VERSION "created by canmatrix"

NS_ :

BS_:

BU_: TCM iBooster HCU CIM SCM Right_Hand_Control Left_Hand_Control GPS VCM IC_2 XM GMRS Radio_CANtool Diagnostic_Tool_Digital_Wrench Information_System_Controller_1 STEERING_CONTROLLER VEHICLE_SECURITY RADIO_Hub ABS Battery_Management_Cntrl_2 Battery_Management_Cntrl_1 Auxiliary_Power_Unit_2 Auxiliary_Power_Unit_1 Electric_Propulsion_Cntrl_Unit_4 Electric_Propulsion_Cntrl_Unit_3 Electric_Propulsion_Cntrl_Unit_2 Electric_Propulsion_Cntrl_Unit_1 ECM IC

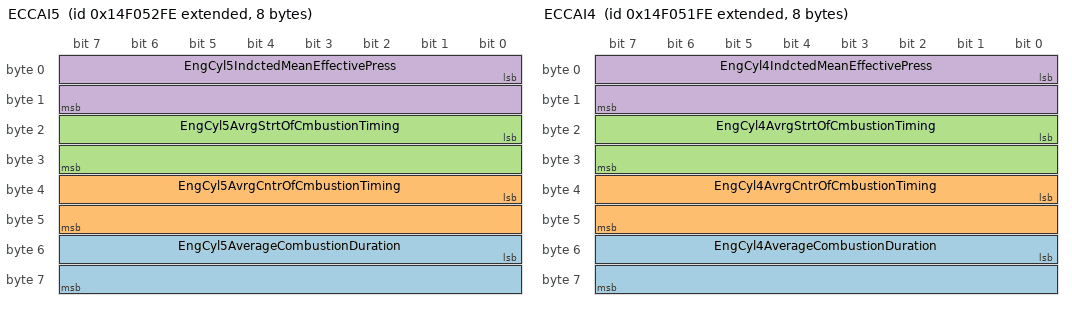
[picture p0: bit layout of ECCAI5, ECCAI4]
BO_ 2498777854 ECCAI5: 8 Vector__XXX
 SG_ EngCyl5AverageCombustionDuration : 48|16@1+ (0.0078125,0) [0.0|501.99] "deg" Vector__XXX
 SG_ EngCyl5AvrgCntrOfCmbustionTiming : 32|16@1+ (0.0078125,-250) [-250.0|250.992] "deg" Vector__XXX
 SG_ EngCyl5AvrgStrtOfCmbustionTiming : 16|16@1+ (0.0078125,-250) [-250.0|250.992] "deg" Vector__XXX
 SG_ EngCyl5IndctedMeanEffectivePress : 0|16@1+ (0.00012207,-1) [-1.0|6.84362793] "MPa" Vector__XXX

BO_ 2498777598 ECCAI4: 8 Vector__XXX
 SG_ EngCyl4AverageCombustionDuration : 48|16@1+ (0.0078125,0) [0.0|501.99] "deg" Vector__XXX
 SG_ EngCyl4AvrgCntrOfCmbustionTiming : 32|16@1+ (0.0078125,-250) [-250.0|250.992] "deg" Vector__XXX
 SG_ EngCyl4AvrgStrtOfCmbustionTiming : 16|16@1+ (0.0078125,-250) [-250.0|250.992] "deg" Vector__XXX
 SG_ EngCyl4IndctedMeanEffectivePress : 0|16@1+ (0.00012207,-1) [-1.0|6.84362793] "MPa" Vector__XXX

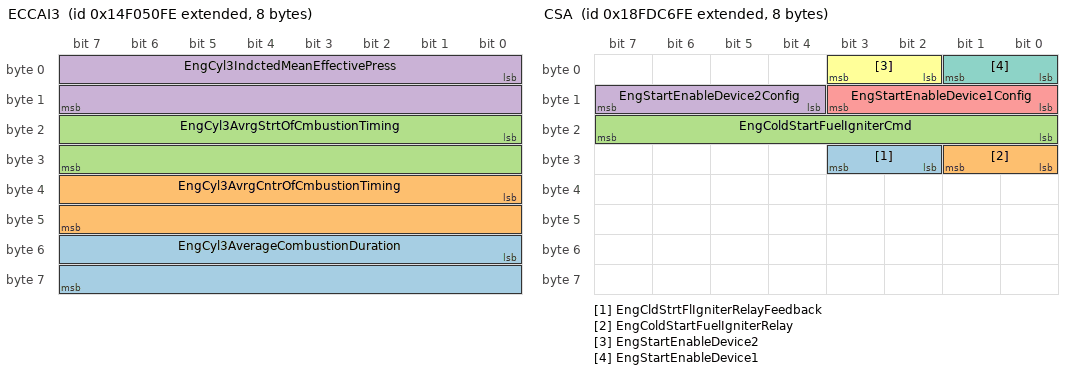
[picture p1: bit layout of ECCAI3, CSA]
BO_ 2498777342 ECCAI3: 8 Vector__XXX
 SG_ EngCyl3AverageCombustionDuration : 48|16@1+ (0.0078125,0) [0.0|501.99] "deg" Vector__XXX
 SG_ EngCyl3AvrgCntrOfCmbustionTiming : 32|16@1+ (0.0078125,-250) [-250.0|250.992] "deg" Vector__XXX
 SG_ EngCyl3AvrgStrtOfCmbustionTiming : 16|16@1+ (0.0078125,-250) [-250.0|250.992] "deg" Vector__XXX
 SG_ EngCyl3IndctedMeanEffectivePress : 0|16@1+ (0.00012207,-1) [-1.0|6.84362793] "MPa" Vector__XXX

BO_ 2566768382 CSA: 8 Vector__XXX
 SG_ EngCldStrtFlIgniterRelayFeedback : 26|2@1+ (1,0) [0.0|3.0] "" Vector__XXX
 SG_ EngColdStartFuelIgniterRelay : 24|2@1+ (1,0) [0.0|3.0] "" Vector__XXX
 SG_ EngColdStartFuelIgniterCmd : 16|8@1+ (0.4,0) [0.0|100.0] "%" Vector__XXX
 SG_ EngStartEnableDevice2Config : 12|4@1+ (1,0) [0.0|15.0] "" Vector__XXX
 SG_ EngStartEnableDevice1Config : 8|4@1+ (1,0) [0.0|15.0] "" Vector__XXX
 SG_ EngStartEnableDevice2 : 2|2@1+ (1,0) [0.0|3.0] "" Vector__XXX
 SG_ EngStartEnableDevice1 : 0|2@1+ (1,0) [0.0|3.0] "" Vector__XXX

BO_ 2566811902 CVW: 8 Vector__XXX
 SG_ PoweredVehicleWeight : 0|16@1+ (10,0) [0.0|642550.0] "kg" Vector__XXX
 SG_ GrossCombinationVehicleWeight : 16|16@1+ (10,0) [0.0|642550.0] "kg" Vector__XXX

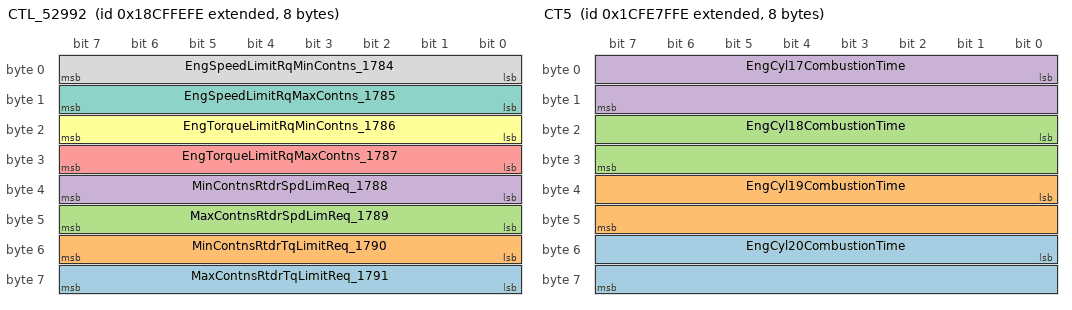
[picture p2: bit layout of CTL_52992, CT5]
BO_ 2563768062 CTL_52992: 8 Vector__XXX
 SG_ MaxContnsRtdrTqLimitReq_1791 : 56|8@1+ (1,-125) [-125.0|0.0] "%" Vector__XXX
 SG_ MinContnsRtdrTqLimitReq_1790 : 48|8@1+ (1,-125) [-125.0|0.0] "%" Vector__XXX
 SG_ MaxContnsRtdrSpdLimReq_1789 : 40|8@1+ (32,0) [0.0|8000.0] "rpm" Vector__XXX
 SG_ MinContnsRtdrSpdLimReq_1788 : 32|8@1+ (32,0) [0.0|8000.0] "rpm" Vector__XXX
 SG_ EngTorqueLimitRqMaxContns_1787 : 24|8@1+ (1,-125) [0.0|125.0] "%" Vector__XXX
 SG_ EngTorqueLimitRqMinContns_1786 : 16|8@1+ (1,-125) [0.0|125.0] "%" Vector__XXX
 SG_ EngSpeedLimitRqMaxContns_1785 : 8|8@1+ (32,0) [0.0|8000.0] "rpm" Vector__XXX
 SG_ EngSpeedLimitRqMinContns_1784 : 0|8@1+ (32,0) [0.0|8000.0] "rpm" Vector__XXX

BO_ 2633924862 CT6: 8 Vector__XXX
 SG_ EngAverageCombustionTime : 16|16@1+ (0.01,0) [0.0|642.55] "ms" Vector__XXX
 SG_ EngDesiredCombustionTime : 0|16@1+ (0.01,0) [0.0|642.55] "ms" Vector__XXX

BO_ 2633924606 CT5: 8 Vector__XXX
 SG_ EngCyl20CombustionTime : 48|16@1+ (0.01,0) [0.0|642.55] "ms" Vector__XXX
 SG_ EngCyl19CombustionTime : 32|16@1+ (0.01,0) [0.0|642.55] "ms" Vector__XXX
 SG_ EngCyl18CombustionTime : 16|16@1+ (0.01,0) [0.0|642.55] "ms" Vector__XXX
 SG_ EngCyl17CombustionTime : 0|16@1+ (0.01,0) [0.0|642.55] "ms" Vector__XXX

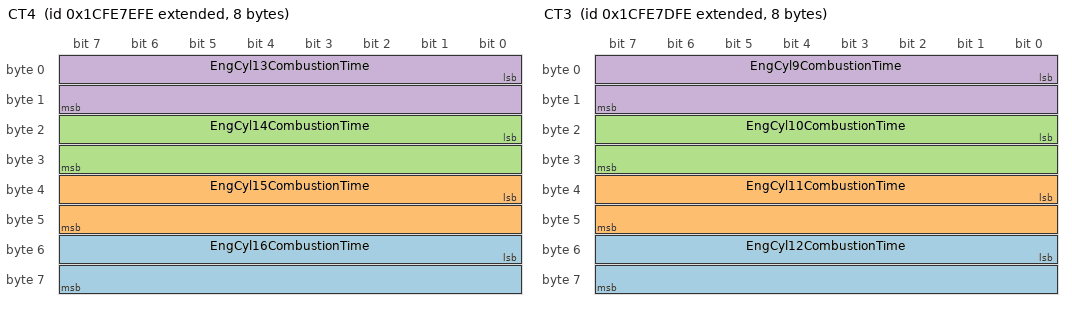
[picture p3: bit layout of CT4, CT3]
BO_ 2633924350 CT4: 8 Vector__XXX
 SG_ EngCyl16CombustionTime : 48|16@1+ (0.01,0) [0.0|642.55] "ms" Vector__XXX
 SG_ EngCyl15CombustionTime : 32|16@1+ (0.01,0) [0.0|642.55] "ms" Vector__XXX
 SG_ EngCyl14CombustionTime : 16|16@1+ (0.01,0) [0.0|642.55] "ms" Vector__XXX
 SG_ EngCyl13CombustionTime : 0|16@1+ (0.01,0) [0.0|642.55] "ms" Vector__XXX

BO_ 2633924094 CT3: 8 Vector__XXX
 SG_ EngCyl12CombustionTime : 48|16@1+ (0.01,0) [0.0|642.55] "ms" Vector__XXX
 SG_ EngCyl11CombustionTime : 32|16@1+ (0.01,0) [0.0|642.55] "ms" Vector__XXX
 SG_ EngCyl10CombustionTime : 16|16@1+ (0.01,0) [0.0|642.55] "ms" Vector__XXX
 SG_ EngCyl9CombustionTime : 0|16@1+ (0.01,0) [0.0|642.55] "ms" Vector__XXX

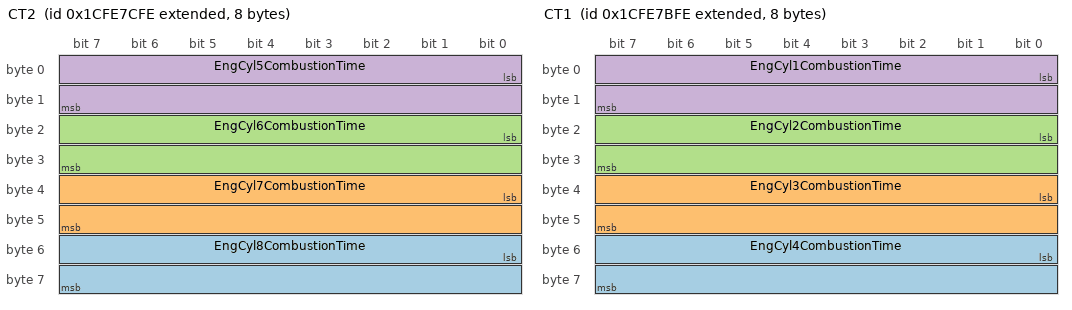
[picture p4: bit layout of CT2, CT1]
BO_ 2633923838 CT2: 8 Vector__XXX
 SG_ EngCyl8CombustionTime : 48|16@1+ (0.01,0) [0.0|642.55] "ms" Vector__XXX
 SG_ EngCyl7CombustionTime : 32|16@1+ (0.01,0) [0.0|642.55] "ms" Vector__XXX
 SG_ EngCyl6CombustionTime : 16|16@1+ (0.01,0) [0.0|642.55] "ms" Vector__XXX
 SG_ EngCyl5CombustionTime : 0|16@1+ (0.01,0) [0.0|642.55] "ms" Vector__XXX

BO_ 2633923582 CT1: 8 Vector__XXX
 SG_ EngCyl4CombustionTime : 48|16@1+ (0.01,0) [0.0|642.55] "ms" Vector__XXX
 SG_ EngCyl3CombustionTime : 32|16@1+ (0.01,0) [0.0|642.55] "ms" Vector__XXX
 SG_ EngCyl2CombustionTime : 16|16@1+ (0.01,0) [0.0|642.55] "ms" Vector__XXX
 SG_ EngCyl1CombustionTime : 0|16@1+ (0.01,0) [0.0|642.55] "ms" Vector__XXX

BO_ 2633878014 CMI: 8 Vector__XXX
 SG_ TotalCountOfConfigChangesMade : 0|16@1+ (1,0) [0.0|64255.0] "" Vector__XXX

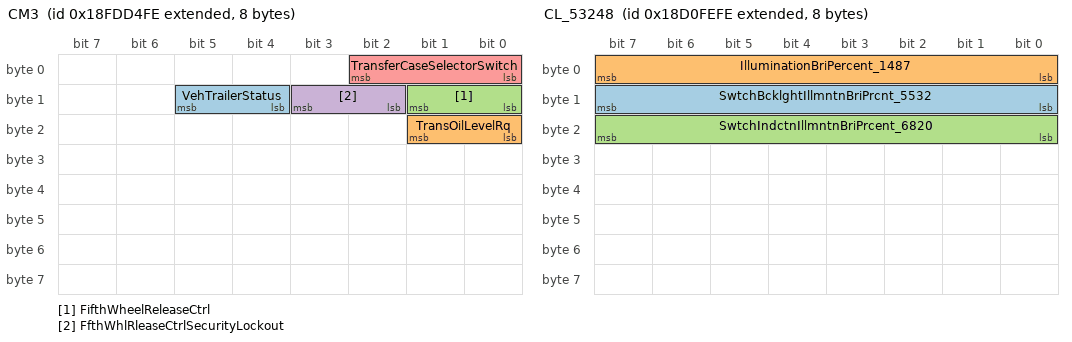
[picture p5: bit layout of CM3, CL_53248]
BO_ 2566771966 CM3: 8 Vector__XXX
 SG_ VehTrailerStatus : 12|2@1+ (1,0) [0.0|3.0] "" Vector__XXX
 SG_ TransOilLevelRq : 16|2@1+ (1,0) [0.0|3.0] "" Vector__XXX
 SG_ FifthWheelReleaseCtrl : 8|2@1+ (1,0) [0.0|3.0] "" Vector__XXX
 SG_ FfthWhlRleaseCtrlSecurityLockout : 10|2@1+ (1,0) [0.0|3.0] "" Vector__XXX
 SG_ TransferCaseSelectorSwitch : 0|3@1+ (1,0) [0.0|7.0] "" Vector__XXX

BO_ 2564882174 CM1_57344: 8 Vector__XXX
 SG_ SeldMaxVehSpdLimit_2596 : 56|8@1+ (1,0) [0.0|250.0] "" Vector__XXX
 SG_ ReqCabZoneHeating_1686 : 54|2@1+ (1,0) [0.0|3.0] "" Vector__XXX
 SG_ ReqEngZoneHeating_1685 : 52|2@1+ (1,0) [0.0|3.0] "" Vector__XXX
 SG_ AuxHeaterModeReq_1683 : 48|4@1+ (1,0) [0.0|15.0] "" Vector__XXX
 SG_ EngAutomaticStartEnableSw_1656 : 46|2@1+ (1,0) [0.0|3.0] "" Vector__XXX
 SG_ AtuomaticGearShiftingEnSw_1666 : 44|2@1+ (1,0) [0.0|3.0] "" Vector__XXX
 SG_ AFTRegenForceSw_3696 : 42|2@1+ (1,0) [0.0|3.0] "" Vector__XXX
 SG_ AFTRegenInhSw_3695 : 40|2@1+ (1,0) [0.0|3.0] "" Vector__XXX
 SG_ VehLmtngSpdGovrEnSw_1653 : 38|2@1+ (1,0) [0.0|3.0] "" Vector__XXX
 SG_ VehLmtngSpdGvrnrIncrementSw_1654 : 36|2@1+ (1,0) [0.0|3.0] "" Vector__XXX
 SG_ VehLmtngSpdGvrnrDecrementSw_1655 : 34|2@1+ (1,0) [0.0|3.0] "" Vector__XXX
 SG_ ParkBrakeCmd_5630 : 32|2@1+ (1,0) [0.0|3.0] "" Vector__XXX
 SG_ SeatBeltSwitch_1856 : 30|2@1+ (1,0) [0.0|3.0] "" Vector__XXX
 SG_ OperatorSeatDirSw_1714 : 28|2@1+ (1,0) [0.0|3.0] "" Vector__XXX
 SG_ BatteryMainSwitchHoldRq_1682 : 26|2@1+ (1,0) [0.0|3.0] "" Vector__XXX
 SG_ AuxHeaterCoolantPumpRq_1684 : 24|2@1+ (1,0) [0.0|3.0] "" Vector__XXX
 SG_ CabInteriorTempCmd_1691 : 8|16@1+ (0.03125,-273) [-273.0|1734.96875] "°C" Vector__XXX
 SG_ RequestedPercentFanSpeed_986 : 0|8@1+ (0.4,0) [0.0|100.0] "%" Vector__XXX

BO_ 2563833598 CL_53248: 8 Vector__XXX
 SG_ SwtchBcklghtIllmntnBriPrcnt_5532 : 8|8@1+ (0.4,0) [0.0|100.0] "%" Vector__XXX
 SG_ IlluminationBriPercent_1487 : 0|8@1+ (0.4,0) [0.0|100.0] "%" Vector__XXX
 SG_ SwtchIndctnIllmntnBriPrcent_6820 : 16|8@1+ (0.4,0) [0.0|100.0] "%" Vector__XXX

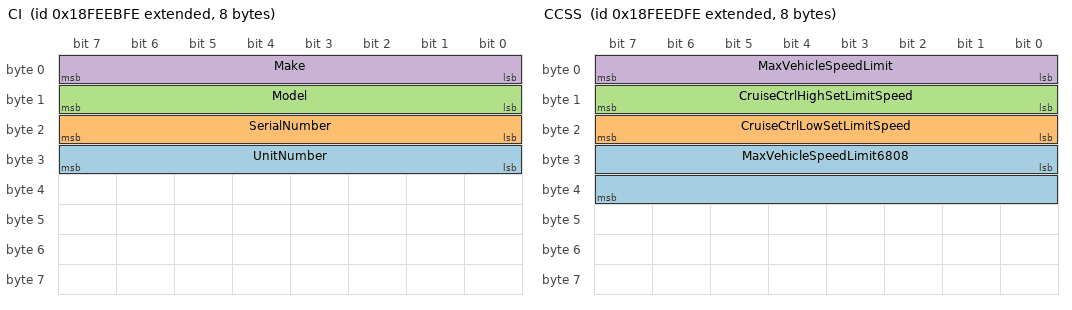
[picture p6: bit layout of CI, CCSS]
BO_ 2566843390 CI: 8 Vector__XXX
 SG_ UnitNumber : 24|8@1+ (1,0) [0.0|255.0] "" Vector__XXX
 SG_ SerialNumber : 16|8@1+ (1,0) [0.0|255.0] "" Vector__XXX
 SG_ Model : 8|8@1+ (1,0) [0.0|255.0] "" Vector__XXX
 SG_ Make : 0|8@1+ (1,0) [0.0|255.0] "" Vector__XXX

BO_ 2566844926 CCVS1: 8 Vector__XXX
 SG_ EngShutdownOverrideSwitch : 62|2@1+ (1,0) [0.0|3.0] "" Vector__XXX
 SG_ EngTestModeSwitch : 60|2@1+ (1,0) [0.0|3.0] "" Vector__XXX
 SG_ EngIdleDecrementSwitch : 58|2@1+ (1,0) [0.0|3.0] "" Vector__XXX
 SG_ EngIdleIncrementSwitch : 56|2@1+ (1,0) [0.0|3.0] "" Vector__XXX
 SG_ CruiseCtrlStates : 53|3@1+ (1,0) [0.0|7.0] "" Vector__XXX
 SG_ PTOGovernorState : 48|5@1+ (1,0) [0.0|31.0] "" Vector__XXX
 SG_ CruiseCtrlSetSpeed : 40|8@1+ (1,0) [0.0|250.0] "km/h" Vector__XXX
 SG_ CruiseCtrlAccelerateSwitch : 38|2@1+ (1,0) [0.0|3.0] "" Vector__XXX
 SG_ CruiseCtrlResumeSwitch : 36|2@1+ (1,0) [0.0|3.0] "" Vector__XXX
 SG_ CruiseCtrlCoastSwitch : 34|2@1+ (1,0) [0.0|3.0] "" Vector__XXX
 SG_ CruiseCtrlSetSwitch : 32|2@1+ (1,0) [0.0|3.0] "" Vector__XXX
 SG_ ClutchSwitch : 30|2@1+ (1,0) [0.0|3.0] "" Vector__XXX
 SG_ BrakeSwitch : 28|2@1+ (1,0) [0.0|3.0] "" Vector__XXX
 SG_ CruiseCtrlEnableSwitch : 26|2@1+ (1,0) [0.0|3.0] "" Vector__XXX
 SG_ CruiseCtrlActive : 24|2@1+ (1,0) [0.0|3.0] "" Vector__XXX
 SG_ WheelBasedVehicleSpeed : 8|16@1+ (0.00390625,0) [0.0|250.996] "km/h" Vector__XXX
 SG_ ParkBrakeReleaseInhibitRq : 6|2@1+ (1,0) [0.0|3.0] "" Vector__XXX
 SG_ CruiseCtrlPauseSwitch : 4|2@1+ (1,0) [0.0|3.0] "" Vector__XXX
 SG_ ParkingBrakeSwitch : 2|2@1+ (1,0) [0.0|3.0] "" Vector__XXX
 SG_ TwoSpeedAxleSwitch : 0|2@1+ (1,0) [0.0|3.0] "" Vector__XXX

BO_ 2566843902 CCSS: 8 Vector__XXX
 SG_ MaxVehicleSpeedLimit6808 : 24|16@1+ (0.00390625,0) [0.0|250.996] "km/h" Vector__XXX
 SG_ CruiseCtrlLowSetLimitSpeed : 16|8@1+ (1,0) [0.0|250.0] "km/h" Vector__XXX
 SG_ CruiseCtrlHighSetLimitSpeed : 8|8@1+ (1,0) [0.0|250.0] "km/h" Vector__XXX
 SG_ MaxVehicleSpeedLimit : 0|8@1+ (1,0) [0.0|250.0] "km/h" Vector__XXX

BO_ 2566809598 CCC: 8 Vector__XXX
 SG_ AuxHeaterMaxOutputPower : 0|16@1+ (2,0) [0.0|128510.0] "W" Vector__XXX

BO_ 2633940222 CBI: 16 Vector__XXX
 SG_ TripServiceBrakeApplications : 96|32@1+ (1,0) [0.0|4211081215.0] "appl" Vector__XXX
 SG_ TripServiceBrakeDistance : 64|32@1+ (0.125,0) [0.0|526385151.875] "km" Vector__XXX
 SG_ TripCompressionBrakeDistance : 32|32@1+ (0.125,0) [0.0|526385151.875] "km" Vector__XXX
 SG_ TotalCompressionBrakeDistance : 0|32@1+ (0.125,0) [0.0|526385151.875] "km" Vector__XXX

BO_ 2566775294 CACI: 8 Vector__XXX
 SG_ CbA_CRfrgrntCmpressorOutletPress : 0|8@1+ (16,0) [0.0|4000.0] "kPa" Vector__XXX

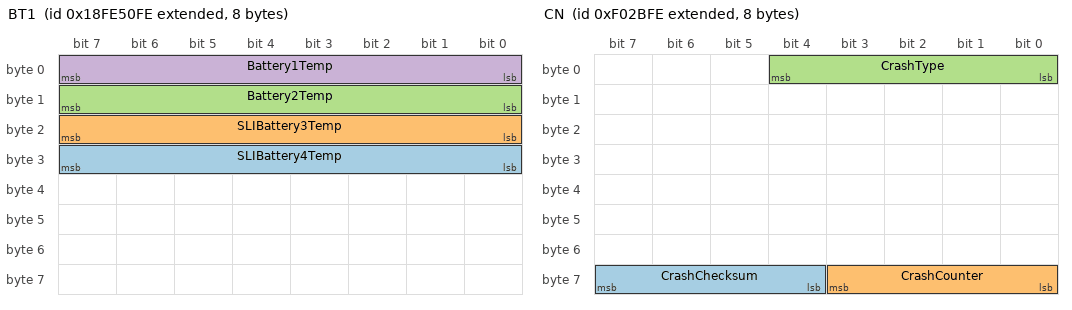
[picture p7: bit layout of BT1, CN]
BO_ 2566803710 BT1: 8 Vector__XXX
 SG_ SLIBattery4Temp : 24|8@1+ (1,-40) [-40.0|210.0] "°C" Vector__XXX
 SG_ SLIBattery3Temp : 16|8@1+ (1,-40) [-40.0|210.0] "°C" Vector__XXX
 SG_ Battery2Temp : 8|8@1+ (1,-40) [-40.0|210.0] "°C" Vector__XXX
 SG_ Battery1Temp : 0|8@1+ (1,-40) [-40.0|210.0] "°C" Vector__XXX

BO_ 2566719486 DLCC1: 8 Vector__XXX
 SG_ VhclAccelerationRateLimitLampCmd : 34|2@1+ (1,0) [0.0|3.0] "" Vector__XXX
 SG_ EngSpeedVeryHighLampCmd : 32|2@1+ (1,0) [0.0|3.0] "" Vector__XXX
 SG_ EngSpeedHighLampCmd : 30|2@1+ (1,0) [0.0|3.0] "" Vector__XXX
 SG_ EngCtrlModule3ReadyForUseLampCmd : 28|2@1+ (1,0) [0.0|3.0] "" Vector__XXX
 SG_ EngCtrlModule2ReadyForUseLampCmd : 26|2@1+ (1,0) [0.0|3.0] "" Vector__XXX
 SG_ EngCtrlModule1ReadyForUseLampCmd : 24|2@1+ (1,0) [0.0|3.0] "" Vector__XXX
 SG_ EngFuelFilterRestrictedLampCmd : 22|2@1+ (1,0) [0.0|3.0] "" Vector__XXX
 SG_ EngAirFilterRestrictionLampCmd : 20|2@1+ (1,0) [0.0|3.0] "" Vector__XXX
 SG_ EngIdleManagementActiveLampCmd : 18|2@1+ (1,0) [0.0|3.0] "" Vector__XXX
 SG_ EngCoolantLevelLowLampCmd : 16|2@1+ (1,0) [0.0|3.0] "" Vector__XXX
 SG_ EngCoolantTempHighLampCmd : 14|2@1+ (1,0) [0.0|3.0] "" Vector__XXX
 SG_ EngOilPressLowLampCmd : 12|2@1+ (1,0) [0.0|3.0] "" Vector__XXX
 SG_ CmprssnBrkEnblSwtchIndctrLampCmd : 10|2@1+ (1,0) [0.0|3.0] "" Vector__XXX
 SG_ EngBrakeActiveLampCmd : 8|2@1+ (1,0) [0.0|3.0] "" Vector__XXX
 SG_ OBDMalfunctionIndicatorLampCmd : 6|2@1+ (1,0) [0.0|3.0] "" Vector__XXX
 SG_ EngRedStopLampCmd : 4|2@1+ (1,0) [0.0|3.0] "" Vector__XXX
 SG_ EngAmberWarningLampCmd : 2|2@1+ (1,0) [0.0|3.0] "" Vector__XXX
 SG_ EngProtectLampCmd : 0|2@1+ (1,0) [0.0|3.0] "" Vector__XXX

BO_ 2633832702 CSI: 8 Vector__XXX
 SG_ RolloverSensorType : 64|4@1+ (1,0) [0.0|15.0] "" Vector__XXX
 SG_ RearCollisionSensor4Type : 60|4@1+ (1,0) [0.0|15.0] "" Vector__XXX
 SG_ RearCollisionSensor3Type : 56|4@1+ (1,0) [0.0|15.0] "" Vector__XXX
 SG_ RearCollisionSensor2Type : 52|4@1+ (1,0) [0.0|15.0] "" Vector__XXX
 SG_ RearCollisionSensor1Type : 48|4@1+ (1,0) [0.0|15.0] "" Vector__XXX
 SG_ SideCollisionSensorRearRightType : 44|4@1+ (1,0) [0.0|15.0] "" Vector__XXX
 SG_ SdCllisionSensorMidRearRightType : 40|4@1+ (1,0) [0.0|15.0] "" Vector__XXX
 SG_ SdCllsionSensorMidFrontRightType : 36|4@1+ (1,0) [0.0|15.0] "" Vector__XXX
 SG_ SdeCollisionSensorFrontRightType : 32|4@1+ (1,0) [0.0|15.0] "" Vector__XXX
 SG_ SideCollisionSensorRearLeftType : 28|4@1+ (1,0) [0.0|15.0] "" Vector__XXX
 SG_ SdCollisionSensorMidRearLeftType : 24|4@1+ (1,0) [0.0|15.0] "" Vector__XXX
 SG_ SdCllisionSensorMidFrontLeftType : 20|4@1+ (1,0) [0.0|15.0] "" Vector__XXX
 SG_ SideCollisionSensorFrontLeftType : 16|4@1+ (1,0) [0.0|15.0] "" Vector__XXX
 SG_ FrontalCollisionSensor4Type : 12|4@1+ (1,0) [0.0|15.0] "" Vector__XXX
 SG_ FrontalCollisionSensor3Type : 8|4@1+ (1,0) [0.0|15.0] "" Vector__XXX
 SG_ FrontalCollisionSensor2Type : 4|4@1+ (1,0) [0.0|15.0] "" Vector__XXX
 SG_ FrontalCollisionSensor1Type : 0|4@1+ (1,0) [0.0|15.0] "" Vector__XXX

BO_ 2163223550 CN: 8 Vector__XXX
 SG_ CrashChecksum : 60|4@1+ (1,0) [0.0|15.0] "" Vector__XXX
 SG_ CrashCounter : 56|4@1+ (1,0) [0.0|15.0] "" Vector__XXX
 SG_ CrashType : 0|5@1+ (1,0) [0.0|0.0] "" Vector__XXX

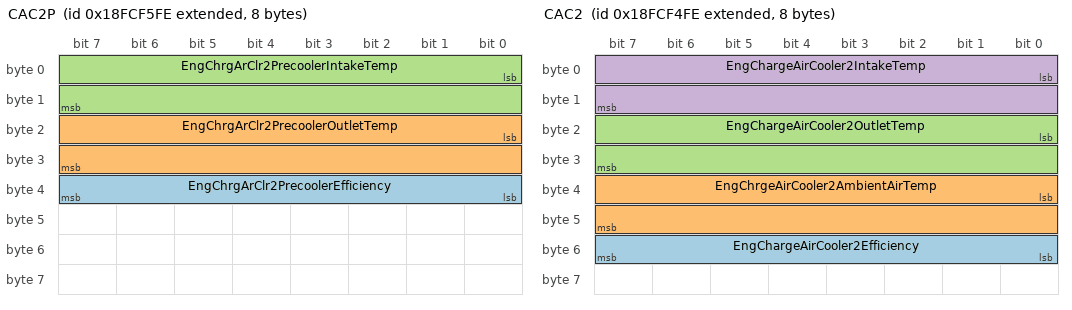
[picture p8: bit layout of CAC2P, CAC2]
BO_ 2566714878 CAC2P: 8 Vector__XXX
 SG_ EngChrgArClr2PrecoolerEfficiency : 32|8@1+ (0.4,0) [0.0|100.0] "%" Vector__XXX
 SG_ EngChrgArClr2PrecoolerOutletTemp : 16|16@1+ (0.03125,-273) [-273.0|1734.96875] "°C" Vector__XXX
 SG_ EngChrgArClr2PrecoolerIntakeTemp : 0|16@1+ (0.03125,-273) [-273.0|1734.96875] "°C" Vector__XXX

BO_ 2566714622 CAC2: 8 Vector__XXX
 SG_ EngChargeAirCooler2Efficiency : 48|8@1+ (0.4,0) [0.0|100.0] "%" Vector__XXX
 SG_ EngChrgeAirCooler2AmbientAirTemp : 32|16@1+ (0.03125,-273) [-273.0|1734.96875] "°C" Vector__XXX
 SG_ EngChargeAirCooler2OutletTemp : 16|16@1+ (0.03125,-273) [-273.0|1734.96875] "°C" Vector__XXX
 SG_ EngChargeAirCooler2IntakeTemp : 0|16@1+ (0.03125,-273) [-273.0|1734.96875] "°C" Vector__XXX

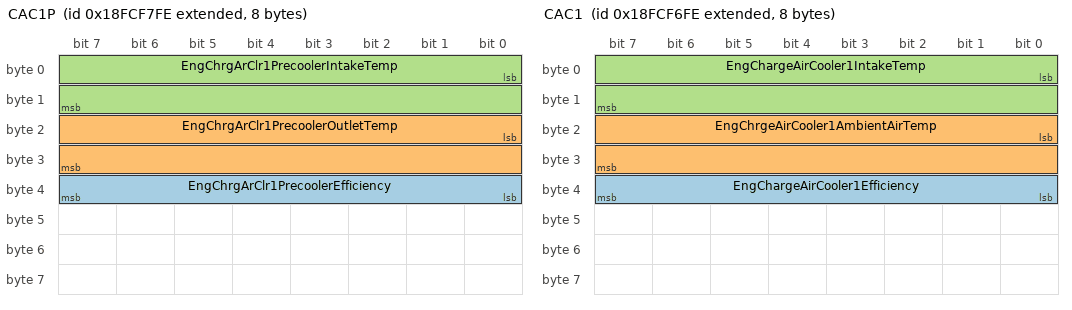
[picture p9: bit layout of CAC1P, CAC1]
BO_ 2566715390 CAC1P: 8 Vector__XXX
 SG_ EngChrgArClr1PrecoolerEfficiency : 32|8@1+ (0.4,0) [0.0|100.0] "%" Vector__XXX
 SG_ EngChrgArClr1PrecoolerOutletTemp : 16|16@1+ (0.03125,-273) [-273.0|1734.96875] "°C" Vector__XXX
 SG_ EngChrgArClr1PrecoolerIntakeTemp : 0|16@1+ (0.03125,-273) [-273.0|1734.96875] "°C" Vector__XXX

BO_ 2566715134 CAC1: 8 Vector__XXX
 SG_ EngChargeAirCooler1Efficiency : 32|8@1+ (0.4,0) [0.0|100.0] "%" Vector__XXX
 SG_ EngChrgeAirCooler1AmbientAirTemp : 16|16@1+ (0.03125,-273) [-273.0|1734.96875] "°C" Vector__XXX
 SG_ EngChargeAirCooler1IntakeTemp : 0|16@1+ (0.03125,-273) [-273.0|1734.96875] "°C" Vector__XXX

BO_ 2365400830 BJM9: 8 Vector__XXX
 SG_ Joystick9Button9PressedStatus : 62|2@1+ (1,0) [0.0|3.0] "" Vector__XXX
 SG_ Joystick9Button10PressedStatus : 60|2@1+ (1,0) [0.0|3.0] "" Vector__XXX
 SG_ Joystick9Button11PressedStatus : 58|2@1+ (1,0) [0.0|3.0] "" Vector__XXX
 SG_ Joystick9Button12PressedStatus : 56|2@1+ (1,0) [0.0|3.0] "" Vector__XXX
 SG_ Joystick9Button5PressedStatus : 54|2@1+ (1,0) [0.0|3.0] "" Vector__XXX
 SG_ Joystick9Button6PressedStatus : 52|2@1+ (1,0) [0.0|3.0] "" Vector__XXX
 SG_ Joystick9Button7PressedStatus : 50|2@1+ (1,0) [0.0|3.0] "" Vector__XXX
 SG_ Joystick9Button8PressedStatus : 48|2@1+ (1,0) [0.0|3.0] "" Vector__XXX
 SG_ Joystick9Button1PressedStatus : 46|2@1+ (1,0) [0.0|3.0] "" Vector__XXX
 SG_ Joystick9Button2PressedStatus : 44|2@1+ (1,0) [0.0|3.0] "" Vector__XXX
 SG_ Joystick9Button3PressedStatus : 42|2@1+ (1,0) [0.0|3.0] "" Vector__XXX
 SG_ Joystick9Button4PressedStatus : 40|2@1+ (1,0) [0.0|3.0] "" Vector__XXX
 SG_ Joystick9XAxisDetentPosStatus : 38|2@1+ (1,0) [0.0|3.0] "" Vector__XXX
 SG_ Joystick9YAxisDetentPosStatus : 36|2@1+ (1,0) [0.0|3.0] "" Vector__XXX
 SG_ Joystick9YAxisPos : 22|10@1+ (0.1,0) [0.0|102.0] "%" Vector__XXX
 SG_ Jystck9YAxsLvrFrwrdPstvPosStatus : 20|2@1+ (1,0) [0.0|3.0] "" Vector__XXX
 SG_ Jystck9YAxsLvrBckNgtivePosStatus : 18|2@1+ (1,0) [0.0|3.0] "" Vector__XXX
 SG_ Joystick9YAxisNeutralPosStatus : 16|2@1+ (1,0) [0.0|3.0] "" Vector__XXX
 SG_ Joystick9XAxisPos : 6|10@1+ (0.1,0) [0.0|102.0] "%" Vector__XXX
 SG_ Jystck9XAxsLvrRghtPstvePosStatus : 4|2@1+ (1,0) [0.0|3.0] "" Vector__XXX
 SG_ Jystck9XAxsLvrLftNgtivePosStatus : 2|2@1+ (1,0) [0.0|3.0] "" Vector__XXX
 SG_ Joystick9XAxisNeutralPosStatus : 0|2@1+ (1,0) [0.0|3.0] "" Vector__XXX

BO_ 2365401342 BJM8: 8 Vector__XXX
 SG_ Joystick8Button9PressedStatus : 62|2@1+ (1,0) [0.0|3.0] "" Vector__XXX
 SG_ Joystick8Button10PressedStatus : 60|2@1+ (1,0) [0.0|3.0] "" Vector__XXX
 SG_ Joystick8Button11PressedStatus : 58|2@1+ (1,0) [0.0|3.0] "" Vector__XXX
 SG_ Joystick8Button12PressedStatus : 56|2@1+ (1,0) [0.0|3.0] "" Vector__XXX
 SG_ Joystick8Button5PressedStatus : 54|2@1+ (1,0) [0.0|3.0] "" Vector__XXX
 SG_ Joystick8Button6PressedStatus : 52|2@1+ (1,0) [0.0|3.0] "" Vector__XXX
 SG_ Joystick8Button7PressedStatus : 50|2@1+ (1,0) [0.0|3.0] "" Vector__XXX
 SG_ Joystick8Button8PressedStatus : 48|2@1+ (1,0) [0.0|3.0] "" Vector__XXX
 SG_ Joystick8Button1PressedStatus : 46|2@1+ (1,0) [0.0|3.0] "" Vector__XXX
 SG_ Joystick8Button2PressedStatus : 44|2@1+ (1,0) [0.0|3.0] "" Vector__XXX
 SG_ Joystick8Button3PressedStatus : 42|2@1+ (1,0) [0.0|3.0] "" Vector__XXX
 SG_ Joystick8Button4PressedStatus : 40|2@1+ (1,0) [0.0|3.0] "" Vector__XXX
 SG_ Joystick8XAxisDetentPosStatus : 38|2@1+ (1,0) [0.0|3.0] "" Vector__XXX
 SG_ Joystick8YAxisDetentPosStatus : 36|2@1+ (1,0) [0.0|3.0] "" Vector__XXX
 SG_ Joystick8YAxisPos : 22|10@1+ (0.1,0) [0.0|102.0] "%" Vector__XXX
 SG_ Jystck8YAxsLvrFrwrdPstvPosStatus : 20|2@1+ (1,0) [0.0|3.0] "" Vector__XXX
 SG_ Jystck8YAxsLvrBckNgtivePosStatus : 18|2@1+ (1,0) [0.0|3.0] "" Vector__XXX
 SG_ Joystick8YAxisNeutralPosStatus : 16|2@1+ (1,0) [0.0|3.0] "" Vector__XXX
 SG_ Joystick8XAxisPos : 6|10@1+ (0.1,0) [0.0|102.0] "%" Vector__XXX
 SG_ Jystck8XAxsLvrRghtPstvePosStatus : 4|2@1+ (1,0) [0.0|3.0] "" Vector__XXX
 SG_ Jystck8XAxsLvrLftNgtivePosStatus : 2|2@1+ (1,0) [0.0|3.0] "" Vector__XXX
 SG_ Joystick8XAxisNeutralPosStatus : 0|2@1+ (1,0) [0.0|3.0] "" Vector__XXX

BO_ 2365401854 BJM7: 8 Vector__XXX
 SG_ Joystick7Button9PressedStatus : 62|2@1+ (1,0) [0.0|3.0] "" Vector__XXX
 SG_ Joystick7Button10PressedStatus : 60|2@1+ (1,0) [0.0|3.0] "" Vector__XXX
 SG_ Joystick7Button11PressedStatus : 58|2@1+ (1,0) [0.0|3.0] "" Vector__XXX
 SG_ Joystick7Button12PressedStatus : 56|2@1+ (1,0) [0.0|3.0] "" Vector__XXX
 SG_ Joystick7Button5PressedStatus : 54|2@1+ (1,0) [0.0|3.0] "" Vector__XXX
 SG_ Joystick7Button6PressedStatus : 52|2@1+ (1,0) [0.0|3.0] "" Vector__XXX
 SG_ Joystick7Button7PressedStatus : 50|2@1+ (1,0) [0.0|3.0] "" Vector__XXX
 SG_ Joystick7Button8PressedStatus : 48|2@1+ (1,0) [0.0|3.0] "" Vector__XXX
 SG_ Joystick7Button1PressedStatus : 46|2@1+ (1,0) [0.0|3.0] "" Vector__XXX
 SG_ Joystick7Button2PressedStatus : 44|2@1+ (1,0) [0.0|3.0] "" Vector__XXX
 SG_ Joystick7Button3PressedStatus : 42|2@1+ (1,0) [0.0|3.0] "" Vector__XXX
 SG_ Joystick7Button4PressedStatus : 40|2@1+ (1,0) [0.0|3.0] "" Vector__XXX
 SG_ Joystick7XAxisDetentPosStatus : 38|2@1+ (1,0) [0.0|3.0] "" Vector__XXX
 SG_ Joystick7YAxisDetentPosStatus : 36|2@1+ (1,0) [0.0|3.0] "" Vector__XXX
 SG_ Joystick7YAxisPos : 22|10@1+ (0.1,0) [0.0|102.0] "%" Vector__XXX
 SG_ Jystck7YAxsLvrFrwrdPstvPosStatus : 20|2@1+ (1,0) [0.0|3.0] "" Vector__XXX
 SG_ Jystck7YAxsLvrBckNgtivePosStatus : 18|2@1+ (1,0) [0.0|3.0] "" Vector__XXX
 SG_ Joystick7YAxisNeutralPosStatus : 16|2@1+ (1,0) [0.0|3.0] "" Vector__XXX
 SG_ Joystick7XAxisPos : 6|10@1+ (0.1,0) [0.0|102.0] "%" Vector__XXX
 SG_ Jystck7XAxsLvrRghtPstvePosStatus : 4|2@1+ (1,0) [0.0|3.0] "" Vector__XXX
 SG_ Jystck7XAxsLvrLftNgtivePosStatus : 2|2@1+ (1,0) [0.0|3.0] "" Vector__XXX
 SG_ Joystick7XAxisNeutralPosStatus : 0|2@1+ (1,0) [0.0|3.0] "" Vector__XXX

BO_ 2365402366 BJM6: 8 Vector__XXX
 SG_ Joystick6Button9PressedStatus : 62|2@1+ (1,0) [0.0|3.0] "" Vector__XXX
 SG_ Joystick6Button10PressedStatus : 60|2@1+ (1,0) [0.0|3.0] "" Vector__XXX
 SG_ Joystick6Button11PressedStatus : 58|2@1+ (1,0) [0.0|3.0] "" Vector__XXX
 SG_ Joystick6Button12PressedStatus : 56|2@1+ (1,0) [0.0|3.0] "" Vector__XXX
 SG_ Joystick6Button5PressedStatus : 54|2@1+ (1,0) [0.0|3.0] "" Vector__XXX
 SG_ Joystick6Button6PressedStatus : 52|2@1+ (1,0) [0.0|3.0] "" Vector__XXX
 SG_ Joystick6Button7PressedStatus : 50|2@1+ (1,0) [0.0|3.0] "" Vector__XXX
 SG_ Joystick6Button8PressedStatus : 48|2@1+ (1,0) [0.0|3.0] "" Vector__XXX
 SG_ Joystick6Button1PressedStatus : 46|2@1+ (1,0) [0.0|3.0] "" Vector__XXX
 SG_ Joystick6Button2PressedStatus : 44|2@1+ (1,0) [0.0|3.0] "" Vector__XXX
 SG_ Joystick6Button3PressedStatus : 42|2@1+ (1,0) [0.0|3.0] "" Vector__XXX
 SG_ Joystick6Button4PressedStatus : 40|2@1+ (1,0) [0.0|3.0] "" Vector__XXX
 SG_ Joystick6XAxisDetentPosStatus : 38|2@1+ (1,0) [0.0|3.0] "" Vector__XXX
 SG_ Joystick6YAxisDetentPosStatus : 36|2@1+ (1,0) [0.0|3.0] "" Vector__XXX
 SG_ Joystick6YAxisPos : 22|10@1+ (0.1,0) [0.0|102.0] "%" Vector__XXX
 SG_ Jystck6YAxsLvrFrwrdPstvPosStatus : 20|2@1+ (1,0) [0.0|3.0] "" Vector__XXX
 SG_ Jystck6YAxsLvrBckNgtivePosStatus : 18|2@1+ (1,0) [0.0|3.0] "" Vector__XXX
 SG_ Joystick6YAxisNeutralPosStatus : 16|2@1+ (1,0) [0.0|3.0] "" Vector__XXX
 SG_ Joystick6XAxisPos : 6|10@1+ (0.1,0) [0.0|102.0] "%" Vector__XXX
 SG_ Jystck6XAxsLvrRghtPstvePosStatus : 4|2@1+ (1,0) [0.0|3.0] "" Vector__XXX
 SG_ Jystck6XAxsLvrLftNgtivePosStatus : 2|2@1+ (1,0) [0.0|3.0] "" Vector__XXX
 SG_ Joystick6XAxisNeutralPosStatus : 0|2@1+ (1,0) [0.0|3.0] "" Vector__XXX

BO_ 2365402878 BJM5: 8 Vector__XXX
 SG_ Joystick5Button9PressedStatus : 62|2@1+ (1,0) [0.0|3.0] "" Vector__XXX
 SG_ Joystick5Button10PressedStatus : 60|2@1+ (1,0) [0.0|3.0] "" Vector__XXX
 SG_ Joystick5Button11PressedStatus : 58|2@1+ (1,0) [0.0|3.0] "" Vector__XXX
 SG_ Joystick5Button12PressedStatus : 56|2@1+ (1,0) [0.0|3.0] "" Vector__XXX
 SG_ Joystick5Button5PressedStatus : 54|2@1+ (1,0) [0.0|3.0] "" Vector__XXX
 SG_ Joystick5Button6PressedStatus : 52|2@1+ (1,0) [0.0|3.0] "" Vector__XXX
 SG_ Joystick5Button7PressedStatus : 50|2@1+ (1,0) [0.0|3.0] "" Vector__XXX
 SG_ Joystick5Button8PressedStatus : 48|2@1+ (1,0) [0.0|3.0] "" Vector__XXX
 SG_ Joystick5Button1PressedStatus : 46|2@1+ (1,0) [0.0|3.0] "" Vector__XXX
 SG_ Joystick5Button2PressedStatus : 44|2@1+ (1,0) [0.0|3.0] "" Vector__XXX
 SG_ Joystick5Button3PressedStatus : 42|2@1+ (1,0) [0.0|3.0] "" Vector__XXX
 SG_ Joystick5Button4PressedStatus : 40|2@1+ (1,0) [0.0|3.0] "" Vector__XXX
 SG_ Joystick5XAxisDetentPosStatus : 38|2@1+ (1,0) [0.0|3.0] "" Vector__XXX
 SG_ Joystick5YAxisDetentPosStatus : 36|2@1+ (1,0) [0.0|3.0] "" Vector__XXX
 SG_ Joystick5YAxisPos : 22|10@1+ (0.1,0) [0.0|102.0] "%" Vector__XXX
 SG_ Jystck5YAxsLvrFrwrdPstvPosStatus : 20|2@1+ (1,0) [0.0|3.0] "" Vector__XXX
 SG_ Jystck5YAxsLvrBckNgtivePosStatus : 18|2@1+ (1,0) [0.0|3.0] "" Vector__XXX
 SG_ Joystick5YAxisNeutralPosStatus : 16|2@1+ (1,0) [0.0|3.0] "" Vector__XXX
 SG_ Joystick5XAxisPos : 6|10@1+ (0.1,0) [0.0|102.0] "%" Vector__XXX
 SG_ Jystck5XAxsLvrRghtPstvePosStatus : 4|2@1+ (1,0) [0.0|3.0] "" Vector__XXX
 SG_ Jystck5XAxsLvrLftNgtivePosStatus : 2|2@1+ (1,0) [0.0|3.0] "" Vector__XXX
 SG_ Joystick5XAxisNeutralPosStatus : 0|2@1+ (1,0) [0.0|3.0] "" Vector__XXX

BO_ 2365403390 BJM4: 8 Vector__XXX
 SG_ Joystick4Button9PressedStatus : 62|2@1+ (1,0) [0.0|3.0] "" Vector__XXX
 SG_ Joystick4Button10PressedStatus : 60|2@1+ (1,0) [0.0|3.0] "" Vector__XXX
 SG_ Joystick4Button11PressedStatus : 58|2@1+ (1,0) [0.0|3.0] "" Vector__XXX
 SG_ Joystick4Button12PressedStatus : 56|2@1+ (1,0) [0.0|3.0] "" Vector__XXX
 SG_ Joystick4Button5PressedStatus : 54|2@1+ (1,0) [0.0|3.0] "" Vector__XXX
 SG_ Joystick4Button6PressedStatus : 52|2@1+ (1,0) [0.0|3.0] "" Vector__XXX
 SG_ Joystick4Button7PressedStatus : 50|2@1+ (1,0) [0.0|3.0] "" Vector__XXX
 SG_ Joystick4Button8PressedStatus : 48|2@1+ (1,0) [0.0|3.0] "" Vector__XXX
 SG_ Joystick4Button1PressedStatus : 46|2@1+ (1,0) [0.0|3.0] "" Vector__XXX
 SG_ Joystick4Button2PressedStatus : 44|2@1+ (1,0) [0.0|3.0] "" Vector__XXX
 SG_ Joystick4Button3PressedStatus : 42|2@1+ (1,0) [0.0|3.0] "" Vector__XXX
 SG_ Joystick4Button4PressedStatus : 40|2@1+ (1,0) [0.0|3.0] "" Vector__XXX
 SG_ Joystick4XAxisDetentPosStatus : 38|2@1+ (1,0) [0.0|3.0] "" Vector__XXX
 SG_ Joystick4YAxisDetentPosStatus : 36|2@1+ (1,0) [0.0|3.0] "" Vector__XXX
 SG_ Joystick4YAxisPos : 22|10@1+ (0.1,0) [0.0|102.0] "%" Vector__XXX
 SG_ Jystck4YAxsLvrFrwrdPstvPosStatus : 20|2@1+ (1,0) [0.0|3.0] "" Vector__XXX
 SG_ Jystck4YAxsLvrBckNgtivePosStatus : 18|2@1+ (1,0) [0.0|3.0] "" Vector__XXX
 SG_ Joystick4YAxisNeutralPosStatus : 16|2@1+ (1,0) [0.0|3.0] "" Vector__XXX
 SG_ Joystick4XAxisPos : 6|10@1+ (0.1,0) [0.0|102.0] "%" Vector__XXX
 SG_ Jystck4XAxsLvrRghtPstvePosStatus : 4|2@1+ (1,0) [0.0|3.0] "" Vector__XXX
 SG_ Jystck4XAxsLvrLftNgtivePosStatus : 2|2@1+ (1,0) [0.0|3.0] "" Vector__XXX
 SG_ Joystick4XAxisNeutralPosStatus : 0|2@1+ (1,0) [0.0|3.0] "" Vector__XXX

BO_ 2365400318 BJM10: 8 Vector__XXX
 SG_ Joystick10Button9PressedStatus : 62|2@1+ (1,0) [0.0|3.0] "" Vector__XXX
 SG_ Joystick10Button10PressedStatus : 60|2@1+ (1,0) [0.0|3.0] "" Vector__XXX
 SG_ Joystick10Button11PressedStatus : 58|2@1+ (1,0) [0.0|3.0] "" Vector__XXX
 SG_ Joystick10Button12PressedStatus : 56|2@1+ (1,0) [0.0|3.0] "" Vector__XXX
 SG_ Joystick10Button5PressedStatus : 54|2@1+ (1,0) [0.0|3.0] "" Vector__XXX
 SG_ Joystick10Button6PressedStatus : 52|2@1+ (1,0) [0.0|3.0] "" Vector__XXX
 SG_ Joystick10Button7PressedStatus : 50|2@1+ (1,0) [0.0|3.0] "" Vector__XXX
 SG_ Joystick10Button8PressedStatus : 48|2@1+ (1,0) [0.0|3.0] "" Vector__XXX
 SG_ Joystick10Button1PressedStatus : 46|2@1+ (1,0) [0.0|3.0] "" Vector__XXX
 SG_ Joystick10Button2PressedStatus : 44|2@1+ (1,0) [0.0|3.0] "" Vector__XXX
 SG_ Joystick10Button3PressedStatus : 42|2@1+ (1,0) [0.0|3.0] "" Vector__XXX
 SG_ Joystick10Button4PressedStatus : 40|2@1+ (1,0) [0.0|3.0] "" Vector__XXX
 SG_ Joystick10XAxisDetentPosStatus : 38|2@1+ (1,0) [0.0|3.0] "" Vector__XXX
 SG_ Joystick10YAxisDetentPosStatus : 36|2@1+ (1,0) [0.0|3.0] "" Vector__XXX
 SG_ Joystick10YAxisPos : 22|10@1+ (0.1,0) [0.0|102.0] "%" Vector__XXX
 SG_ Jystck10YAxsLvrFrwrdPstvPsStatus : 20|2@1+ (1,0) [0.0|3.0] "" Vector__XXX
 SG_ Jystck10YAxsLvrBckNgtvePosStatus : 18|2@1+ (1,0) [0.0|3.0] "" Vector__XXX
 SG_ Joystick10YAxisNeutralPosStatus : 16|2@1+ (1,0) [0.0|3.0] "" Vector__XXX
 SG_ Joystick10XAxisPos : 6|10@1+ (0.1,0) [0.0|102.0] "%" Vector__XXX
 SG_ Jystck10XAxsLvrRghtPstvPosStatus : 4|2@1+ (1,0) [0.0|3.0] "" Vector__XXX
 SG_ Jystck10XAxsLvrLftNgtvePosStatus : 2|2@1+ (1,0) [0.0|3.0] "" Vector__XXX
 SG_ Joystick10XAxisNeutralPosStatus : 0|2@1+ (1,0) [0.0|3.0] "" Vector__XXX

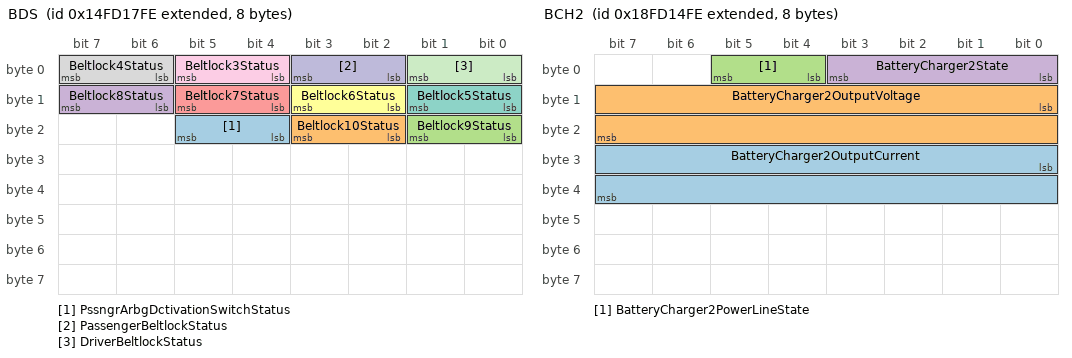
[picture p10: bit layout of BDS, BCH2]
BO_ 2499614718 BDS: 8 Vector__XXX
 SG_ PssngrArbgDctivationSwitchStatus : 20|2@1+ (1,0) [0.0|3.0] "" Vector__XXX
 SG_ Beltlock10Status : 18|2@1+ (1,0) [0.0|3.0] "" Vector__XXX
 SG_ Beltlock9Status : 16|2@1+ (1,0) [0.0|3.0] "" Vector__XXX
 SG_ Beltlock8Status : 14|2@1+ (1,0) [0.0|3.0] "" Vector__XXX
 SG_ Beltlock7Status : 12|2@1+ (1,0) [0.0|3.0] "" Vector__XXX
 SG_ Beltlock6Status : 10|2@1+ (1,0) [0.0|3.0] "" Vector__XXX
 SG_ Beltlock5Status : 8|2@1+ (1,0) [0.0|3.0] "" Vector__XXX
 SG_ Beltlock4Status : 6|2@1+ (1,0) [0.0|3.0] "" Vector__XXX
 SG_ Beltlock3Status : 4|2@1+ (1,0) [0.0|3.0] "" Vector__XXX
 SG_ PassengerBeltlockStatus : 2|2@1+ (1,0) [0.0|3.0] "" Vector__XXX
 SG_ DriverBeltlockStatus : 0|2@1+ (1,0) [0.0|3.0] "" Vector__XXX

BO_ 2566722814 BCH2: 8 Vector__XXX
 SG_ BatteryCharger2OutputCurrent : 24|16@1+ (0.05,-1600) [-1600.0|1612.75] "A" Vector__XXX
 SG_ BatteryCharger2OutputVoltage : 8|16@1+ (0.05,0) [0.0|3212.75] "V" Vector__XXX
 SG_ BatteryCharger2PowerLineState : 4|2@1+ (1,0) [0.0|3.0] "" Vector__XXX
 SG_ BatteryCharger2State : 0|4@1+ (1,0) [0.0|15.0] "" Vector__XXX

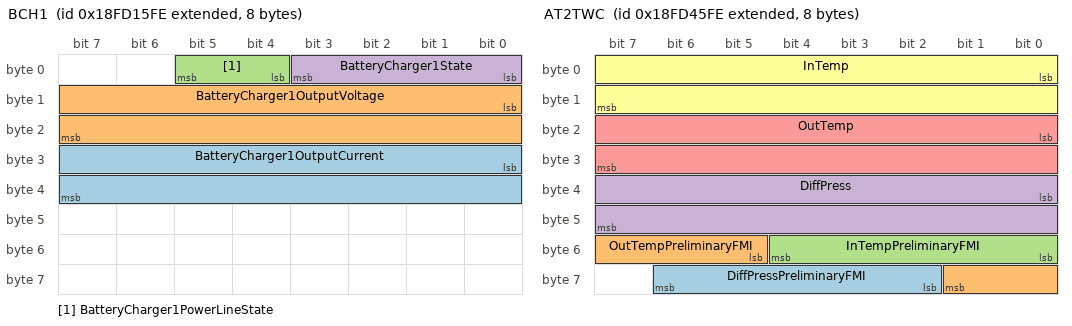
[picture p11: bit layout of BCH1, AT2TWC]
BO_ 2566723070 BCH1: 8 Vector__XXX
 SG_ BatteryCharger1OutputCurrent : 24|16@1+ (0.05,-1600) [-1600.0|1612.75] "A" Vector__XXX
 SG_ BatteryCharger1OutputVoltage : 8|16@1+ (0.05,0) [0.0|3212.75] "V" Vector__XXX
 SG_ BatteryCharger1PowerLineState : 4|2@1+ (1,0) [0.0|3.0] "" Vector__XXX
 SG_ BatteryCharger1State : 0|4@1+ (1,0) [0.0|15.0] "" Vector__XXX

BO_ 2566725118 ATDT2: 8 Vector__XXX
 SG_ TwoTWCDiffTemp : 16|16@1+ (0.03125,-273) [-273.0|1734.96875] "°C" Vector__XXX
 SG_ OneTWCDiffTemp : 0|16@1+ (0.03125,-273) [-273.0|1734.96875] "°C" Vector__XXX

BO_ 2566725374 ATDT1: 8 Vector__XXX
 SG_ TwoGOCDiffTemp : 16|16@1+ (0.03125,-273) [-273.0|1734.96875] "°C" Vector__XXX
 SG_ OneGOCDiffTemp : 0|16@1+ (0.03125,-273) [-273.0|1734.96875] "°C" Vector__XXX

BO_ 2566712830 AT2WUDOC: 8 Vector__XXX
 SG_ OutTemp : 16|16@1+ (0.03125,-273) [-273.0|1734.96875] "°C" Vector__XXX
 SG_ InTemp : 0|16@1+ (0.03125,-273) [-273.0|1734.96875] "°C" Vector__XXX

BO_ 2566735358 AT2TWC: 8 Vector__XXX
 SG_ DiffPressPreliminaryFMI : 58|5@1+ (1,0) [0.0|31.0] "" Vector__XXX
 SG_ OutTempPreliminaryFMI : 53|5@1+ (1,0) [0.0|31.0] "" Vector__XXX
 SG_ InTempPreliminaryFMI : 48|5@1+ (1,0) [0.0|31.0] "" Vector__XXX
 SG_ DiffPress : 32|16@1+ (0.1,0) [0.0|6425.5] "kPa" Vector__XXX
 SG_ OutTemp : 16|16@1+ (0.03125,-273) [-273.0|1734.96875] "°C" Vector__XXX
 SG_ InTemp : 0|16@1+ (0.03125,-273) [-273.0|1734.96875] "°C" Vector__XXX

CM_ BO_ 2498777854  "Engine Cylinder 5 Combustion Average Information
Used to transmit the average of combustion parameters of Engine Cylinder 5.
This PGN is transmitted at a defined ratio of the engine speed. The transmission rate is dependent on
SPN 6394 - Number ...";
CM_ BO_ 2498777598  "Engine Cylinder 4 Combustion Average Information
Used to transmit the average of combustion parameters of Engine Cylinder 4.
This PGN is transmitted at a defined ratio of the engine speed. The transmission rate is dependent on
SPN 6394 - Number ...";
CM_ BO_ 2498777342  "Engine Cylinder 3 Combustion Average Information
Used to transmit the average of combustion parameters of Engine Cylinder 3.
This PGN is transmitted at a defined ratio of the engine speed. The transmission rate is dependent on
SPN 6394 - Number ...";
CM_ BO_ 2566768382  "Cold Start Aids
Cold start aid information and settings.";
CM_ BO_ 2566811902  "Combination Vehicle Weight";
CM_ BO_ 2563768062  "Continuous Torque & Speed Limit Request";
CM_ BO_ 2633924862  "Combustion Time 6";
CM_ BO_ 2633924606  "Combustion Time 5";
CM_ BO_ 2633924350  "Combustion Time 4";
CM_ BO_ 2633924094  "Combustion Time 3";
CM_ BO_ 2633923838  "Combustion Time 2";
CM_ BO_ 2633923582  "Combustion Time 1";
CM_ BO_ 2633878014  "Electronic Control Module Information
Information relating to electronic control modules";
CM_ BO_ 2566771966  "Cab Message 3
Provides information from Cab mounted operator inputs.";
CM_ BO_ 2564882174  "Cab Message 1 - Message containing parameters originating from the vehicle cab.";
CM_ BO_ 2563833598  "Cab Illumination Message - This message contains information that controls illumination devices inside the vehicle's cab.";
CM_ BO_ 2566843390  "Component Identification
NOTE - The make, model, serial number and unit number fields in this message are optional and separated by an ASCII “*”.  It is not necessary to include all fields; however, the delimiter (“*”) is always required.
Field:
...";
CM_ BO_ 2566844926  "Cruise Control/Vehicle Speed 1
Cruise Control/Vehicle Speed 1";
CM_ BO_ 2566843902  "Cruise Control/Vehicle Speed Setup";
CM_ BO_ 2566809598  "Climate Control Configuration";
CM_ BO_ 2633940222  "Compression/Service Brake Information";
CM_ BO_ 2566775294  "Cab A/C Climate System Information
This message contains measurement and condition information from cab air conditioning components.";
CM_ BO_ 2566803710  "Battery Temperature
Contains battery temperature information.";
CM_ BO_ 2566719486  "Direct Lamp Control Command 1
Message that directly controls the driver indicator lamps.  See also PGN 64774 for additional lamps and PGN 64773 for the feedback information about these lamps.
Note: Since this message is direct lamp control, it is ...";
CM_ BO_ 2633832702  "Collision Sensor Information
Message containing type and serial number for every sensor of the restraint-system. The Collision Sensor Type is required for all possible sensors, but only the serial numbers of sensors with a type that is different ...";
CM_ BO_ 2163223550  "Crash Notification
This message is transmitted in case of a crash event.
The message contains information about the Crash Type, a Crash Counter and a Checksum. The function of the Crash Counter is to prevent other ECU's from reacting to a faulty ...";
CM_ BO_ 2566714878  "Charge Air Cooler 2 Precooler
Engine bank 2 CAC precooler parameters";
CM_ BO_ 2566714622  "Charge Air Cooler 2
Engine bank 2 Charge Air Cooler parameters";
CM_ BO_ 2566715390  "Charge Air Cooler 1 Precooler
Engine bank 1 CAC precooler parameters";
CM_ BO_ 2566715134  "Charge Air Cooler 1
Engine bank 1 Charge Air Cooler parameters";
CM_ BO_ 2365400830  "Basic Joystick Message 9
Used to transfer information about the measured status of the 1st 2 axes and up to 12 buttons of a joystick.  Additional handle information is available in the Expanded Joystick Message.
10-bit position parameters are ...";
CM_ BO_ 2365401342  "Basic Joystick Message 8
Used to transfer information about the measured status of the 1st 2 axes and up to 12 buttons of a joystick.  Additional handle information is available in the Expanded Joystick Message.
10-bit position parameters are ...";
CM_ BO_ 2365401854  "Basic Joystick Message 7
Used to transfer information about the measured status of the 1st 2 axes and up to 12 buttons of a joystick.  Additional handle information is available in the Expanded Joystick Message.
10-bit position parameters are ...";
CM_ BO_ 2365402366  "Basic Joystick Message 6
Used to transfer information about the measured status of the 1st 2 axes and up to 12 buttons of a joystick.  Additional handle information is available in the Expanded Joystick Message.
10-bit position parameters are ...";
CM_ BO_ 2365402878  "Basic Joystick Message 5
Used to transfer information about the measured status of the 1st 2 axes and up to 12 buttons of a joystick.  Additional handle information is available in the Expanded Joystick Message.
10-bit position parameters are ...";
CM_ BO_ 2365403390  "Basic Joystick Message 4
Used to transfer information about the measured status of the 1st 2 axes and up to 12 buttons of a joystick.  Additional handle information is available in the Expanded Joystick Message.
10-bit position parameters are ...";
CM_ BO_ 2365400318  "Basic Joystick Message 10
Used to transfer information about the measured status of the 1st 2 axes and up to 12 buttons of a joystick.  Additional handle information is available in the Expanded Joystick Message.
10-bit position parameters are ...";
CM_ BO_ 2499614718  "Beltlock and Airbag Deactivation Switch Information
Message containing Beltlock States and the Passener Airbag Deactivation Switch State.";
CM_ BO_ 2566722814  "Battery Charger 2
Parameters for the battery charger connected to the auxiliary battery.";
CM_ BO_ 2566723070  "Battery Charger 1
Parameters for the battery charger connected to the main battery.";
CM_ BO_ 2566725118  "Aftertreatment Differential Temperature 2
The purpose of this PGN is to group the aftertreatment differential temperature data. These values include the differential temperature measure between the intake and outlet of aftertreatment components.";
CM_ BO_ 2566725374  "Aftertreatment Differential Temperature 1
The purpose of this PGN is to group the aftertreatment differential temperature data. These values include the differential temperature measure between the intake and outlet of aftertreatment components.";
CM_ BO_ 2566712830  "Aftertreatment 2 Warm Up Diesel Oxidation Catalyst Information
This PGN contains information for the warm up oxidation catalytic converter in exhaust bank 2.";
CM_ BO_ 2566735358  "Aftertreatment 2 Three Way Catalyst
The purpose of this PGN is to group the aftertreatment Three Way Catalyst data for bank 2. These values include the intake temperature, outlet temperature and differential pressure as well as the associated ...";
CM_ SG_ 2498777854 EngCyl5AverageCombustionDuration "Average duration of combustion calculated over defined number of combustion cycles for engine cylinder 5 with reference to the crank angle.  Combustion duration is the difference between end of combustion and start of combustion expressed, in this ...";
CM_ SG_ 2498777854 EngCyl5AvrgCntrOfCmbustionTiming "Average timing calculated over defined number of combustion cycles for the center of combustion in engine cylinder 5 with reference to the crank angle.  Center of Combustion is used to indicate the combustion efficiency.  When the combustion happens ...";
CM_ SG_ 2498777854 EngCyl5AvrgStrtOfCmbustionTiming "Average start of combustion timing calculated over defined number of combustion cycles for engine cylinder 5 with reference to the crank angle.  When the combustion happens after the TDC (Top Dead Center) of this cylinder, the timing is referred in ...";
CM_ SG_ 2498777854 EngCyl5IndctedMeanEffectivePress "Average cylinder pressure calculated over defined number of combustion cycles for engine cylinder 5.  Negative range is to cover thermodynamic behavior during misfire.";
CM_ SG_ 2498777598 EngCyl4AverageCombustionDuration "Average duration of combustion calculated over defined number of combustion cycles for engine cylinder 4 with reference to the crank angle.  Combustion duration is the difference between end of combustion and start of combustion expressed, in this ...";
CM_ SG_ 2498777598 EngCyl4AvrgCntrOfCmbustionTiming "Average timing calculated over defined number of combustion cycles for the center of combustion in engine cylinder 4 with reference to the crank angle.  Center of Combustion is used to indicate the combustion efficiency.  When the combustion happens ...";
CM_ SG_ 2498777598 EngCyl4AvrgStrtOfCmbustionTiming "Average start of combustion timing calculated over defined number of combustion cycles for engine cylinder 4 with reference to the crank angle.  When the combustion happens after the TDC (Top Dead Center) of this cylinder, the timing is referred in ...";
CM_ SG_ 2498777598 EngCyl4IndctedMeanEffectivePress "Average cylinder pressure calculated over defined number of combustion cycles for engine cylinder 4.  Negative range is to cover thermodynamic behavior during misfire.";
CM_ SG_ 2498777342 EngCyl3AverageCombustionDuration "Average duration of combustion calculated over defined number of combustion cycles for engine cylinder 3 with reference to the crank angle.  Combustion duration is the difference between end of combustion and start of combustion expressed, in this ...";
CM_ SG_ 2498777342 EngCyl3AvrgCntrOfCmbustionTiming "Average timing calculated over defined number of combustion cycles for the center of combustion in engine cylinder 3 with reference to the crank angle.  Center of Combustion is used to indicate the combustion efficiency.  When the combustion happens ...";
CM_ SG_ 2498777342 EngCyl3AvrgStrtOfCmbustionTiming "Average start of combustion timing calculated over defined number of combustion cycles for engine cylinder 3 with reference to the crank angle.  When the combustion happens after the TDC (Top Dead Center) of this cylinder, the timing is referred in ...";
CM_ SG_ 2498777342 EngCyl3IndctedMeanEffectivePress "Average cylinder pressure calculated over defined number of combustion cycles for engine cylinder 3.  Negative range is to cover thermodynamic behavior during misfire.";
CM_ SG_ 2566768382 EngCldStrtFlIgniterRelayFeedback "Feedback state of the engine cold start fuel igniter relay which indicates the status of the relay output.
00  Off
01  On
10  Error
11  Not available";
CM_ SG_ 2566768382 EngColdStartFuelIgniterRelay "The engine cold start fuel igniter relay control command.  This command controls the relay, not the igniter.
00  Off
01  On
10  Reserved
11  Don't care/take no action";
CM_ SG_ 2566768382 EngColdStartFuelIgniterCmd "The engine cold start fuel igniter control command, normalized to %, where 0% represents fully off and 100% represents fully on.";
CM_ SG_ 2566768382 EngStartEnableDevice2Config "The start enable device installed for start enable device 2.
0000 - no start enable device 2 installed
0001 - glow plugs installed
0010 - fuelled start installed
0011 - ether injection installed
0100 - electric intake air heater installed
0101 ...";
CM_ SG_ 2566768382 EngStartEnableDevice1Config "The start enable device installed for start enable device 1.
0000 - no start enable device 1 installed
0001 - glow plugs installed
0010 - fuelled start installed
0011 - ether injection installed
0100 - electric intake air heater installed
0101 ...";
CM_ SG_ 2566768382 EngStartEnableDevice2 "Devices that assist an engine in starting, e.g. intake heaters, ether, or an alternate/secondary starting aid.  May be of the same type or different than Start Enable Device 1 (SPN 626). Parameter indicating whether the start enable device 2 is ON ...";
CM_ SG_ 2566768382 EngStartEnableDevice1 "Devices that assist an Engine in starting, e.g. intake heaters and ether.  Primary starting aid.
Parameter indicating whether the start enable device 1 is ON or OFF
00 - start enable OFF
01 - start enable ON
10 - reserved
11 - not available";
CM_ SG_ 2566811902 PoweredVehicleWeight "Total mass imposed by the tires of the powered vehicle on the road surface.  Does not include the trailer.";
CM_ SG_ 2566811902 GrossCombinationVehicleWeight "The total weight of the truck and all attached trailers.";
CM_ SG_ 2563768062 MaxContnsRtdrTqLimitReq_1791 "Requested maximum continuous retarder torque (operating range: -125 to 0%)";
CM_ SG_ 2563768062 MinContnsRtdrTqLimitReq_1790 "Requested minimum continuous retarder torque (operating range: -125 to 0%)";
CM_ SG_ 2563768062 MaxContnsRtdrSpdLimReq_1789 "Requested maximum continuous retarder speed";
CM_ SG_ 2563768062 MinContnsRtdrSpdLimReq_1788 "Requested minimum continuous retarder speed";
CM_ SG_ 2563768062 EngTorqueLimitRqMaxContns_1787 "Requested maximum continuous engine torque (operating range: 0 to 125%)";
CM_ SG_ 2563768062 EngTorqueLimitRqMinContns_1786 "Requested minimum continuous engine torque (operating range: 0 to 125%)";
CM_ SG_ 2563768062 EngSpeedLimitRqMaxContns_1785 "Requested maximum continuous engine speed";
CM_ SG_ 2563768062 EngSpeedLimitRqMinContns_1784 "Requested minimum continuous engine speed";
CM_ SG_ 2633924862 EngAverageCombustionTime "The average combustion time of all cylinders of an engine.";
CM_ SG_ 2633924862 EngDesiredCombustionTime "The desired combustion time based upon engine load and speed lookup maps.";
CM_ SG_ 2633924606 EngCyl20CombustionTime "The amount of time from when the ignition of the fuel is initiated to when the fuel is completely ignited (i.e., the flame front has propagated across the cylinder).";
CM_ SG_ 2633924606 EngCyl19CombustionTime "The amount of time from when the ignition of the fuel is initiated to when the fuel is completely ignited (i.e., the flame front has propagated across the cylinder).";
CM_ SG_ 2633924606 EngCyl18CombustionTime "The amount of time from when the ignition of the fuel is initiated to when the fuel is completely ignited (i.e., the flame front has propagated across the cylinder).";
CM_ SG_ 2633924606 EngCyl17CombustionTime "The amount of time from when the ignition of the fuel is initiated to when the fuel is completely ignited (i.e., the flame front has propagated across the cylinder).";
CM_ SG_ 2633924350 EngCyl16CombustionTime "The amount of time from when the ignition of the fuel is initiated to when the fuel is completely ignited (i.e., the flame front has propagated across the cylinder).";
CM_ SG_ 2633924350 EngCyl15CombustionTime "The amount of time from when the ignition of the fuel is initiated to when the fuel is completely ignited (i.e., the flame front has propagated across the cylinder).";
CM_ SG_ 2633924350 EngCyl14CombustionTime "The amount of time from when the ignition of the fuel is initiated to when the fuel is completely ignited (i.e., the flame front has propagated across the cylinder).";
CM_ SG_ 2633924350 EngCyl13CombustionTime "The amount of time from when the ignition of the fuel is initiated to when the fuel is completely ignited (i.e., the flame front has propagated across the cylinder).";
CM_ SG_ 2633924094 EngCyl12CombustionTime "The amount of time from when the ignition of the fuel is initiated to when the fuel is completely ignited (i.e., the flame front has propagated across the cylinder).";
CM_ SG_ 2633924094 EngCyl11CombustionTime "The amount of time from when the ignition of the fuel is initiated to when the fuel is completely ignited (i.e., the flame front has propagated across the cylinder).";
CM_ SG_ 2633924094 EngCyl10CombustionTime "The amount of time from when the ignition of the fuel is initiated to when the fuel is completely ignited (i.e., the flame front has propagated across the cylinder).";
CM_ SG_ 2633924094 EngCyl9CombustionTime "The amount of time from when the ignition of the fuel is initiated to when the fuel is completely ignited (i.e., the flame front has propagated across the cylinder).";
CM_ SG_ 2633923838 EngCyl8CombustionTime "The amount of time from when the ignition of the fuel is initiated to when the fuel is completely ignited (i.e., the flame front has propagated across the cylinder).";
CM_ SG_ 2633923838 EngCyl7CombustionTime "The amount of time from when the ignition of the fuel is initiated to when the fuel is completely ignited (i.e., the flame front has propagated across the cylinder).";
CM_ SG_ 2633923838 EngCyl6CombustionTime "The amount of time from when the ignition of the fuel is initiated to when the fuel is completely ignited (i.e., the flame front has propagated across the cylinder).";
CM_ SG_ 2633923838 EngCyl5CombustionTime "The amount of time from when the ignition of the fuel is initiated to when the fuel is completely ignited (i.e., the flame front has propagated across the cylinder).";
CM_ SG_ 2633923582 EngCyl4CombustionTime "The amount of time from when the ignition of the fuel is initiated to when the fuel is completely ignited (i.e., the flame front has propagated across the cylinder).";
CM_ SG_ 2633923582 EngCyl3CombustionTime "The amount of time from when the ignition of the fuel is initiated to when the fuel is completely ignited (i.e., the flame front has propagated across the cylinder).";
CM_ SG_ 2633923582 EngCyl2CombustionTime "The amount of time from when the ignition of the fuel is initiated to when the fuel is completely ignited (i.e., the flame front has propagated across the cylinder).";
CM_ SG_ 2633923582 EngCyl1CombustionTime "The amount of time from when the ignition of the fuel is initiated to when the fuel is completely ignited (i.e., the flame front has propagated across the cylinder).";
CM_ SG_ 2633878014 TotalCountOfConfigChangesMade "Total number of times changes have been made to any of the configurable parameters.";
CM_ SG_ 2566771966 VehTrailerStatus "Indicates a trailer is connected to the towing mechanism.  This is not intended to indicate that the trailer is latched.
00 - Trailer is not detected
01 - Trailer is detected
10 - Error
11 - Not available";
CM_ SG_ 2566771966 TransOilLevelRq "Conveys operator or vehicle system desire for a transmission oil level reading to be taken.
00 - No transmission oil level reading desired
01 - Transmission oil level reading desired
10 - Reserved
11 - Don't care / take no action";
CM_ SG_ 2566771966 FifthWheelReleaseCtrl "Operator input used to release the fifth wheel. Fifth Wheel Release Control Security Lockout and other conditions must be properly enabled before this will function.
00   Coupler Locked
01   Coupler Unlocked, trailer can be unhitched or hitched
...";
CM_ SG_ 2566771966 FfthWhlRleaseCtrlSecurityLockout "Operator's fifth wheel release control interlock. This operator input must be enabled prior to activating the fifth wheel release control (SPN 3314).
00    Fifth wheel release Disabled
01    Fifth wheel release Enabled
10    Error
11    Not ...";
CM_ SG_ 2566771966 TransferCaseSelectorSwitch "Operator switch to select the condition of the transfer case.  States 000 and 001 should be used if the transfer case only functions to switch between 2-wheel and 4-wheel drive.  If the transfer case includes a High / Low Range function, states 011 ...";
CM_ SG_ 2564882174 SeldMaxVehSpdLimit_2596 "User selected maximum vehicle speed.  If one is selected, then this SPN must equal one of the maximum vehicle speeds #1-#7 from PGN 64997 - Maximum Vehicle Speed Limit Status . If different maximum vehicle speed requests are present from different ...";
CM_ SG_ 2564882174 ReqCabZoneHeating_1686 "Request to activate cab zone heating.
00 Do not heat cab engine zone
01 Heat cab zone
10 Reserved
11 Don't care/take no action";
CM_ SG_ 2564882174 ReqEngZoneHeating_1685 "Request to activate engine zone heating.
00 Do not heat engine zone
01 Heat engine zone
10 Reserved
11 Don't care/take no action";
CM_ SG_ 2564882174 AuxHeaterModeReq_1683 "Request to activate the auxiliary heater.
0000 De-activate auxiliary heater
0001 Off due to ADR per European Regulations for Transport of hazardous materials
0010 Economy mode
0011 Normal mode
0100 Heater pump up-keep
0101-1000 Reserved
...";
CM_ SG_ 2564882174 EngAutomaticStartEnableSw_1656 "Switch signal which enables the idle management system to be enabled. When this system is enabled with the engine in an idle mode and safe operating conditions existing, then the engine may be started or stopped automatically.
00 - Switch in the ...";
CM_ SG_ 2564882174 AtuomaticGearShiftingEnSw_1666 "Indicates that automated gear shifting is enabled via a switch
00 = Automated Gear Shifting is disabled
01 = Automated Gear Shifting is enabled
10 = Error
11 = Not available";
CM_ SG_ 2564882174 AFTRegenForceSw_3696 "Indicates the state of a switch available to the operator that forces aftertreatment regeneration.
00 not active
01 active
10 error
11 not available
This SPN would be “not active” when aftertreatment regeneration is allowed to occur normally ...";
CM_ SG_ 2564882174 AFTRegenInhSw_3695 "Indicates the state of a switch available to the operator that inhibits aftertreatment regeneration.
00 not active
01 active
10 error
11 not available
This SPN would be “not active” when aftertreatment regeneration is allowed to occur normally ...";
CM_ SG_ 2564882174 VehLmtngSpdGovrEnSw_1653 "Switch signal which enables the Vehicle Limiting Speed Governor (VLSG) such that the vehicle speed may be either increased or decreased when the engine is off idle.
00 - Switch disabled
01 - Switched enabled
10 - Error
11 - Not available";
CM_ SG_ 2564882174 VehLmtngSpdGvrnrIncrementSw_1654 "Switch signal which increases the Vehicle Limiting Speed Governor (VLSG).
00 - Switch in the off state
01 - Switch in the on state - increase
10 - Error
11 - Not available";
CM_ SG_ 2564882174 VehLmtngSpdGvrnrDecrementSw_1655 "Switch signal which decreases the Vehicle Limiting Speed Governor (VLSG).
00 - Switch in the off state
01 - Switch in the on state - decrease
10 - Error
11 - Not available";
CM_ SG_ 2564882174 ParkBrakeCmd_5630 "Request by a secondary device to command the Park Brake.  The Park Brake controller should treat this as a request and should apply the Park Brake as determined by the controller.
Feedback of the park brake actuation may utilize SPN 70, SPN 619 or ...";
CM_ SG_ 2564882174 SeatBeltSwitch_1856 "State of switch used to determine if Seat Belt is buckled
00 NOT Buckled
01 OK - Seat Belt is buckled
10 Error - Switch state cannot be determined
11 Not Available";
CM_ SG_ 2564882174 OperatorSeatDirSw_1714 "Senses whether the operator seat is in the forward driving position
00 Operator seat not facing forward
01 Operator seat is facing forward
10 Error
11 Not Available";
CM_ SG_ 2564882174 BatteryMainSwitchHoldRq_1682 "Request to hold the battery main switch.
00 Release Battery Main Switch
01 Hold Battery Main Switch
10 undefined
11 Don't care/take no action";
CM_ SG_ 2564882174 AuxHeaterCoolantPumpRq_1684 "Indicates whether to activate the auxiliary heater coolant water pump.
00 Deactivate water pump
01 Activate water pump
10 Reserved
11 Don't care/take no action";
CM_ SG_ 2564882174 CabInteriorTempCmd_1691 "Parameter used to command a certain cab interior temperature.
Note: See also SPN 170.  SPN 1662 is an additional diagnostic SPN associated with cab temperature.";
CM_ SG_ 2564882174 RequestedPercentFanSpeed_986 "Fan speed of the first or only fan in the system as a ratio of the actual fan drive (current speed) to the fully engaged fan drive (maximum fan speed). A two state fan (off/on) will use 0% and 100% respectively. A three state fan ...";
CM_ SG_ 2563833598 SwtchBcklghtIllmntnBriPrcnt_5532 "Commanded switch backlight brightness level for all operator control switches.  This is separate from the cab display illumination Brightness Percent parameter.
Note:  If a single device is used to control both the backlight brightness level of the ...";
CM_ SG_ 2563833598 IlluminationBriPercent_1487 "Commanded backlight brightness level for all cab displays.
Note:  If a separate device is used to independently control the switch backlight brightness level, see SPN 5532.";
CM_ SG_ 2563833598 SwtchIndctnIllmntnBriPrcent_6820 "Commanded switch indication illumination brightness level for all operator control switches. This is separate from the cab display illumination Brightness Percent parameter.
Note: If a single device is used to control both the indication brightness ...";
CM_ SG_ 2566843390 UnitNumber "Owner assigned unit number for the power unit of the vehicle.
NOTE: The ASCII character \"*\" is reserved as a delimiter.";
CM_ SG_ 2566843390 SerialNumber "Serial number of the component.
NOTE - The ASCII character \"*\" is reserved as a delimiter.";
CM_ SG_ 2566843390 Model "Model of the component.
NOTE - The ASCII character \"*\" is reserved as a delimiter.";
CM_ SG_ 2566843390 Make "Make of the component corresponding to the codes defined in the American Trucking Association Vehicle Maintenance Reporting Standard (ATA/VMRS).
Note:  This parameter is to be transmitted as a 5 character ASCII string;  as a zero length string, if ...";
CM_ SG_ 2566844926 EngShutdownOverrideSwitch "Switch signal which indicates the position of the engine shutdown override switch.  This switch function allows the operator to override an impending engine shutdown.
00 - Off
01 - On
10 - Error
11 - Not available";
CM_ SG_ 2566844926 EngTestModeSwitch "Switch signal which indicates the position of the engine diagnostic test mode switch.
00 - Off
01 - On
10 - Error
11 - Not available";
CM_ SG_ 2566844926 EngIdleDecrementSwitch "Switch signal which indicates the position of the idle decrement switch.
00 - Off
01 - On
10 - Error
11 - Not available";
CM_ SG_ 2566844926 EngIdleIncrementSwitch "Switch signal which indicates the position of the idle increment switch.
00 - Off
01 - On
10 - Error
11 - Not available";
CM_ SG_ 2566844926 CruiseCtrlStates "This parameter is used to indicate the current state, or mode, of operation by the cruise control device.  This is a status parameter.
000 - Off/Disabled
001 - Hold
010 - Accelerate
011 - Decelerate
100 - Resume
101 - Set
110 - Accelerator ...";
CM_ SG_ 2566844926 PTOGovernorState "This parameter is used to indicate the current state or mode of operation by the power takeoff (PTO) governor.  In lieu of support for PTO Drive Engagement parameters, this parameter may represent the status of a PTO drive.  The broadcasting device ...";
CM_ SG_ 2566844926 CruiseCtrlSetSpeed "Value of set (chosen) velocity of velocity control system.  See SPN 6809 for an alternate resolution.
If an algorithm that can modify the cruise control set point exists in the system, such as Predictive Cruise Control or Adaptive Cruise Control, ...";
CM_ SG_ 2566844926 CruiseCtrlAccelerateSwitch "Switch signal of the cruise control activator which indicates that the activator is in the position “accelerate.”
00 - Cruise control activator not in the position “accelerate”
01 - Cruise control activator in position “accelerate”
10 - Error
11 ...";
CM_ SG_ 2566844926 CruiseCtrlResumeSwitch "Switch signal of the cruise control activator which indicates that the activator is in the position “resume.”
00 - Cruise control activator not in the position “resume”
01 - Cruise control activator in position “resume”
10 - Error
11 - Not ...";
CM_ SG_ 2566844926 CruiseCtrlCoastSwitch "Switch signal of the cruise control activator which indicates that the activator is in the position “coast (decelerate).”
00 - Cruise control activator not in the position “coast”
01 - Cruise control activator in position “coast”
10 - Error
11 - ...";
CM_ SG_ 2566844926 CruiseCtrlSetSwitch "Switch signal of the cruise control activator which indicates that the activator is in the position “set.”
00 - Cruise control activator not in the position “set”
01 - Cruise control activator in position “set”
10 - Error
11 - Not available";
CM_ SG_ 2566844926 ClutchSwitch "Switch signal which indicates that the clutch pedal is being pressed. It is necessary for a safe drivetrain behavior that the clutch switch is set before the clutch is opened (cruise control function).
00 - Clutch pedal released
01 - Clutch pedal ...";
CM_ SG_ 2566844926 BrakeSwitch "Switch signal which indicates that the driver operated brake foot pedal is being pressed.  This brake foot pedal is controlling the vehicles’ service brake (total vehicle braking application, not park brakes).  It is necessary for safe drivetrain ...";
CM_ SG_ 2566844926 CruiseCtrlEnableSwitch "Switch signal which indicates that it is possible to manage the cruise control function.
00 - Cruise control disabled
01 - Cruise control enabled
10 - Error
11 - Not available";
CM_ SG_ 2566844926 CruiseCtrlActive "Cruise control is switched on.  It is not ensured that the engine is controlled by cruise control, as in the case of a large driver's demand the engine is controlled by the driver while cruise control is active (maximum selection of cruise control ...";
CM_ SG_ 2566844926 WheelBasedVehicleSpeed "Speed of the vehicle as calculated from wheel or tailshaft speed.";
CM_ SG_ 2566844926 ParkBrakeReleaseInhibitRq "Park Brake Release Inhibit Request signals the desire that an applied park brake remain applied and limit the ability of the vehicle to be moved.
00 - Park Brake Release Inhibit not requested
01 - Park Brake Release Inhibit requested
10 - SAE ...";
CM_ SG_ 2566844926 CruiseCtrlPauseSwitch "Switch signal which indicates the position of the Cruise Control Pause Switch used on Remote Cruise Control applications. The Cruise Control Pause Switch signal temporarily disables the Cruise Control function.
00 - Off
01 - On
10 - Error ...";
CM_ SG_ 2566844926 ParkingBrakeSwitch "Switch signal which indicates when the parking brake is set. In general the switch actuated by the operator's park brake control, whether a pedal, lever or other control mechanism  (see also SPN 619 and 5275).
00 - Parking brake not set
01 - ...";
CM_ SG_ 2566844926 TwoSpeedAxleSwitch "Switch signal which indicates the current axle range.
00 - Low speed range
01 - High speed range
10 - Error
11 - Not available";
CM_ SG_ 2566843902 MaxVehicleSpeedLimit6808 "Maximum vehicle velocity allowed. See SPN 74 for an alternate resolution.";
CM_ SG_ 2566843902 CruiseCtrlLowSetLimitSpeed "Minimum vehicle velocity at which cruise can be set or minimum vehicle velocity for cruise operation before it will exit cruise control operation.";
CM_ SG_ 2566843902 CruiseCtrlHighSetLimitSpeed "Maximum vehicle velocity at which cruise can be set.
If Cruise Control Adjusted Maximum Speed (SPN 7495) is supported, then SPN 7495 has priority over SPN 87. See the definition for SPN 7495 for more details.";
CM_ SG_ 2566843902 MaxVehicleSpeedLimit "Maximum vehicle velocity allowed.   See SPN 6808 for an alternate resolution.";
CM_ SG_ 2566809598 AuxHeaterMaxOutputPower "The maximum output power of the auxiliary heater.";
CM_ SG_ 2633940222 TripServiceBrakeApplications "Total number of times the service brakes have been activated since the last trip reset.  Brake applications of less than 0.5 s are not counted and lengthy brake applications (longer than 0.5 s) are counted as a single event.
NOTE - Definition and ...";
CM_ SG_ 2633940222 TripServiceBrakeDistance "Total distance over which the service brakes have been active since the last trip reset.";
CM_ SG_ 2633940222 TripCompressionBrakeDistance "Total distance over which the compression brakes have been active since the last trip reset.";
CM_ SG_ 2633940222 TotalCompressionBrakeDistance "Total distance over which the compression brakes have been active for the life of the engine.";
CM_ SG_ 2566775294 CbA_CRfrgrntCmpressorOutletPress "This is the gage pressure at the compressor outlet in the cab air conditioning system.";
CM_ SG_ 2566803710 SLIBattery4Temp "Temperature of the battery 4 used for starting the engine, for lighting, and for ignition (SLI).
The relation to physical location is determined by the equipment manufacturer.";
CM_ SG_ 2566803710 SLIBattery3Temp "Temperature of the battery 3 used for starting the engine, for lighting, and for ignition (SLI).
The relation to physical location is determined by the equipment manufacturer.";
CM_ SG_ 2566803710 Battery2Temp "Temperature of the battery 2 used for starting the engine, for lighting, and for ignition (SLI).
The relation to physical location is determined by the equipment manufacturer.";
CM_ SG_ 2566803710 Battery1Temp "Temperature of the battery 1 used for starting the engine, for lighting, and for ignition (SLI).
The relation to physical location is determined by the equipment manufacturer.";
CM_ SG_ 2566719486 VhclAccelerationRateLimitLampCmd "Command signal directly controlling the Vehicle Acceleration Rate Limit Lamp.
00 - Lamp Off
01 - Lamp On
10 - Reserved
11 - Not available
NOTE: SPN 2979 is the original parameter used to provide vehicle acceleration rate limit status.  This ...";
CM_ SG_ 2566719486 EngSpeedVeryHighLampCmd "Command signal directly controlling the Engine Speed Very High Warning lamp.
00 - Lamp Off
01 - Lamp On
10 - Reserved
11 - Not available";
CM_ SG_ 2566719486 EngSpeedHighLampCmd "Command signal directly controlling the Engine Speed High Warning lamp.
00 - Lamp Off
01 - Lamp On
10 - Reserved
11 - Not available";
CM_ SG_ 2566719486 EngCtrlModule3ReadyForUseLampCmd "Command signal directly controlling the Engine Control Module 3 Ready for Use Lamp. This lamp is used to indicate whether ECM 3 can control the operation of the engine. In case of a failure in ECM 3, lamp will be turned OFF.
00 - Lamp Off
01 - ...";
CM_ SG_ 2566719486 EngCtrlModule2ReadyForUseLampCmd "Command signal directly controlling the Engine Control Module 2 Ready for Use Lamp. This lamp is used to indicate whether ECM 2 can control the operation of the engine. In case of a failure in ECM 2, lamp will be turned OFF.
00 - Lamp Off
01 - ...";
CM_ SG_ 2566719486 EngCtrlModule1ReadyForUseLampCmd "Command signal directly controlling the Engine Control Module 1 Ready for use Lamp. This lamp is used to indicate whether ECM 1 can control the operation of the engine. In case of a failure in ECM 1, lamp will be turned OFF.
00 - Lamp Off
01 - ...";
CM_ SG_ 2566719486 EngFuelFilterRestrictedLampCmd "Command signal directly controlling the Engine Fuel Filter Restricted Lamp.
00 - Lamp Off
01 - Lamp On
10 - Reserved
11 - Not available";
CM_ SG_ 2566719486 EngAirFilterRestrictionLampCmd "Command signal directly controlling the Engine Air Filter Restriction Lamp.
00 - Lamp Off
01 - Lamp On
10 - Reserved
11 - Not available";
CM_ SG_ 2566719486 EngIdleManagementActiveLampCmd "Command signal directly controlling the Engine Idle Management Active Lamp
00 - Lamp Off
01 - Lamp On
10 - Reserved
11 - Not available
Note:  SPN 1661 should be used for reporting diagnostics of the Engine Idle Management Active Lamp.";
CM_ SG_ 2566719486 EngCoolantLevelLowLampCmd "Command signal directly controlling the Engine Coolant Level Low Lamp
00 - Lamp Off
01 - Lamp On
10 - Reserved
11 - Not available";
CM_ SG_ 2566719486 EngCoolantTempHighLampCmd "Command signal directly controlling the Engine Coolant Temperature High Lamp
00 - Lamp Off
01 - Lamp On
10 - Reserved
11 - Not available";
CM_ SG_ 2566719486 EngOilPressLowLampCmd "Command signal directly controlling the Engine Oil Pressure Low Lamp
00 - Lamp Off
01 - Lamp On
10 - Reserved
11 - Not available";
CM_ SG_ 2566719486 CmprssnBrkEnblSwtchIndctrLampCmd "Command signal directly controlling Compression Brake Enable Switch Indicator Lamp.  The compression brake switch indicator signals the status of the compression brake enable switch to the operator.
00 - Lamp OFF
01 - Lamp ON
10 - Reserved
11 - ...";
CM_ SG_ 2566719486 EngBrakeActiveLampCmd "Command signal directly controlling the Engine Brake Active Lamp. This is used for engine based retarders.
00 - Lamp Off
01 - Lamp On
10 - Reserved
11 - Not available";
CM_ SG_ 2566719486 OBDMalfunctionIndicatorLampCmd "Command signal directly controlling the OBD Malfunction Indicator Lamp
00 - Lamp Off
01 - Lamp On
10 - Reserved
11 - Not available
Note:  SPN 1213 should be used for reporting diagnostics of the OBD Malfunction Indicator Lamp.";
CM_ SG_ 2566719486 EngRedStopLampCmd "Command signal directly controlling the Engine Red Stop Lamp
00 - Lamp Off
01 - Lamp On
10 - Reserved
11 - Not available
Note:  SPN 623 should be used for reporting diagnostics of the Engine Red Stop Lamp.";
CM_ SG_ 2566719486 EngAmberWarningLampCmd "Command signal directly controlling the Engine Amber Warning Lamp
00 - Lamp Off
01 - Lamp On
10 - Reserved
11 - Not available
Note:  SPN 624 should be used for reporting diagnostics of the Engine Amber Warning Lamp.";
CM_ SG_ 2566719486 EngProtectLampCmd "Command signal directly controlling the Engine Protect Lamp
00 - Lamp Off
01 - Lamp On
10 - Reserved
11 - Not available
Note:  SPN 987 should be used for reporting diagnostics of the Engine Protect Lamp.";
CM_ SG_ 2633832702 RolloverSensorType "Type of Rollover Sensor.
0000 = acceleration sensor
0001 = pressure sensor
0010 = rollrate sensor
0011 = sonic sensor
0100 = fiber-optic sensor
0101 = radar sensor
0110 = lidar sensor
0111 = optical sensor
1000-1101 =  Reserved
1110 = ...";
CM_ SG_ 2633832702 RearCollisionSensor4Type "Type of Rear Collision Sensor 4.
0000 = acceleration sensor
0001 = pressure sensor
0010 = rollrate sensor
0011 = sonic sensor
0100 = fiber-optic sensor
0101 = radar sensor
0110 = lidar sensor
0111 = optical sensor
1000-1101 =  Reserved
...";
CM_ SG_ 2633832702 RearCollisionSensor3Type "Type of Rear Collision Sensor 3.
0000 = acceleration sensor
0001 = pressure sensor
0010 = rollrate sensor
0011 = sonic sensor
0100 = fiber-optic sensor
0101 = radar sensor
0110 = lidar sensor
0111 = optical sensor
1000-1101 =  Reserved
...";
CM_ SG_ 2633832702 RearCollisionSensor2Type "Type of Rear Collision Sensor 2.
0000 = acceleration sensor
0001 = pressure sensor
0010 = rollrate sensor
0011 = sonic sensor
0100 = fiber-optic sensor
0101 = radar sensor
0110 = lidar sensor
0111 = optical sensor
1000-1101 =  Reserved
...";
CM_ SG_ 2633832702 RearCollisionSensor1Type "Type of Rear Collision Sensor 1.
0000 = acceleration sensor
0001 = pressure sensor
0010 = rollrate sensor
0011 = sonic sensor
0100 = fiber-optic sensor
0101 = radar sensor
0110 = lidar sensor
0111 = optical sensor
1000-1101 =  Reserved
...";
CM_ SG_ 2633832702 SideCollisionSensorRearRightType "Type of Side Collision Sensor Rear - Right.
0000 = acceleration sensor
0001 = pressure sensor
0010 = rollrate sensor
0011 = sonic sensor
0100 = fiber-optic sensor
0101 = radar sensor
0110 = lidar sensor
0111 = optical sensor
1000-1101 = ...";
CM_ SG_ 2633832702 SdCllisionSensorMidRearRightType "Type of Side Collision Sensor Mid Rear - Right.
0000 = acceleration sensor
0001 = pressure sensor
0010 = rollrate sensor
0011 = sonic sensor
0100 = fiber-optic sensor
0101 = radar sensor
0110 = lidar sensor
0111 = optical sensor
1000-1101 = ...";
CM_ SG_ 2633832702 SdCllsionSensorMidFrontRightType "Type of Side Collision Sensor Mid Front - Right.
0000 = acceleration sensor
0001 = pressure sensor
0010 = rollrate sensor
0011 = sonic sensor
0100 = fiber-optic sensor
0101 = radar sensor
0110 = lidar sensor
0111 = optical sensor
1000-1101 ...";
CM_ SG_ 2633832702 SdeCollisionSensorFrontRightType "Type of Side Collision Sensor Front - Right.
0000 = acceleration sensor
0001 = pressure sensor
0010 = rollrate sensor
0011 = sonic sensor
0100 = fiber-optic sensor
0101 = radar sensor
0110 = lidar sensor
0111 = optical sensor
1000-1101 = ...";
CM_ SG_ 2633832702 SideCollisionSensorRearLeftType "Type of Side Collision Sensor Rear - Left.
0000 = acceleration sensor
0001 = pressure sensor
0010 = rollrate sensor
0011 = sonic sensor
0100 = fiber-optic sensor
0101 = radar sensor
0110 = lidar sensor
0111 = optical sensor
1000-1101 = ...";
CM_ SG_ 2633832702 SdCollisionSensorMidRearLeftType "Type of Side Collision Sensor Mid Rear - Left.
0000 = acceleration sensor
0001 = pressure sensor
0010 = rollrate sensor
0011 = sonic sensor
0100 = fiber-optic sensor
0101 = radar sensor
0110 = lidar sensor
0111 = optical sensor
1000-1101 = ...";
CM_ SG_ 2633832702 SdCllisionSensorMidFrontLeftType "Type of Side Collision Sensor Mid Front - Left.
0000 = acceleration sensor
0001 = pressure sensor
0010 = rollrate sensor
0011 = sonic sensor
0100 = fiber-optic sensor
0101 = radar sensor
0110 = lidar sensor
0111 = optical sensor
1000-1101 = ...";
CM_ SG_ 2633832702 SideCollisionSensorFrontLeftType "Type of Side Collision Sensor Front - Left.
0000 = acceleration sensor
0001 = pressure sensor
0010 = rollrate sensor
0011 = sonic sensor
0100 = fiber-optic sensor
0101 = radar sensor
0110 = lidar sensor
0111 = optical sensor
1000-1101 = ...";
CM_ SG_ 2633832702 FrontalCollisionSensor4Type "Type of Frontal Collision Sensor 4.
0000 = acceleration sensor
0001 = pressure sensor
0010 = rollrate sensor
0011 = sonic sensor
0100 = fiber-optic sensor
0101 = radar sensor
0110 = lidar sensor
0111 = optical sensor
1000-1101 =  Reserved
...";
CM_ SG_ 2633832702 FrontalCollisionSensor3Type "Type of Frontal Collision Sensor 3.
0000 = acceleration sensor
0001 = pressure sensor
0010 = rollrate sensor
0011 = sonic sensor
0100 = fiber-optic sensor
0101 = radar sensor
0110 = lidar sensor
0111 = optical sensor
1000-1101 =  Reserved
...";
CM_ SG_ 2633832702 FrontalCollisionSensor2Type "Type of Frontal Collision Sensor 2.
0000 = acceleration sensor
0001 = pressure sensor
0010 = rollrate sensor
0011 = sonic sensor
0100 = fiber-optic sensor
0101 = radar sensor
0110 = lidar sensor
0111 = optical sensor
1000-1101 =  Reserved
...";
CM_ SG_ 2633832702 FrontalCollisionSensor1Type "Type of Frontal Collision Sensor 1.
0000 = acceleration sensor
0001 = pressure sensor
0010 = rollrate sensor
0011 = sonic sensor
0100 = fiber-optic sensor
0101 = radar sensor
0110 = lidar sensor
0111 = optical sensor
1000-1101 =  Reserved
...";
CM_ SG_ 2163223550 CrashChecksum "The Crash Checksum is used to verify the signal path from the airbag ECU to other devices in case of a crash.
The 4 bit checksum is the sum of the high nibble and the low nibble of the sum of the identifier, the first 7 data bytes and the 4 bit ...";
CM_ SG_ 2163223550 CrashCounter "The Crash Counter prevents other ECUs from reacting to a faulty transmission of the Crash Notification PGN and serves as a safety mechanism. The Crash Counter becomes incremented by 1 for every sent message, starting with \"0\". (0 follows 15)";
CM_ SG_ 2163223550 CrashType "Type of crash event.
00001 = frontal crash
00010 = rear crash
00100 = side crash (left)
01000 = side crash (right)
10000 = rollover
It is possible to combine different Crash Types. (e.g. frontal and side crash (left) = 00101)";
CM_ SG_ 2566714878 EngChrgArClr2PrecoolerEfficiency "Engine charge air cooler 2 (CAC2) precooler efficiency is an indication of the precooler’s ability to reduce the temperature of the gas that is being routed through the precooler. 0% = no reduction in temperature, 100% = maximum cooling. The CAC2 ...";
CM_ SG_ 2566714878 EngChrgArClr2PrecoolerOutletTemp "Temperature of the combustion air measured at the charge air cooler 2 precooler outlet.";
CM_ SG_ 2566714878 EngChrgArClr2PrecoolerIntakeTemp "Temperature of the combustion air measured at the charge air cooler 2 precooler Intake.";
CM_ SG_ 2566714622 EngChargeAirCooler2Efficiency "Engine charge air cooler 2 (CAC2) is an indication of the CAC’s ability to reduce the temperature of the combustion air that is being routed through the CAC. 0% = no reduction in temperature, 100% = maximum cooling. The CAC2 efficiency is calculated ...";
CM_ SG_ 2566714622 EngChrgeAirCooler2AmbientAirTemp "Temperature of the air surrounding charge air cooler 2.";
CM_ SG_ 2566714622 EngChargeAirCooler2OutletTemp "Temperature of combustion air after it exits from the Charge Air Cooler 2 but before any mixing of recirculated exhaust gas.";
CM_ SG_ 2566714622 EngChargeAirCooler2IntakeTemp "Temperature of the combustion air measured at the charge air cooler 2 Intake.";
CM_ SG_ 2566715390 EngChrgArClr1PrecoolerEfficiency "Engine charge air cooler 1 (CAC1) precooler efficiency is an indication of the precooler’s ability to reduce the temperature of the combustion air that is being routed through the precooler. 0% = no reduction in temperature, 100% = maximum cooling ...";
CM_ SG_ 2566715390 EngChrgArClr1PrecoolerOutletTemp "Temperature of the combustion air measured at the charge air cooler 1 precooler outlet.";
CM_ SG_ 2566715390 EngChrgArClr1PrecoolerIntakeTemp "Temperature of the combustion air measured at the charge air cooler 1 precooler intake.";
CM_ SG_ 2566715134 EngChargeAirCooler1Efficiency "Engine charge air cooler 1(CAC1) efficiency is an indication of the CAC’s ability to reduce the temperature of the combustion air that is being routed through the CAC1. 0% = no reduction in temperature, 100% = maximum cooling. The CAC1 efficiency is ...";
CM_ SG_ 2566715134 EngChrgeAirCooler1AmbientAirTemp "Temperature of the air surrounding charge air cooler 1.";
CM_ SG_ 2566715134 EngChargeAirCooler1IntakeTemp "Temperature of the combustion air measured at the CAC 1 Intake.";
CM_ SG_ 2365400830 Joystick9Button9PressedStatus "Reports when the joystick button has been pressed.
00 Button not pressed
01 Button pressed
10 Error Indicator
11 Not Available";
CM_ SG_ 2365400830 Joystick9Button10PressedStatus "Reports when the joystick button has been pressed.
00 Button not pressed
01 Button pressed
10 Error Indicator
11 Not Available";
CM_ SG_ 2365400830 Joystick9Button11PressedStatus "Reports when the joystick button has been pressed.
00 Button not pressed
01 Button pressed
10 Error Indicator
11 Not Available";
CM_ SG_ 2365400830 Joystick9Button12PressedStatus "Reports when the joystick button has been pressed.
00 Button not pressed
01 Button pressed
10 Error Indicator
11 Not Available";
CM_ SG_ 2365400830 Joystick9Button5PressedStatus "Reports when the joystick button has been pressed.
00 Button not pressed
01 Button pressed
10 Error Indicator
11 Not Available";
CM_ SG_ 2365400830 Joystick9Button6PressedStatus "Reports when the joystick button has been pressed.
00 Button not pressed
01 Button pressed
10 Error Indicator
11 Not Available";
CM_ SG_ 2365400830 Joystick9Button7PressedStatus "Reports when the joystick button has been pressed.
00 Button not pressed
01 Button pressed
10 Error Indicator
11 Not Available";
CM_ SG_ 2365400830 Joystick9Button8PressedStatus "Reports when the joystick button has been pressed.
00 Button not pressed
01 Button pressed
10 Error Indicator
11 Not Available";
CM_ SG_ 2365400830 Joystick9Button1PressedStatus "Reports when the joystick button has been pressed.
00 Button not pressed
01 Button pressed
10 Error Indicator
11 Not Available";
CM_ SG_ 2365400830 Joystick9Button2PressedStatus "Reports when the joystick button has been pressed.
00 Button not pressed
01 Button pressed
10 Error Indicator
11 Not Available";
CM_ SG_ 2365400830 Joystick9Button3PressedStatus "Reports when the joystick button has been pressed.
00 Button not pressed
01 Button pressed
10 Error Indicator
11 Not Available";
CM_ SG_ 2365400830 Joystick9Button4PressedStatus "Reports when the joystick button has been pressed.
00 Button not pressed
01 Button pressed
10 Error Indicator
11 Not Available";
CM_ SG_ 2365400830 Joystick9XAxisDetentPosStatus "Reports when the current joystick position is in the detent position for that axis of travel.
00 Not in the Detent Position
01 In the Detent Position
10 Error Indicator
11 Not Available";
CM_ SG_ 2365400830 Joystick9YAxisDetentPosStatus "Reports when the current joystick position is in the detent position for that axis of travel.
00 Not in the Detent Position
01 In the Detent Position
10 Error Indicator
11 Not Available";
CM_ SG_ 2365400830 Joystick9YAxisPos "The position of the joystick in the relative motion of travel from the neutral position.  Position value of 0 is Neutral and position value 1000 (100%) is the end of linear zone.  Value of 1022 indicates an error has occurred.";
CM_ SG_ 2365400830 Jystck9YAxsLvrFrwrdPstvPosStatus "Reports when the current joystick position is on the positive travel side (forward, right, clockwise, up) relative to the neutral position for that axis of travel.
00 Not on Positive side of Neutral
01 On positive side of Neutral
10 Error ...";
CM_ SG_ 2365400830 Jystck9YAxsLvrBckNgtivePosStatus "Reports when the current joystick position is on the negative travel side (back, left, counterclockwise, down) relative to the neutral position for that axis of travel.
00 Not on negative side of Neutral
01 On negative side of Neutral
10 Error ...";
CM_ SG_ 2365400830 Joystick9YAxisNeutralPosStatus "Reports when the current joystick position is in the neutral position for that axis of travel.  The neutral position measurement must be determined from some mechanism other than the axis position measurement device.
00 Not in Neutral Position
01 ...";
CM_ SG_ 2365400830 Joystick9XAxisPos "The position of the joystick in the relative motion of travel from the neutral position.  Position value of 0 is Neutral and position value 1000 (100%) is the end of linear zone.  Value of 1022 indicates an error has occurred.";
CM_ SG_ 2365400830 Jystck9XAxsLvrRghtPstvePosStatus "Reports when the current joystick position is on the positive travel side (forward, right, clockwise, up) relative to the neutral position for that axis of travel.
00 Not on Positive side of Neutral
01 On positive side of Neutral
10 Error ...";
CM_ SG_ 2365400830 Jystck9XAxsLvrLftNgtivePosStatus "Reports when the current joystick position is on the negative travel side (back, left, counterclockwise, down) relative to the neutral position for that axis of travel.
00 Not on negative side of Neutral
01 On negative side of Neutral
10 Error ...";
CM_ SG_ 2365400830 Joystick9XAxisNeutralPosStatus "Reports when the current joystick position is in the neutral position for that axis of travel.  The neutral position measurement must be determined from some mechanism other than the axis position measurement device.
00 Not in Neutral Position
01 ...";
CM_ SG_ 2365401342 Joystick8Button9PressedStatus "Reports when the joystick button has been pressed.
00 Button not pressed
01 Button pressed
10 Error Indicator
11 Not Available";
CM_ SG_ 2365401342 Joystick8Button10PressedStatus "Reports when the joystick button has been pressed.
00 Button not pressed
01 Button pressed
10 Error Indicator
11 Not Available";
CM_ SG_ 2365401342 Joystick8Button11PressedStatus "Reports when the joystick button has been pressed.
00 Button not pressed
01 Button pressed
10 Error Indicator
11 Not Available";
CM_ SG_ 2365401342 Joystick8Button12PressedStatus "Reports when the joystick button has been pressed.
00 Button not pressed
01 Button pressed
10 Error Indicator
11 Not Available";
CM_ SG_ 2365401342 Joystick8Button5PressedStatus "Reports when the joystick button has been pressed.
00 Button not pressed
01 Button pressed
10 Error Indicator
11 Not Available";
CM_ SG_ 2365401342 Joystick8Button6PressedStatus "Reports when the joystick button has been pressed.
00 Button not pressed
01 Button pressed
10 Error Indicator
11 Not Available";
CM_ SG_ 2365401342 Joystick8Button7PressedStatus "Reports when the joystick button has been pressed.
00 Button not pressed
01 Button pressed
10 Error Indicator
11 Not Available";
CM_ SG_ 2365401342 Joystick8Button8PressedStatus "Reports when the joystick button has been pressed.
00 Button not pressed
01 Button pressed
10 Error Indicator
11 Not Available";
CM_ SG_ 2365401342 Joystick8Button1PressedStatus "Reports when the joystick button has been pressed.
00 Button not pressed
01 Button pressed
10 Error Indicator
11 Not Available";
CM_ SG_ 2365401342 Joystick8Button2PressedStatus "Reports when the joystick button has been pressed.
00 Button not pressed
01 Button pressed
10 Error Indicator
11 Not Available";
CM_ SG_ 2365401342 Joystick8Button3PressedStatus "Reports when the joystick button has been pressed.
00 Button not pressed
01 Button pressed
10 Error Indicator
11 Not Available";
CM_ SG_ 2365401342 Joystick8Button4PressedStatus "Reports when the joystick button has been pressed.
00 Button not pressed
01 Button pressed
10 Error Indicator
11 Not Available";
CM_ SG_ 2365401342 Joystick8XAxisDetentPosStatus "Reports when the current joystick position is in the detent position for that axis of travel.
00 Not in the Detent Position
01 In the Detent Position
10 Error Indicator
11 Not Available";
CM_ SG_ 2365401342 Joystick8YAxisDetentPosStatus "Reports when the current joystick position is in the detent position for that axis of travel.
00 Not in the Detent Position
01 In the Detent Position
10 Error Indicator
11 Not Available";
CM_ SG_ 2365401342 Joystick8YAxisPos "The position of the joystick in the relative motion of travel from the neutral position.  Position value of 0 is Neutral and position value 1000 (100%) is the end of linear zone.  Value of 1022 indicates an error has occurred.";
CM_ SG_ 2365401342 Jystck8YAxsLvrFrwrdPstvPosStatus "Reports when the current joystick position is on the positive travel side (forward, right, clockwise, up) relative to the neutral position for that axis of travel.
00 Not on Positive side of Neutral
01 On positive side of Neutral
10 Error ...";
CM_ SG_ 2365401342 Jystck8YAxsLvrBckNgtivePosStatus "Reports when the current joystick position is on the negative travel side (back, left, counterclockwise, down) relative to the neutral position for that axis of travel.
00 Not on negative side of Neutral
01 On negative side of Neutral
10 Error ...";
CM_ SG_ 2365401342 Joystick8YAxisNeutralPosStatus "Reports when the current joystick position is in the neutral position for that axis of travel.  The neutral position measurement must be determined from some mechanism other than the axis position measurement device.
00 Not in Neutral Position
01 ...";
CM_ SG_ 2365401342 Joystick8XAxisPos "The position of the joystick in the relative motion of travel from the neutral position.  Position value of 0 is Neutral and position value 1000 (100%) is the end of linear zone.  Value of 1022 indicates an error has occurred.";
CM_ SG_ 2365401342 Jystck8XAxsLvrRghtPstvePosStatus "Reports when the current joystick position is on the positive travel side (forward, right, clockwise, up) relative to the neutral position for that axis of travel.
00 Not on Positive side of Neutral
01 On positive side of Neutral
10 Error ...";
CM_ SG_ 2365401342 Jystck8XAxsLvrLftNgtivePosStatus "Reports when the current joystick position is on the negative travel side (back, left, counterclockwise, down) relative to the neutral position for that axis of travel.
00 Not on negative side of Neutral
01 On negative side of Neutral
10 Error ...";
CM_ SG_ 2365401342 Joystick8XAxisNeutralPosStatus "Reports when the current joystick position is in the neutral position for that axis of travel.  The neutral position measurement must be determined from some mechanism other than the axis position measurement device.
00 Not in Neutral Position
01 ...";
CM_ SG_ 2365401854 Joystick7Button9PressedStatus "Reports when the joystick button has been pressed.
00 Button not pressed
01 Button pressed
10 Error Indicator
11 Not Available";
CM_ SG_ 2365401854 Joystick7Button10PressedStatus "Reports when the joystick button has been pressed.
00 Button not pressed
01 Button pressed
10 Error Indicator
11 Not Available";
CM_ SG_ 2365401854 Joystick7Button11PressedStatus "Reports when the joystick button has been pressed.
00 Button not pressed
01 Button pressed
10 Error Indicator
11 Not Available";
CM_ SG_ 2365401854 Joystick7Button12PressedStatus "Reports when the joystick button has been pressed.
00 Button not pressed
01 Button pressed
10 Error Indicator
11 Not Available";
CM_ SG_ 2365401854 Joystick7Button5PressedStatus "Reports when the joystick button has been pressed.
00 Button not pressed
01 Button pressed
10 Error Indicator
11 Not Available";
CM_ SG_ 2365401854 Joystick7Button6PressedStatus "Reports when the joystick button has been pressed.
00 Button not pressed
01 Button pressed
10 Error Indicator
11 Not Available";
CM_ SG_ 2365401854 Joystick7Button7PressedStatus "Reports when the joystick button has been pressed.
00 Button not pressed
01 Button pressed
10 Error Indicator
11 Not Available";
CM_ SG_ 2365401854 Joystick7Button8PressedStatus "Reports when the joystick button has been pressed.
00 Button not pressed
01 Button pressed
10 Error Indicator
11 Not Available";
CM_ SG_ 2365401854 Joystick7Button1PressedStatus "Reports when the joystick button has been pressed.
00 Button not pressed
01 Button pressed
10 Error Indicator
11 Not Available";
CM_ SG_ 2365401854 Joystick7Button2PressedStatus "Reports when the joystick button has been pressed.
00 Button not pressed
01 Button pressed
10 Error Indicator
11 Not Available";
CM_ SG_ 2365401854 Joystick7Button3PressedStatus "Reports when the joystick button has been pressed.
00 Button not pressed
01 Button pressed
10 Error Indicator
11 Not Available";
CM_ SG_ 2365401854 Joystick7Button4PressedStatus "Reports when the joystick button has been pressed.
00 Button not pressed
01 Button pressed
10 Error Indicator
11 Not Available";
CM_ SG_ 2365401854 Joystick7XAxisDetentPosStatus "Reports when the current joystick position is in the detent position for that axis of travel.
00 Not in the Detent Position
01 In the Detent Position
10 Error Indicator
11 Not Available";
CM_ SG_ 2365401854 Joystick7YAxisDetentPosStatus "Reports when the current joystick position is in the detent position for that axis of travel.
00 Not in the Detent Position
01 In the Detent Position
10 Error Indicator
11 Not Available";
CM_ SG_ 2365401854 Joystick7YAxisPos "The position of the joystick in the relative motion of travel from the neutral position.  Position value of 0 is Neutral and position value 1000 (100%) is the end of linear zone.  Value of 1022 indicates an error has occurred.";
CM_ SG_ 2365401854 Jystck7YAxsLvrFrwrdPstvPosStatus "Reports when the current joystick position is on the positive travel side (forward, right, clockwise, up) relative to the neutral position for that axis of travel.
00 Not on Positive side of Neutral
01 On positive side of Neutral
10 Error ...";
CM_ SG_ 2365401854 Jystck7YAxsLvrBckNgtivePosStatus "Reports when the current joystick position is on the negative travel side (back, left, counterclockwise, down) relative to the neutral position for that axis of travel.
00 Not on negative side of Neutral
01 On negative side of Neutral
10 Error ...";
CM_ SG_ 2365401854 Joystick7YAxisNeutralPosStatus "Reports when the current joystick position is in the neutral position for that axis of travel.  The neutral position measurement must be determined from some mechanism other than the axis position measurement device.
00 Not in Neutral Position
01 ...";
CM_ SG_ 2365401854 Joystick7XAxisPos "The position of the joystick in the relative motion of travel from the neutral position.  Position value of 0 is Neutral and position value 1000 (100%) is the end of linear zone.  Value of 1022 indicates an error has occurred.";
CM_ SG_ 2365401854 Jystck7XAxsLvrRghtPstvePosStatus "Reports when the current joystick position is on the positive travel side (forward, right, clockwise, up) relative to the neutral position for that axis of travel.
00 Not on Positive side of Neutral
01 On positive side of Neutral
10 Error ...";
CM_ SG_ 2365401854 Jystck7XAxsLvrLftNgtivePosStatus "Reports when the current joystick position is on the negative travel side (back, left, counterclockwise, down) relative to the neutral position for that axis of travel.
00 Not on negative side of Neutral
01 On negative side of Neutral
10 Error ...";
CM_ SG_ 2365401854 Joystick7XAxisNeutralPosStatus "Reports when the current joystick position is in the neutral position for that axis of travel.  The neutral position measurement must be determined from some mechanism other than the axis position measurement device.
00 Not in Neutral Position
01 ...";
CM_ SG_ 2365402366 Joystick6Button9PressedStatus "Reports when the joystick button has been pressed.
00 Button not pressed
01 Button pressed
10 Error Indicator
11 Not Available";
CM_ SG_ 2365402366 Joystick6Button10PressedStatus "Reports when the joystick button has been pressed.
00 Button not pressed
01 Button pressed
10 Error Indicator
11 Not Available";
CM_ SG_ 2365402366 Joystick6Button11PressedStatus "Reports when the joystick button has been pressed.
00 Button not pressed
01 Button pressed
10 Error Indicator
11 Not Available";
CM_ SG_ 2365402366 Joystick6Button12PressedStatus "Reports when the joystick button has been pressed.
00 Button not pressed
01 Button pressed
10 Error Indicator
11 Not Available";
CM_ SG_ 2365402366 Joystick6Button5PressedStatus "Reports when the joystick button has been pressed.
00 Button not pressed
01 Button pressed
10 Error Indicator
11 Not Available";
CM_ SG_ 2365402366 Joystick6Button6PressedStatus "Reports when the joystick button has been pressed.
00 Button not pressed
01 Button pressed
10 Error Indicator
11 Not Available";
CM_ SG_ 2365402366 Joystick6Button7PressedStatus "Reports when the joystick button has been pressed.
00 Button not pressed
01 Button pressed
10 Error Indicator
11 Not Available";
CM_ SG_ 2365402366 Joystick6Button8PressedStatus "Reports when the joystick button has been pressed.
00 Button not pressed
01 Button pressed
10 Error Indicator
11 Not Available";
CM_ SG_ 2365402366 Joystick6Button1PressedStatus "Reports when the joystick button has been pressed.
00 Button not pressed
01 Button pressed
10 Error Indicator
11 Not Available";
CM_ SG_ 2365402366 Joystick6Button2PressedStatus "Reports when the joystick button has been pressed.
00 Button not pressed
01 Button pressed
10 Error Indicator
11 Not Available";
CM_ SG_ 2365402366 Joystick6Button3PressedStatus "Reports when the joystick button has been pressed.
00 Button not pressed
01 Button pressed
10 Error Indicator
11 Not Available";
CM_ SG_ 2365402366 Joystick6Button4PressedStatus "Reports when the joystick button has been pressed.
00 Button not pressed
01 Button pressed
10 Error Indicator
11 Not Available";
CM_ SG_ 2365402366 Joystick6XAxisDetentPosStatus "Reports when the current joystick position is in the detent position for that axis of travel.
00 Not in the Detent Position
01 In the Detent Position
10 Error Indicator
11 Not Available";
CM_ SG_ 2365402366 Joystick6YAxisDetentPosStatus "Reports when the current joystick position is in the detent position for that axis of travel.
00 Not in the Detent Position
01 In the Detent Position
10 Error Indicator
11 Not Available";
CM_ SG_ 2365402366 Joystick6YAxisPos "The position of the joystick in the relative motion of travel from the neutral position.  Position value of 0 is Neutral and position value 1000 (100%) is the end of linear zone.  Value of 1022 indicates an error has occurred.";
CM_ SG_ 2365402366 Jystck6YAxsLvrFrwrdPstvPosStatus "Reports when the current joystick position is on the positive travel side (forward, right, clockwise, up) relative to the neutral position for that axis of travel.
00 Not on Positive side of Neutral
01 On positive side of Neutral
10 Error ...";
CM_ SG_ 2365402366 Jystck6YAxsLvrBckNgtivePosStatus "Reports when the current joystick position is on the negative travel side (back, left, counterclockwise, down) relative to the neutral position for that axis of travel.
00 Not on negative side of Neutral
01 On negative side of Neutral
10 Error ...";
CM_ SG_ 2365402366 Joystick6YAxisNeutralPosStatus "Reports when the current joystick position is in the neutral position for that axis of travel.  The neutral position measurement must be determined from some mechanism other than the axis position measurement device.
00 Not in Neutral Position
01 ...";
CM_ SG_ 2365402366 Joystick6XAxisPos "The position of the joystick in the relative motion of travel from the neutral position.  Position value of 0 is Neutral and position value 1000 (100%) is the end of linear zone.  Value of 1022 indicates an error has occurred.";
CM_ SG_ 2365402366 Jystck6XAxsLvrRghtPstvePosStatus "Reports when the current joystick position is on the positive travel side (forward, right, clockwise, up) relative to the neutral position for that axis of travel.
00 Not on Positive side of Neutral
01 On positive side of Neutral
10 Error ...";
CM_ SG_ 2365402366 Jystck6XAxsLvrLftNgtivePosStatus "Reports when the current joystick position is on the negative travel side (back, left, counterclockwise, down) relative to the neutral position for that axis of travel.
00 Not on negative side of Neutral
01 On negative side of Neutral
10 Error ...";
CM_ SG_ 2365402366 Joystick6XAxisNeutralPosStatus "Reports when the current joystick position is in the neutral position for that axis of travel.  The neutral position measurement must be determined from some mechanism other than the axis position measurement device.
00 Not in Neutral Position
01 ...";
CM_ SG_ 2365402878 Joystick5Button9PressedStatus "Reports when the joystick button has been pressed.
00 Button not pressed
01 Button pressed
10 Error Indicator
11 Not Available";
CM_ SG_ 2365402878 Joystick5Button10PressedStatus "Reports when the joystick button has been pressed.
00 Button not pressed
01 Button pressed
10 Error Indicator
11 Not Available";
CM_ SG_ 2365402878 Joystick5Button11PressedStatus "Reports when the joystick button has been pressed.
00 Button not pressed
01 Button pressed
10 Error Indicator
11 Not Available";
CM_ SG_ 2365402878 Joystick5Button12PressedStatus "Reports when the joystick button has been pressed.
00 Button not pressed
01 Button pressed
10 Error Indicator
11 Not Available";
CM_ SG_ 2365402878 Joystick5Button5PressedStatus "Reports when the joystick button has been pressed.
00 Button not pressed
01 Button pressed
10 Error Indicator
11 Not Available";
CM_ SG_ 2365402878 Joystick5Button6PressedStatus "Reports when the joystick button has been pressed.
00 Button not pressed
01 Button pressed
10 Error Indicator
11 Not Available";
CM_ SG_ 2365402878 Joystick5Button7PressedStatus "Reports when the joystick button has been pressed.
00 Button not pressed
01 Button pressed
10 Error Indicator
11 Not Available";
CM_ SG_ 2365402878 Joystick5Button8PressedStatus "Reports when the joystick button has been pressed.
00 Button not pressed
01 Button pressed
10 Error Indicator
11 Not Available";
CM_ SG_ 2365402878 Joystick5Button1PressedStatus "Reports when the joystick button has been pressed.
00 Button not pressed
01 Button pressed
10 Error Indicator
11 Not Available";
CM_ SG_ 2365402878 Joystick5Button2PressedStatus "Reports when the joystick button has been pressed.
00 Button not pressed
01 Button pressed
10 Error Indicator
11 Not Available";
CM_ SG_ 2365402878 Joystick5Button3PressedStatus "Reports when the joystick button has been pressed.
00 Button not pressed
01 Button pressed
10 Error Indicator
11 Not Available";
CM_ SG_ 2365402878 Joystick5Button4PressedStatus "Reports when the joystick button has been pressed.
00 Button not pressed
01 Button pressed
10 Error Indicator
11 Not Available";
CM_ SG_ 2365402878 Joystick5XAxisDetentPosStatus "Reports when the current joystick position is in the detent position for that axis of travel.
00 Not in the Detent Position
01 In the Detent Position
10 Error Indicator
11 Not Available";
CM_ SG_ 2365402878 Joystick5YAxisDetentPosStatus "Reports when the current joystick position is in the detent position for that axis of travel.
00 Not in the Detent Position
01 In the Detent Position
10 Error Indicator
11 Not Available";
CM_ SG_ 2365402878 Joystick5YAxisPos "The position of the joystick in the relative motion of travel from the neutral position.  Position value of 0 is Neutral and position value 1000 (100%) is the end of linear zone.  Value of 1022 indicates an error has occurred.";
CM_ SG_ 2365402878 Jystck5YAxsLvrFrwrdPstvPosStatus "Reports when the current joystick position is on the positive travel side (forward, right, clockwise, up) relative to the neutral position for that axis of travel.
00 Not on Positive side of Neutral
01 On positive side of Neutral
10 Error ...";
CM_ SG_ 2365402878 Jystck5YAxsLvrBckNgtivePosStatus "Reports when the current joystick position is on the negative travel side (back, left, counterclockwise, down) relative to the neutral position for that axis of travel.
00 Not on negative side of Neutral
01 On negative side of Neutral
10 Error ...";
CM_ SG_ 2365402878 Joystick5YAxisNeutralPosStatus "Reports when the current joystick position is in the neutral position for that axis of travel.  The neutral position measurement must be determined from some mechanism other than the axis position measurement device.
00 Not in Neutral Position
01 ...";
CM_ SG_ 2365402878 Joystick5XAxisPos "The position of the joystick in the relative motion of travel from the neutral position.  Position value of 0 is Neutral and position value 1000 (100%) is the end of linear zone.  Value of 1022 indicates an error has occurred.";
CM_ SG_ 2365402878 Jystck5XAxsLvrRghtPstvePosStatus "Reports when the current joystick position is on the positive travel side (forward, right, clockwise, up) relative to the neutral position for that axis of travel.
00 Not on Positive side of Neutral
01 On positive side of Neutral
10 Error ...";
CM_ SG_ 2365402878 Jystck5XAxsLvrLftNgtivePosStatus "Reports when the current joystick position is on the negative travel side (back, left, counterclockwise, down) relative to the neutral position for that axis of travel.
00 Not on negative side of Neutral
01 On negative side of Neutral
10 Error ...";
CM_ SG_ 2365402878 Joystick5XAxisNeutralPosStatus "Reports when the current joystick position is in the neutral position for that axis of travel.  The neutral position measurement must be determined from some mechanism other than the axis position measurement device.
00 Not in Neutral Position
01 ...";
CM_ SG_ 2365403390 Joystick4Button9PressedStatus "Reports when the joystick button has been pressed.
00 Button not pressed
01 Button pressed
10 Error Indicator
11 Not Available";
CM_ SG_ 2365403390 Joystick4Button10PressedStatus "Reports when the joystick button has been pressed.
00 Button not pressed
01 Button pressed
10 Error Indicator
11 Not Available";
CM_ SG_ 2365403390 Joystick4Button11PressedStatus "Reports when the joystick button has been pressed.
00 Button not pressed
01 Button pressed
10 Error Indicator
11 Not Available";
CM_ SG_ 2365403390 Joystick4Button12PressedStatus "Reports when the joystick button has been pressed.
00 Button not pressed
01 Button pressed
10 Error Indicator
11 Not Available";
CM_ SG_ 2365403390 Joystick4Button5PressedStatus "Reports when the joystick button has been pressed.
00 Button not pressed
01 Button pressed
10 Error Indicator
11 Not Available";
CM_ SG_ 2365403390 Joystick4Button6PressedStatus "Reports when the joystick button has been pressed.
00 Button not pressed
01 Button pressed
10 Error Indicator
11 Not Available";
CM_ SG_ 2365403390 Joystick4Button7PressedStatus "Reports when the joystick button has been pressed.
00 Button not pressed
01 Button pressed
10 Error Indicator
11 Not Available";
CM_ SG_ 2365403390 Joystick4Button8PressedStatus "Reports when the joystick button has been pressed.
00 Button not pressed
01 Button pressed
10 Error Indicator
11 Not Available";
CM_ SG_ 2365403390 Joystick4Button1PressedStatus "Reports when the joystick button has been pressed.
00 Button not pressed
01 Button pressed
10 Error Indicator
11 Not Available";
CM_ SG_ 2365403390 Joystick4Button2PressedStatus "Reports when the joystick button has been pressed.
00 Button not pressed
01 Button pressed
10 Error Indicator
11 Not Available";
CM_ SG_ 2365403390 Joystick4Button3PressedStatus "Reports when the joystick button has been pressed.
00 Button not pressed
01 Button pressed
10 Error Indicator
11 Not Available";
CM_ SG_ 2365403390 Joystick4Button4PressedStatus "Reports when the joystick button has been pressed.
00 Button not pressed
01 Button pressed
10 Error Indicator
11 Not Available";
CM_ SG_ 2365403390 Joystick4XAxisDetentPosStatus "Reports when the current joystick position is in the detent position for that axis of travel.
00 Not in the Detent Position
01 In the Detent Position
10 Error Indicator
11 Not Available";
CM_ SG_ 2365403390 Joystick4YAxisDetentPosStatus "Reports when the current joystick position is in the detent position for that axis of travel.
00 Not in the Detent Position
01 In the Detent Position
10 Error Indicator
11 Not Available";
CM_ SG_ 2365403390 Joystick4YAxisPos "The position of the joystick in the relative motion of travel from the neutral position.  Position value of 0 is Neutral and position value 1000 (100%) is the end of linear zone.  Value of 1022 indicates an error has occurred.";
CM_ SG_ 2365403390 Jystck4YAxsLvrFrwrdPstvPosStatus "Reports when the current joystick position is on the positive travel side (forward, right, clockwise, up) relative to the neutral position for that axis of travel.
00 Not on Positive side of Neutral
01 On positive side of Neutral
10 Error ...";
CM_ SG_ 2365403390 Jystck4YAxsLvrBckNgtivePosStatus "Reports when the current joystick position is on the negative travel side (back, left, counterclockwise, down) relative to the neutral position for that axis of travel.
00 Not on negative side of Neutral
01 On negative side of Neutral
10 Error ...";
CM_ SG_ 2365403390 Joystick4YAxisNeutralPosStatus "Reports when the current joystick position is in the neutral position for that axis of travel.  The neutral position measurement must be determined from some mechanism other than the axis position measurement device.
00 Not in Neutral Position
01 ...";
CM_ SG_ 2365403390 Joystick4XAxisPos "The position of the joystick in the relative motion of travel from the neutral position.  Position value of 0 is Neutral and position value 1000 (100%) is the end of linear zone.  Value of 1022 indicates an error has occurred.";
CM_ SG_ 2365403390 Jystck4XAxsLvrRghtPstvePosStatus "Reports when the current joystick position is on the positive travel side (forward, right, clockwise, up) relative to the neutral position for that axis of travel.
00 Not on Positive side of Neutral
01 On positive side of Neutral
10 Error ...";
CM_ SG_ 2365403390 Jystck4XAxsLvrLftNgtivePosStatus "Reports when the current joystick position is on the negative travel side (back, left, counterclockwise, down) relative to the neutral position for that axis of travel.
00 Not on negative side of Neutral
01 On negative side of Neutral
10 Error ...";
CM_ SG_ 2365403390 Joystick4XAxisNeutralPosStatus "Reports when the current joystick position is in the neutral position for that axis of travel.  The neutral position measurement must be determined from some mechanism other than the axis position measurement device.
00 Not in Neutral Position
01 ...";
CM_ SG_ 2365400318 Joystick10Button9PressedStatus "Reports when the joystick button has been pressed.
00 Button not pressed
01 Button pressed
10 Error Indicator
11 Not Available";
CM_ SG_ 2365400318 Joystick10Button10PressedStatus "Reports when the joystick button has been pressed.
00 Button not pressed
01 Button pressed
10 Error Indicator
11 Not Available";
CM_ SG_ 2365400318 Joystick10Button11PressedStatus "Reports when the joystick button has been pressed.
00 Button not pressed
01 Button pressed
10 Error Indicator
11 Not Available";
CM_ SG_ 2365400318 Joystick10Button12PressedStatus "Reports when the joystick button has been pressed.
00 Button not pressed
01 Button pressed
10 Error Indicator
11 Not Available";
CM_ SG_ 2365400318 Joystick10Button5PressedStatus "Reports when the joystick button has been pressed.
00 Button not pressed
01 Button pressed
10 Error Indicator
11 Not Available";
CM_ SG_ 2365400318 Joystick10Button6PressedStatus "Reports when the joystick button has been pressed.
00 Button not pressed
01 Button pressed
10 Error Indicator
11 Not Available";
CM_ SG_ 2365400318 Joystick10Button7PressedStatus "Reports when the joystick button has been pressed.
00 Button not pressed
01 Button pressed
10 Error Indicator
11 Not Available";
CM_ SG_ 2365400318 Joystick10Button8PressedStatus "Reports when the joystick button has been pressed.
00 Button not pressed
01 Button pressed
10 Error Indicator
11 Not Available";
CM_ SG_ 2365400318 Joystick10Button1PressedStatus "Reports when the joystick button has been pressed.
00 Button not pressed
01 Button pressed
10 Error Indicator
11 Not Available";
CM_ SG_ 2365400318 Joystick10Button2PressedStatus "Reports when the joystick button has been pressed.
00 Button not pressed
01 Button pressed
10 Error Indicator
11 Not Available";
CM_ SG_ 2365400318 Joystick10Button3PressedStatus "Reports when the joystick button has been pressed.
00 Button not pressed
01 Button pressed
10 Error Indicator
11 Not Available";
CM_ SG_ 2365400318 Joystick10Button4PressedStatus "Reports when the joystick button has been pressed.
00 Button not pressed
01 Button pressed
10 Error Indicator
11 Not Available";
CM_ SG_ 2365400318 Joystick10XAxisDetentPosStatus "Reports when the current joystick position is in the detent position for that axis of travel.
00 Not in the Detent Position
01 In the Detent Position
10 Error Indicator
11 Not Available";
CM_ SG_ 2365400318 Joystick10YAxisDetentPosStatus "Reports when the current joystick position is in the detent position for that axis of travel.
00 Not in the Detent Position
01 In the Detent Position
10 Error Indicator
11 Not Available";
CM_ SG_ 2365400318 Joystick10YAxisPos "The position of the joystick in the relative motion of travel from the neutral position.  Position value of 0 is Neutral and position value 1000 (100%) is the end of linear zone.  Value of 1022 indicates an error has occurred.";
CM_ SG_ 2365400318 Jystck10YAxsLvrFrwrdPstvPsStatus "Reports when the current joystick position is on the positive travel side (forward, right, clockwise, up) relative to the neutral position for that axis of travel.
00 Not on Positive side of Neutral
01 On positive side of Neutral
10 Error ...";
CM_ SG_ 2365400318 Jystck10YAxsLvrBckNgtvePosStatus "Reports when the current joystick position is on the negative travel side (back, left, counterclockwise, down) relative to the neutral position for that axis of travel.
00 Not on negative side of Neutral
01 On negative side of Neutral
10 Error ...";
CM_ SG_ 2365400318 Joystick10YAxisNeutralPosStatus "Reports when the current joystick position is in the neutral position for that axis of travel.  The neutral position measurement must be determined from some mechanism other than the axis position measurement device.
00 Not in Neutral Position
01 ...";
CM_ SG_ 2365400318 Joystick10XAxisPos "The position of the joystick in the relative motion of travel from the neutral position.  Position value of 0 is Neutral and position value 1000 (100%) is the end of linear zone.  Value of 1022 indicates an error has occurred.";
CM_ SG_ 2365400318 Jystck10XAxsLvrRghtPstvPosStatus "Reports when the current joystick position is on the positive travel side (forward, right, clockwise, up) relative to the neutral position for that axis of travel.
00 Not on Positive side of Neutral
01 On positive side of Neutral
10 Error ...";
CM_ SG_ 2365400318 Jystck10XAxsLvrLftNgtvePosStatus "Reports when the current joystick position is on the negative travel side (back, left, counterclockwise, down) relative to the neutral position for that axis of travel.
00 Not on negative side of Neutral
01 On negative side of Neutral
10 Error ...";
CM_ SG_ 2365400318 Joystick10XAxisNeutralPosStatus "Reports when the current joystick position is in the neutral position for that axis of travel.  The neutral position measurement must be determined from some mechanism other than the axis position measurement device.
00 Not in Neutral Position
01 ...";
CM_ SG_ 2499614718 PssngrArbgDctivationSwitchStatus "State of switch used to deactivate Passenger Airbag manually.
00 = passenger airbag activated
01 = passenger airbag deactivated
10 = Error - State of deactivation switch cannot be determined
11 = not available";
CM_ SG_ 2499614718 Beltlock10Status "State of switch used to determine if Beltlock 10 is buckled.
00 = unlocked
01 = locked
10 = Error - Beltlock state cannot be determined
11 = not available";
CM_ SG_ 2499614718 Beltlock9Status "State of switch used to determine if Beltlock 9 is buckled.
00 = unlocked
01 = locked
10 = Error - Beltlock state cannot be determined
11 = not available";
CM_ SG_ 2499614718 Beltlock8Status "State of switch used to determine if Beltlock 8 is buckled.
00 = unlocked
01 = locked
10 = Error - Beltlock state cannot be determined
11 = not available";
CM_ SG_ 2499614718 Beltlock7Status "State of switch used to determine if Beltlock 7 is buckled.
00 = unlocked
01 = locked
10 = Error - Beltlock state cannot be determined
11 = not available";
CM_ SG_ 2499614718 Beltlock6Status "State of switch used to determine if Beltlock 6 is buckled.
00 = unlocked
01 = locked
10 = Error - Beltlock state cannot be determined
11 = not available";
CM_ SG_ 2499614718 Beltlock5Status "State of switch used to determine if Beltlock 5 is buckled.
00 = unlocked
01 = locked
10 = Error - Beltlock state cannot be determined
11 = not available";
CM_ SG_ 2499614718 Beltlock4Status "State of switch used to determine if Beltlock 4 is buckled.
00 = unlocked
01 = locked
10 = Error - Beltlock state cannot be determined
11 = not available";
CM_ SG_ 2499614718 Beltlock3Status "State of switch used to determine if Beltlock 3 is buckled.
00 = unlocked
01 = locked
10 = Error - Beltlock state cannot be determined
11 = not available";
CM_ SG_ 2499614718 PassengerBeltlockStatus "State of switch used to determine if Passenger Beltlock is buckled.
00 = unlocked
01 = locked
10 = Error - Beltlock state cannot be determined
11 = not available";
CM_ SG_ 2499614718 DriverBeltlockStatus "State of switch used to determine if Driver Beltlock is buckled.
00 = unlocked
01 = locked
10 = Error - Beltlock state cannot be determined
11 = not available";
CM_ SG_ 2566722814 BatteryCharger2OutputCurrent "Output current of the battery charger connected to the main battery. If positive, this parameter shows the charging current of the battery charger connected to the main battery.  Otherwise, if the charger hardware permits, this parameter represents ...";
CM_ SG_ 2566722814 BatteryCharger2OutputVoltage "Output voltage measured on the battery terminals of the offline battery charger connected to the auxiliary battery.";
CM_ SG_ 2566722814 BatteryCharger2PowerLineState "A state of the battery charger connection to the power line for the charger connected to the auxiliary battery.
0 - Disconnected. The power line is disconnected from the charger.
1 - Connected. The power line is connected to the charger.
2 - ...";
CM_ SG_ 2566722814 BatteryCharger2State "A state of the offline battery charger connected to the auxiliary battery.
0 - Idling. The power line or the battery is disconnected from the charger.
1 - Charging the battery.
2 - Stand-by or maintaining the battery charge.
3 to 12 - Reserved
...";
CM_ SG_ 2566723070 BatteryCharger1OutputCurrent "Output current of the battery charger connected to the main battery. If positive, this parameter shows the charging current of the battery charger connected to the main battery.  Otherwise, if the charger hardware permits, this parameter represents ...";
CM_ SG_ 2566723070 BatteryCharger1OutputVoltage "Output voltage measured on the battery terminals of the battery charger connected to the main battery.";
CM_ SG_ 2566723070 BatteryCharger1PowerLineState "A state of the battery charger connection to the power line for the charger connected to the main battery.
0 - Disconnected. The power line is disconnected from the charger.
1 - Connected. The power line is connected to the charger.
2 - Error
3 ...";
CM_ SG_ 2566723070 BatteryCharger1State "A state of the battery charger connected to the main battery.
0 - Idling. The power line or the battery is disconnected from the charger.
1 - Charging the battery.
2 - Stand-by or maintaining the battery charge.
3 to 12 - Reserved
13 - Battery ...";
CM_ SG_ 2566725118 TwoTWCDiffTemp "The differential engine combustion byproducts gas temperature measured between the intake and outlet of the three way catalyst for exhaust bank 2.";
CM_ SG_ 2566725118 OneTWCDiffTemp "The differential engine combustion byproducts gas temperature measured between the intake and outlet of the three way catalyst for exhaust bank 1.";
CM_ SG_ 2566725374 TwoGOCDiffTemp "The differential engine combustion byproducts gas temperature measured between the intake and outlet of the gas oxidation catalyst for exhaust bank 2.  This parameter should be used with engine fueled by gaseous fuel like natural gas or propane ...";
CM_ SG_ 2566725374 OneGOCDiffTemp "The differential engine combustion byproducts gas temperature measured between the intake and outlet of the gas oxidation catalyst for exhaust bank 1.  This parameter should be used with engine fueled by gaseous fuel like natural gas or propane ...";
CM_ SG_ 2566712830 OutTemp "Temperature of engine combustion byproducts leaving the warm up Diesel Oxidation Catalyst in exhaust bank 2.  This diesel parameter should be used with engines fueled by diesel fuel (not gaseous fuel like natural gas or propane).  A separate ...";
CM_ SG_ 2566712830 InTemp "Temperature of engine combustion byproducts entering the warm up Diesel Oxidation Catalyst in exhaust bank 2.  This diesel parameter should be used with engines fueled by diesel fuel (not gaseous fuel like natural gas or propane).  A separate ...";
CM_ SG_ 2566735358 DiffPressPreliminaryFMI "Used to identify the applicable J1939-73 FMI detected in the Three Way Catalytic Converter differential pressure sensor by the manufacturer’s sensor control software in exhaust bank 2. When there is no failure FMI 31 is sent. In the case of multiple ...";
CM_ SG_ 2566735358 OutTempPreliminaryFMI "Used to identify the applicable J1939-73 FMI detected in the Three Way Catalyst outlet temperature sensor by the manufacturer’s sensor control software in exhaust bank 2. When there is no failure FMI 31 is sent. In the case of multiple failures the ...";
CM_ SG_ 2566735358 InTempPreliminaryFMI "Used to identify the applicable J1939-73 FMI detected in the Three Way Catalyst intake temperature sensor by the manufacturer’s sensor control software in exhaust bank 2. When there is no failure FMI 31 is sent. In the case of multiple failures the ...";
CM_ SG_ 2566735358 DiffPress "Exhaust differential pressure measured between the intake and exhaust of a Three Way Catalyst in exhaust bank 2.
(For a single exhaust bank system, refer to parameters in PGN 64838.)";
CM_ SG_ 2566735358 OutTemp "Temperature of engine combustion byproducts leaving the Three Way Catalyst in exhaust bank 2.
(For a single exhaust bank system, refer to parameters in PGN 64838.)";
CM_ SG_ 2566735358 InTemp "Temperature of engine combustion byproducts entering the Three Way Catalyst in exhaust bank 2.
(For a single exhaust bank system, refer to parameters in PGN 64838.)";

BA_DEF_ BO_ "GenMsgCycleTime" INT 0 3600000;
BA_DEF_ BO_ "GenMsgCycleTimeFast" INT 0 3600000;
BA_DEF_ BO_ "GenMsgDelayTime" INT 0 1000;
BA_DEF_ BO_ "GenMsgILSupport" ENUM  "No","Yes";
BA_DEF_ BO_ "GenMsgRequestable" INT 0 1;
BA_DEF_ BO_ "GenMsgSendType" ENUM  "cyclic","spontaneous","cyclicIfActive","spontaneousWithDelay","cyclicAndSpontaneous","cyclicAndSpontaneousWithDelay","spontaneousWithRepetition","cyclicIfActiveAndSpontaneousWD";
BA_DEF_ BO_ "GenMsgStartDelayTime" INT 0 100000;
BA_DEF_ BO_ "J1939PGNameSecSrc0Dest3" STRING;
BA_DEF_ BO_ "J1939PGPrio" INT 0 7;
BA_DEF_ BO_ "J1939PGPrioSrc0Dest3" INT 0 7;
BA_DEF_ BO_ "J1939PGRelationDest3Src0" INT 0 254;
BA_DEF_ BO_ "J1939PGRelationSrc0Dest3" INT 0 254;
BA_DEF_ BO_ "J1939PGRepCycleSrc0Dest3" INT -1 65535;
BA_DEF_ BO_ "J1939PGRepTypeSrc0Dest3" INT 0 4;
BA_DEF_ BO_ "J1939PGRepetitionCycle" INT 0 65535;
BA_DEF_ BO_ "J1939PGRepetitionType" ENUM  "always","when active","on request";
BA_DEF_ BO_ "J1939PGtoECUSrc0Dest3" INT 0 254;
BA_DEF_ BO_ "J1939PGtoWSMSrc0Dest3" INT 0 254;
BA_DEF_ BO_ "TpJ1939VarDlc" ENUM  "No","Yes";
BA_DEF_ BO_ "VFrameFormat" ENUM  "StandardCAN","ExtendedCAN","reserved","J1939PG";
BA_DEF_ SG_ "GenSigEVName" STRING;
BA_DEF_ SG_ "GenSigILSupport" ENUM  "No","Yes";
BA_DEF_ SG_ "GenSigSendType" ENUM  "Cyclic","OnWrite","OnWriteWithRepetition","OnChange","OnChangeWithRepetition","IfActive","IfActiveWithRepetition","NoSigSendType";
BA_DEF_ SG_ "GenSigStartValue" INT 0 10000;
BA_DEF_ SG_ "SPN" INT 0 524287;
BA_DEF_ SG_ "SigType" ENUM  "Default","Range","RangeSigned","ASCII","Discrete","Control","ReferencePGN","DTC","StringDelimiter","StringLength","StringLengthControl","MessageCounter","MessageChecksum";
BA_DEF_ SG_ "SystemSignalLongSymbol" STRING;
BA_DEF_DEF_ "GenMsgCycleTime" 0;
BA_DEF_DEF_ "GenMsgCycleTimeFast" 0;
BA_DEF_DEF_ "GenMsgDelayTime" 0;
BA_DEF_DEF_ "GenMsgILSupport" "Yes";
BA_DEF_DEF_ "GenMsgRequestable" 1;
BA_DEF_DEF_ "GenMsgSendType" "noMsgSendType";
BA_DEF_DEF_ "GenMsgStartDelayTime" 0;
BA_DEF_DEF_ "GenSigEVName" "Env@Nodename_@Signame";
BA_DEF_DEF_ "GenSigILSupport" "Yes";
BA_DEF_DEF_ "GenSigSendType" "NoSigSendType";
BA_DEF_DEF_ "GenSigStartValue" 0;
BA_DEF_DEF_ "J1939PGNameSecSrc0Dest3" "(null)";
BA_DEF_DEF_ "J1939PGPrio" 6;
BA_DEF_DEF_ "J1939PGPrioSrc0Dest3" 6;
BA_DEF_DEF_ "J1939PGRelationDest3Src0" 254;
BA_DEF_DEF_ "J1939PGRelationSrc0Dest3" 254;
BA_DEF_DEF_ "J1939PGRepCycleSrc0Dest3" -1;
BA_DEF_DEF_ "J1939PGRepTypeSrc0Dest3" 3;
BA_DEF_DEF_ "J1939PGRepetitionCycle" 100;
BA_DEF_DEF_ "J1939PGRepetitionType" "always";
BA_DEF_DEF_ "J1939PGtoECUSrc0Dest3" -1;
BA_DEF_DEF_ "J1939PGtoWSMSrc0Dest3" -1;
BA_DEF_DEF_ "SPN" 0;
BA_DEF_DEF_ "SigType" "Default";
BA_DEF_DEF_ "SystemSignalLongSymbol" "";
BA_DEF_DEF_ "TpJ1939VarDlc" "No";
BA_DEF_DEF_ "VFrameFormat" "J1939PG";
BA_ "GenMsgCycleTime" BO_ 2563768062 5000;
BA_ "GenMsgSendType" BO_ 2563768062 0;
BA_ "GenMsgCycleTime" BO_ 2566771966 10000;
BA_ "GenMsgDelayTime" BO_ 2566771966 100;
BA_ "GenMsgSendType" BO_ 2566771966 0;
BA_ "GenMsgCycleTime" BO_ 2564882174 1000;
BA_ "GenMsgSendType" BO_ 2564882174 0;
BA_ "GenMsgCycleTime" BO_ 2563833598 5000;
BA_ "GenMsgDelayTime" BO_ 2563833598 100;
BA_ "GenMsgSendType" BO_ 2563833598 0;
BA_ "TpJ1939VarDlc" BO_ 2566843390 1;
BA_ "GenMsgCycleTime" BO_ 2566844926 100;
BA_ "GenMsgSendType" BO_ 2566844926 0;
BA_ "GenMsgCycleTime" BO_ 2566775294 1000;
BA_ "GenMsgSendType" BO_ 2566775294 0;
BA_ "GenMsgCycleTime" BO_ 2566803710 1000;
BA_ "GenMsgSendType" BO_ 2566803710 0;
BA_ "GenMsgCycleTime" BO_ 2566719486 1000;
BA_ "GenMsgDelayTime" BO_ 2566719486 100;
BA_ "GenMsgSendType" BO_ 2566719486 0;
BA_ "GenMsgCycleTime" BO_ 2163223550 20;
BA_ "GenMsgSendType" BO_ 2163223550 0;
BA_ "GenMsgCycleTime" BO_ 2566714878 1000;
BA_ "GenMsgSendType" BO_ 2566714878 0;
BA_ "GenMsgCycleTime" BO_ 2566714622 1000;
BA_ "GenMsgSendType" BO_ 2566714622 0;
BA_ "GenMsgCycleTime" BO_ 2566715390 1000;
BA_ "GenMsgSendType" BO_ 2566715390 0;
BA_ "GenMsgCycleTime" BO_ 2566715134 1000;
BA_ "GenMsgSendType" BO_ 2566715134 0;
BA_ "GenMsgCycleTime" BO_ 2365400830 100;
BA_ "GenMsgDelayTime" BO_ 2365400830 20;
BA_ "GenMsgSendType" BO_ 2365400830 0;
BA_ "GenMsgCycleTime" BO_ 2365401342 100;
BA_ "GenMsgDelayTime" BO_ 2365401342 20;
BA_ "GenMsgSendType" BO_ 2365401342 0;
BA_ "GenMsgCycleTime" BO_ 2365401854 100;
BA_ "GenMsgDelayTime" BO_ 2365401854 20;
BA_ "GenMsgSendType" BO_ 2365401854 0;
BA_ "GenMsgCycleTime" BO_ 2365402366 100;
BA_ "GenMsgDelayTime" BO_ 2365402366 20;
BA_ "GenMsgSendType" BO_ 2365402366 0;
BA_ "GenMsgCycleTime" BO_ 2365402878 100;
BA_ "GenMsgDelayTime" BO_ 2365402878 20;
BA_ "GenMsgSendType" BO_ 2365402878 0;
BA_ "GenMsgCycleTime" BO_ 2365403390 100;
BA_ "GenMsgDelayTime" BO_ 2365403390 20;
BA_ "GenMsgSendType" BO_ 2365403390 0;
BA_ "GenMsgCycleTime" BO_ 2365400318 100;
BA_ "GenMsgDelayTime" BO_ 2365400318 20;
BA_ "GenMsgSendType" BO_ 2365400318 0;
BA_ "GenMsgCycleTime" BO_ 2499614718 250;
BA_ "GenMsgSendType" BO_ 2499614718 0;
BA_ "GenMsgCycleTime" BO_ 2566722814 1000;
BA_ "GenMsgSendType" BO_ 2566722814 0;
BA_ "GenMsgCycleTime" BO_ 2566723070 1000;
BA_ "GenMsgSendType" BO_ 2566723070 0;
BA_ "GenMsgCycleTime" BO_ 2566712830 500;
BA_ "GenMsgSendType" BO_ 2566712830 0;
BA_ "GenMsgCycleTime" BO_ 2566735358 500;
BA_ "GenMsgSendType" BO_ 2566735358 0;
BA_ "SPN" SG_ 2498777854 EngCyl5AverageCombustionDuration 6502;
BA_ "SigType" SG_ 2498777854 EngCyl5AverageCombustionDuration 1;
BA_ "SPN" SG_ 2498777854 EngCyl5AvrgCntrOfCmbustionTiming 6501;
BA_ "SigType" SG_ 2498777854 EngCyl5AvrgCntrOfCmbustionTiming 1;
BA_ "SPN" SG_ 2498777854 EngCyl5AvrgStrtOfCmbustionTiming 6500;
BA_ "SigType" SG_ 2498777854 EngCyl5AvrgStrtOfCmbustionTiming 1;
BA_ "SPN" SG_ 2498777854 EngCyl5IndctedMeanEffectivePress 6499;
BA_ "SigType" SG_ 2498777854 EngCyl5IndctedMeanEffectivePress 1;
BA_ "SPN" SG_ 2498777598 EngCyl4AverageCombustionDuration 6498;
BA_ "SigType" SG_ 2498777598 EngCyl4AverageCombustionDuration 1;
BA_ "SPN" SG_ 2498777598 EngCyl4AvrgCntrOfCmbustionTiming 6497;
BA_ "SigType" SG_ 2498777598 EngCyl4AvrgCntrOfCmbustionTiming 1;
BA_ "SPN" SG_ 2498777598 EngCyl4AvrgStrtOfCmbustionTiming 6496;
BA_ "SigType" SG_ 2498777598 EngCyl4AvrgStrtOfCmbustionTiming 1;
BA_ "SPN" SG_ 2498777598 EngCyl4IndctedMeanEffectivePress 6495;
BA_ "SigType" SG_ 2498777598 EngCyl4IndctedMeanEffectivePress 1;
BA_ "SPN" SG_ 2498777342 EngCyl3AverageCombustionDuration 6494;
BA_ "SigType" SG_ 2498777342 EngCyl3AverageCombustionDuration 1;
BA_ "SPN" SG_ 2498777342 EngCyl3AvrgCntrOfCmbustionTiming 6493;
BA_ "SigType" SG_ 2498777342 EngCyl3AvrgCntrOfCmbustionTiming 1;
BA_ "SPN" SG_ 2498777342 EngCyl3AvrgStrtOfCmbustionTiming 6492;
BA_ "SigType" SG_ 2498777342 EngCyl3AvrgStrtOfCmbustionTiming 1;
BA_ "SPN" SG_ 2498777342 EngCyl3IndctedMeanEffectivePress 6491;
BA_ "SigType" SG_ 2498777342 EngCyl3IndctedMeanEffectivePress 1;
BA_ "SPN" SG_ 2566768382 EngCldStrtFlIgniterRelayFeedback 5550;
BA_ "SigType" SG_ 2566768382 EngCldStrtFlIgniterRelayFeedback 4;
BA_ "SPN" SG_ 2566768382 EngColdStartFuelIgniterRelay 5549;
BA_ "SigType" SG_ 2566768382 EngColdStartFuelIgniterRelay 5;
BA_ "SPN" SG_ 2566768382 EngColdStartFuelIgniterCmd 5548;
BA_ "SigType" SG_ 2566768382 EngColdStartFuelIgniterCmd 1;
BA_ "SPN" SG_ 2566768382 EngStartEnableDevice2Config 2898;
BA_ "SPN" SG_ 2566768382 EngStartEnableDevice1Config 2899;
BA_ "SPN" SG_ 2566768382 EngStartEnableDevice2 1804;
BA_ "SigType" SG_ 2566768382 EngStartEnableDevice2 5;
BA_ "SPN" SG_ 2566768382 EngStartEnableDevice1 626;
BA_ "SigType" SG_ 2566768382 EngStartEnableDevice1 5;
BA_ "SPN" SG_ 2566811902 PoweredVehicleWeight 1585;
BA_ "SigType" SG_ 2566811902 PoweredVehicleWeight 1;
BA_ "SPN" SG_ 2566811902 GrossCombinationVehicleWeight 1760;
BA_ "SigType" SG_ 2566811902 GrossCombinationVehicleWeight 1;
BA_ "SPN" SG_ 2563768062 MaxContnsRtdrTqLimitReq_1791 1791;
BA_ "SigType" SG_ 2563768062 MaxContnsRtdrTqLimitReq_1791 1;
BA_ "SPN" SG_ 2563768062 MinContnsRtdrTqLimitReq_1790 1790;
BA_ "SigType" SG_ 2563768062 MinContnsRtdrTqLimitReq_1790 1;
BA_ "SPN" SG_ 2563768062 MaxContnsRtdrSpdLimReq_1789 1789;
BA_ "SigType" SG_ 2563768062 MaxContnsRtdrSpdLimReq_1789 1;
BA_ "SPN" SG_ 2563768062 MinContnsRtdrSpdLimReq_1788 1788;
BA_ "SigType" SG_ 2563768062 MinContnsRtdrSpdLimReq_1788 1;
BA_ "GenSigStartValue" SG_ 2563768062 EngTorqueLimitRqMaxContns_1787 125;
BA_ "SPN" SG_ 2563768062 EngTorqueLimitRqMaxContns_1787 1787;
BA_ "SigType" SG_ 2563768062 EngTorqueLimitRqMaxContns_1787 1;
BA_ "GenSigStartValue" SG_ 2563768062 EngTorqueLimitRqMinContns_1786 125;
BA_ "SPN" SG_ 2563768062 EngTorqueLimitRqMinContns_1786 1786;
BA_ "SigType" SG_ 2563768062 EngTorqueLimitRqMinContns_1786 1;
BA_ "SPN" SG_ 2563768062 EngSpeedLimitRqMaxContns_1785 1785;
BA_ "SigType" SG_ 2563768062 EngSpeedLimitRqMaxContns_1785 1;
BA_ "SPN" SG_ 2563768062 EngSpeedLimitRqMinContns_1784 1784;
BA_ "SigType" SG_ 2563768062 EngSpeedLimitRqMinContns_1784 1;
BA_ "SPN" SG_ 2633924862 EngAverageCombustionTime 1465;
BA_ "SigType" SG_ 2633924862 EngAverageCombustionTime 1;
BA_ "SPN" SG_ 2633924862 EngDesiredCombustionTime 1464;
BA_ "SigType" SG_ 2633924862 EngDesiredCombustionTime 1;
BA_ "SPN" SG_ 2633924606 EngCyl20CombustionTime 1463;
BA_ "SigType" SG_ 2633924606 EngCyl20CombustionTime 1;
BA_ "SPN" SG_ 2633924606 EngCyl19CombustionTime 1462;
BA_ "SigType" SG_ 2633924606 EngCyl19CombustionTime 1;
BA_ "SPN" SG_ 2633924606 EngCyl18CombustionTime 1461;
BA_ "SigType" SG_ 2633924606 EngCyl18CombustionTime 1;
BA_ "SPN" SG_ 2633924606 EngCyl17CombustionTime 1460;
BA_ "SigType" SG_ 2633924606 EngCyl17CombustionTime 1;
BA_ "SPN" SG_ 2633924350 EngCyl16CombustionTime 1459;
BA_ "SigType" SG_ 2633924350 EngCyl16CombustionTime 1;
BA_ "SPN" SG_ 2633924350 EngCyl15CombustionTime 1458;
BA_ "SigType" SG_ 2633924350 EngCyl15CombustionTime 1;
BA_ "SPN" SG_ 2633924350 EngCyl14CombustionTime 1457;
BA_ "SigType" SG_ 2633924350 EngCyl14CombustionTime 1;
BA_ "SPN" SG_ 2633924350 EngCyl13CombustionTime 1456;
BA_ "SigType" SG_ 2633924350 EngCyl13CombustionTime 1;
BA_ "SPN" SG_ 2633924094 EngCyl12CombustionTime 1455;
BA_ "SigType" SG_ 2633924094 EngCyl12CombustionTime 1;
BA_ "SPN" SG_ 2633924094 EngCyl11CombustionTime 1454;
BA_ "SigType" SG_ 2633924094 EngCyl11CombustionTime 1;
BA_ "SPN" SG_ 2633924094 EngCyl10CombustionTime 1453;
BA_ "SigType" SG_ 2633924094 EngCyl10CombustionTime 1;
BA_ "SPN" SG_ 2633924094 EngCyl9CombustionTime 1452;
BA_ "SigType" SG_ 2633924094 EngCyl9CombustionTime 1;
BA_ "SPN" SG_ 2633923838 EngCyl8CombustionTime 1451;
BA_ "SigType" SG_ 2633923838 EngCyl8CombustionTime 1;
BA_ "SPN" SG_ 2633923838 EngCyl7CombustionTime 1450;
BA_ "SigType" SG_ 2633923838 EngCyl7CombustionTime 1;
BA_ "SPN" SG_ 2633923838 EngCyl6CombustionTime 1449;
BA_ "SigType" SG_ 2633923838 EngCyl6CombustionTime 1;
BA_ "SPN" SG_ 2633923838 EngCyl5CombustionTime 1448;
BA_ "SigType" SG_ 2633923838 EngCyl5CombustionTime 1;
BA_ "SPN" SG_ 2633923582 EngCyl4CombustionTime 1447;
BA_ "SigType" SG_ 2633923582 EngCyl4CombustionTime 1;
BA_ "SPN" SG_ 2633923582 EngCyl3CombustionTime 1446;
BA_ "SigType" SG_ 2633923582 EngCyl3CombustionTime 1;
BA_ "SPN" SG_ 2633923582 EngCyl2CombustionTime 1445;
BA_ "SigType" SG_ 2633923582 EngCyl2CombustionTime 1;
BA_ "SPN" SG_ 2633923582 EngCyl1CombustionTime 1444;
BA_ "SigType" SG_ 2633923582 EngCyl1CombustionTime 1;
BA_ "SPN" SG_ 2633878014 TotalCountOfConfigChangesMade 2887;
BA_ "SigType" SG_ 2633878014 TotalCountOfConfigChangesMade 1;
BA_ "SPN" SG_ 2566771966 VehTrailerStatus 7711;
BA_ "SigType" SG_ 2566771966 VehTrailerStatus 4;
BA_ "SPN" SG_ 2566771966 TransOilLevelRq 3809;
BA_ "SigType" SG_ 2566771966 TransOilLevelRq 5;
BA_ "SPN" SG_ 2566771966 FifthWheelReleaseCtrl 3314;
BA_ "SigType" SG_ 2566771966 FifthWheelReleaseCtrl 4;
BA_ "SPN" SG_ 2566771966 FfthWhlRleaseCtrlSecurityLockout 3315;
BA_ "SigType" SG_ 2566771966 FfthWhlRleaseCtrlSecurityLockout 4;
BA_ "SPN" SG_ 2566771966 TransferCaseSelectorSwitch 2796;
BA_ "SPN" SG_ 2564882174 SeldMaxVehSpdLimit_2596 2596;
BA_ "SigType" SG_ 2564882174 SeldMaxVehSpdLimit_2596 1;
BA_ "SPN" SG_ 2564882174 ReqCabZoneHeating_1686 1686;
BA_ "SigType" SG_ 2564882174 ReqCabZoneHeating_1686 5;
BA_ "SPN" SG_ 2564882174 ReqEngZoneHeating_1685 1685;
BA_ "SigType" SG_ 2564882174 ReqEngZoneHeating_1685 5;
BA_ "SPN" SG_ 2564882174 AuxHeaterModeReq_1683 1683;
BA_ "SPN" SG_ 2564882174 EngAutomaticStartEnableSw_1656 1656;
BA_ "SigType" SG_ 2564882174 EngAutomaticStartEnableSw_1656 4;
BA_ "SPN" SG_ 2564882174 AtuomaticGearShiftingEnSw_1666 1666;
BA_ "SigType" SG_ 2564882174 AtuomaticGearShiftingEnSw_1666 4;
BA_ "SPN" SG_ 2564882174 AFTRegenForceSw_3696 3696;
BA_ "SigType" SG_ 2564882174 AFTRegenForceSw_3696 4;
BA_ "SPN" SG_ 2564882174 AFTRegenInhSw_3695 3695;
BA_ "SigType" SG_ 2564882174 AFTRegenInhSw_3695 4;
BA_ "SPN" SG_ 2564882174 VehLmtngSpdGovrEnSw_1653 1653;
BA_ "SigType" SG_ 2564882174 VehLmtngSpdGovrEnSw_1653 4;
BA_ "SPN" SG_ 2564882174 VehLmtngSpdGvrnrIncrementSw_1654 1654;
BA_ "SigType" SG_ 2564882174 VehLmtngSpdGvrnrIncrementSw_1654 4;
BA_ "SPN" SG_ 2564882174 VehLmtngSpdGvrnrDecrementSw_1655 1655;
BA_ "SigType" SG_ 2564882174 VehLmtngSpdGvrnrDecrementSw_1655 4;
BA_ "SPN" SG_ 2564882174 ParkBrakeCmd_5630 5630;
BA_ "SigType" SG_ 2564882174 ParkBrakeCmd_5630 5;
BA_ "SPN" SG_ 2564882174 SeatBeltSwitch_1856 1856;
BA_ "SigType" SG_ 2564882174 SeatBeltSwitch_1856 4;
BA_ "SPN" SG_ 2564882174 OperatorSeatDirSw_1714 1714;
BA_ "SigType" SG_ 2564882174 OperatorSeatDirSw_1714 4;
BA_ "SPN" SG_ 2564882174 BatteryMainSwitchHoldRq_1682 1682;
BA_ "SigType" SG_ 2564882174 BatteryMainSwitchHoldRq_1682 5;
BA_ "SPN" SG_ 2564882174 AuxHeaterCoolantPumpRq_1684 1684;
BA_ "SigType" SG_ 2564882174 AuxHeaterCoolantPumpRq_1684 5;
BA_ "SPN" SG_ 2564882174 CabInteriorTempCmd_1691 1691;
BA_ "SigType" SG_ 2564882174 CabInteriorTempCmd_1691 1;
BA_ "SPN" SG_ 2564882174 RequestedPercentFanSpeed_986 986;
BA_ "SigType" SG_ 2564882174 RequestedPercentFanSpeed_986 1;
BA_ "SPN" SG_ 2563833598 SwtchBcklghtIllmntnBriPrcnt_5532 5532;
BA_ "SigType" SG_ 2563833598 SwtchBcklghtIllmntnBriPrcnt_5532 1;
BA_ "SPN" SG_ 2563833598 IlluminationBriPercent_1487 1487;
BA_ "SigType" SG_ 2563833598 IlluminationBriPercent_1487 1;
BA_ "SPN" SG_ 2563833598 SwtchIndctnIllmntnBriPrcent_6820 6820;
BA_ "SigType" SG_ 2563833598 SwtchIndctnIllmntnBriPrcent_6820 1;
BA_ "SPN" SG_ 2566843390 UnitNumber 233;
BA_ "SigType" SG_ 2566843390 UnitNumber 8;
BA_ "SPN" SG_ 2566843390 SerialNumber 588;
BA_ "SigType" SG_ 2566843390 SerialNumber 8;
BA_ "SPN" SG_ 2566843390 Model 587;
BA_ "SigType" SG_ 2566843390 Model 8;
BA_ "SPN" SG_ 2566843390 Make 586;
BA_ "SigType" SG_ 2566843390 Make 8;
BA_ "SPN" SG_ 2566844926 EngShutdownOverrideSwitch 1237;
BA_ "SigType" SG_ 2566844926 EngShutdownOverrideSwitch 4;
BA_ "SPN" SG_ 2566844926 EngTestModeSwitch 966;
BA_ "SigType" SG_ 2566844926 EngTestModeSwitch 4;
BA_ "SPN" SG_ 2566844926 EngIdleDecrementSwitch 967;
BA_ "SigType" SG_ 2566844926 EngIdleDecrementSwitch 4;
BA_ "SPN" SG_ 2566844926 EngIdleIncrementSwitch 968;
BA_ "SigType" SG_ 2566844926 EngIdleIncrementSwitch 4;
BA_ "SPN" SG_ 2566844926 CruiseCtrlStates 527;
BA_ "SPN" SG_ 2566844926 PTOGovernorState 976;
BA_ "SPN" SG_ 2566844926 CruiseCtrlSetSpeed 86;
BA_ "SigType" SG_ 2566844926 CruiseCtrlSetSpeed 1;
BA_ "SPN" SG_ 2566844926 CruiseCtrlAccelerateSwitch 602;
BA_ "SigType" SG_ 2566844926 CruiseCtrlAccelerateSwitch 4;
BA_ "SPN" SG_ 2566844926 CruiseCtrlResumeSwitch 601;
BA_ "SigType" SG_ 2566844926 CruiseCtrlResumeSwitch 4;
BA_ "SPN" SG_ 2566844926 CruiseCtrlCoastSwitch 600;
BA_ "SigType" SG_ 2566844926 CruiseCtrlCoastSwitch 4;
BA_ "SPN" SG_ 2566844926 CruiseCtrlSetSwitch 599;
BA_ "SigType" SG_ 2566844926 CruiseCtrlSetSwitch 4;
BA_ "SPN" SG_ 2566844926 ClutchSwitch 598;
BA_ "SigType" SG_ 2566844926 ClutchSwitch 4;
BA_ "SPN" SG_ 2566844926 BrakeSwitch 597;
BA_ "SigType" SG_ 2566844926 BrakeSwitch 4;
BA_ "SPN" SG_ 2566844926 CruiseCtrlEnableSwitch 596;
BA_ "SigType" SG_ 2566844926 CruiseCtrlEnableSwitch 4;
BA_ "SPN" SG_ 2566844926 CruiseCtrlActive 595;
BA_ "SigType" SG_ 2566844926 CruiseCtrlActive 4;
BA_ "SPN" SG_ 2566844926 WheelBasedVehicleSpeed 84;
BA_ "SigType" SG_ 2566844926 WheelBasedVehicleSpeed 1;
BA_ "SPN" SG_ 2566844926 ParkBrakeReleaseInhibitRq 3807;
BA_ "SigType" SG_ 2566844926 ParkBrakeReleaseInhibitRq 5;
BA_ "SPN" SG_ 2566844926 CruiseCtrlPauseSwitch 1633;
BA_ "SigType" SG_ 2566844926 CruiseCtrlPauseSwitch 4;
BA_ "SPN" SG_ 2566844926 ParkingBrakeSwitch 70;
BA_ "SigType" SG_ 2566844926 ParkingBrakeSwitch 4;
BA_ "SPN" SG_ 2566844926 TwoSpeedAxleSwitch 69;
BA_ "SigType" SG_ 2566844926 TwoSpeedAxleSwitch 4;
BA_ "SPN" SG_ 2566843902 MaxVehicleSpeedLimit6808 6808;
BA_ "SigType" SG_ 2566843902 MaxVehicleSpeedLimit6808 1;
BA_ "SPN" SG_ 2566843902 CruiseCtrlLowSetLimitSpeed 88;
BA_ "SigType" SG_ 2566843902 CruiseCtrlLowSetLimitSpeed 1;
BA_ "SPN" SG_ 2566843902 CruiseCtrlHighSetLimitSpeed 87;
BA_ "SigType" SG_ 2566843902 CruiseCtrlHighSetLimitSpeed 1;
BA_ "SPN" SG_ 2566843902 MaxVehicleSpeedLimit 74;
BA_ "SigType" SG_ 2566843902 MaxVehicleSpeedLimit 1;
BA_ "SPN" SG_ 2566809598 AuxHeaterMaxOutputPower 1690;
BA_ "SigType" SG_ 2566809598 AuxHeaterMaxOutputPower 1;
BA_ "SPN" SG_ 2633940222 TripServiceBrakeApplications 993;
BA_ "SigType" SG_ 2633940222 TripServiceBrakeApplications 1;
BA_ "SPN" SG_ 2633940222 TripServiceBrakeDistance 992;
BA_ "SigType" SG_ 2633940222 TripServiceBrakeDistance 1;
BA_ "SPN" SG_ 2633940222 TripCompressionBrakeDistance 991;
BA_ "SigType" SG_ 2633940222 TripCompressionBrakeDistance 1;
BA_ "SPN" SG_ 2633940222 TotalCompressionBrakeDistance 990;
BA_ "SigType" SG_ 2633940222 TotalCompressionBrakeDistance 1;
BA_ "SPN" SG_ 2566775294 CbA_CRfrgrntCmpressorOutletPress 2609;
BA_ "SigType" SG_ 2566775294 CbA_CRfrgrntCmpressorOutletPress 1;
BA_ "SPN" SG_ 2566803710 SLIBattery4Temp 2780;
BA_ "SigType" SG_ 2566803710 SLIBattery4Temp 1;
BA_ "SPN" SG_ 2566803710 SLIBattery3Temp 2779;
BA_ "SigType" SG_ 2566803710 SLIBattery3Temp 1;
BA_ "SPN" SG_ 2566803710 Battery2Temp 1801;
BA_ "SigType" SG_ 2566803710 Battery2Temp 1;
BA_ "SPN" SG_ 2566803710 Battery1Temp 1800;
BA_ "SigType" SG_ 2566803710 Battery1Temp 1;
BA_ "SPN" SG_ 2566719486 VhclAccelerationRateLimitLampCmd 6899;
BA_ "SigType" SG_ 2566719486 VhclAccelerationRateLimitLampCmd 5;
BA_ "SPN" SG_ 2566719486 EngSpeedVeryHighLampCmd 6710;
BA_ "SigType" SG_ 2566719486 EngSpeedVeryHighLampCmd 5;
BA_ "SPN" SG_ 2566719486 EngSpeedHighLampCmd 6709;
BA_ "SigType" SG_ 2566719486 EngSpeedHighLampCmd 5;
BA_ "SPN" SG_ 2566719486 EngCtrlModule3ReadyForUseLampCmd 6207;
BA_ "SigType" SG_ 2566719486 EngCtrlModule3ReadyForUseLampCmd 5;
BA_ "SPN" SG_ 2566719486 EngCtrlModule2ReadyForUseLampCmd 6206;
BA_ "SigType" SG_ 2566719486 EngCtrlModule2ReadyForUseLampCmd 5;
BA_ "SPN" SG_ 2566719486 EngCtrlModule1ReadyForUseLampCmd 6205;
BA_ "SigType" SG_ 2566719486 EngCtrlModule1ReadyForUseLampCmd 5;
BA_ "SPN" SG_ 2566719486 EngFuelFilterRestrictedLampCmd 5469;
BA_ "SigType" SG_ 2566719486 EngFuelFilterRestrictedLampCmd 5;
BA_ "SPN" SG_ 2566719486 EngAirFilterRestrictionLampCmd 5086;
BA_ "SigType" SG_ 2566719486 EngAirFilterRestrictionLampCmd 5;
BA_ "SPN" SG_ 2566719486 EngIdleManagementActiveLampCmd 5085;
BA_ "SigType" SG_ 2566719486 EngIdleManagementActiveLampCmd 5;
BA_ "SPN" SG_ 2566719486 EngCoolantLevelLowLampCmd 5084;
BA_ "SigType" SG_ 2566719486 EngCoolantLevelLowLampCmd 5;
BA_ "SPN" SG_ 2566719486 EngCoolantTempHighLampCmd 5083;
BA_ "SigType" SG_ 2566719486 EngCoolantTempHighLampCmd 5;
BA_ "SPN" SG_ 2566719486 EngOilPressLowLampCmd 5082;
BA_ "SigType" SG_ 2566719486 EngOilPressLowLampCmd 5;
BA_ "SPN" SG_ 2566719486 CmprssnBrkEnblSwtchIndctrLampCmd 3987;
BA_ "SigType" SG_ 2566719486 CmprssnBrkEnblSwtchIndctrLampCmd 5;
BA_ "SPN" SG_ 2566719486 EngBrakeActiveLampCmd 5081;
BA_ "SigType" SG_ 2566719486 EngBrakeActiveLampCmd 5;
BA_ "SPN" SG_ 2566719486 OBDMalfunctionIndicatorLampCmd 5080;
BA_ "SigType" SG_ 2566719486 OBDMalfunctionIndicatorLampCmd 5;
BA_ "SPN" SG_ 2566719486 EngRedStopLampCmd 5079;
BA_ "SigType" SG_ 2566719486 EngRedStopLampCmd 5;
BA_ "SPN" SG_ 2566719486 EngAmberWarningLampCmd 5078;
BA_ "SigType" SG_ 2566719486 EngAmberWarningLampCmd 5;
BA_ "SPN" SG_ 2566719486 EngProtectLampCmd 5077;
BA_ "SigType" SG_ 2566719486 EngProtectLampCmd 5;
BA_ "SPN" SG_ 2633832702 RolloverSensorType 4934;
BA_ "SPN" SG_ 2633832702 RearCollisionSensor4Type 4933;
BA_ "SPN" SG_ 2633832702 RearCollisionSensor3Type 4932;
BA_ "SPN" SG_ 2633832702 RearCollisionSensor2Type 4931;
BA_ "SPN" SG_ 2633832702 RearCollisionSensor1Type 4930;
BA_ "SPN" SG_ 2633832702 SideCollisionSensorRearRightType 4929;
BA_ "SPN" SG_ 2633832702 SdCllisionSensorMidRearRightType 4928;
BA_ "SPN" SG_ 2633832702 SdCllsionSensorMidFrontRightType 4927;
BA_ "SPN" SG_ 2633832702 SdeCollisionSensorFrontRightType 4926;
BA_ "SPN" SG_ 2633832702 SideCollisionSensorRearLeftType 4925;
BA_ "SPN" SG_ 2633832702 SdCollisionSensorMidRearLeftType 4924;
BA_ "SPN" SG_ 2633832702 SdCllisionSensorMidFrontLeftType 4923;
BA_ "SPN" SG_ 2633832702 SideCollisionSensorFrontLeftType 4922;
BA_ "SPN" SG_ 2633832702 FrontalCollisionSensor4Type 4921;
BA_ "SPN" SG_ 2633832702 FrontalCollisionSensor3Type 4920;
BA_ "SPN" SG_ 2633832702 FrontalCollisionSensor2Type 4919;
BA_ "SPN" SG_ 2633832702 FrontalCollisionSensor1Type 4918;
BA_ "SPN" SG_ 2163223550 CrashChecksum 4975;
BA_ "SigType" SG_ 2163223550 CrashChecksum 12;
BA_ "SPN" SG_ 2163223550 CrashCounter 4974;
BA_ "SigType" SG_ 2163223550 CrashCounter 11;
BA_ "SPN" SG_ 2163223550 CrashType 4973;
BA_ "SPN" SG_ 2566714878 EngChrgArClr2PrecoolerEfficiency 5288;
BA_ "SigType" SG_ 2566714878 EngChrgArClr2PrecoolerEfficiency 1;
BA_ "SPN" SG_ 2566714878 EngChrgArClr2PrecoolerOutletTemp 5287;
BA_ "SigType" SG_ 2566714878 EngChrgArClr2PrecoolerOutletTemp 1;
BA_ "SPN" SG_ 2566714878 EngChrgArClr2PrecoolerIntakeTemp 5286;
BA_ "SigType" SG_ 2566714878 EngChrgArClr2PrecoolerIntakeTemp 1;
BA_ "SPN" SG_ 2566714622 EngChargeAirCooler2Efficiency 5292;
BA_ "SigType" SG_ 2566714622 EngChargeAirCooler2Efficiency 1;
BA_ "SPN" SG_ 2566714622 EngChrgeAirCooler2AmbientAirTemp 5291;
BA_ "SigType" SG_ 2566714622 EngChrgeAirCooler2AmbientAirTemp 1;
BA_ "SPN" SG_ 2566714622 EngChargeAirCooler2OutletTemp 5290;
BA_ "SigType" SG_ 2566714622 EngChargeAirCooler2OutletTemp 1;
BA_ "SPN" SG_ 2566714622 EngChargeAirCooler2IntakeTemp 5289;
BA_ "SigType" SG_ 2566714622 EngChargeAirCooler2IntakeTemp 1;
BA_ "SPN" SG_ 2566715390 EngChrgArClr1PrecoolerEfficiency 5282;
BA_ "SigType" SG_ 2566715390 EngChrgArClr1PrecoolerEfficiency 1;
BA_ "SPN" SG_ 2566715390 EngChrgArClr1PrecoolerOutletTemp 5281;
BA_ "SigType" SG_ 2566715390 EngChrgArClr1PrecoolerOutletTemp 1;
BA_ "SPN" SG_ 2566715390 EngChrgArClr1PrecoolerIntakeTemp 5280;
BA_ "SigType" SG_ 2566715390 EngChrgArClr1PrecoolerIntakeTemp 1;
BA_ "SPN" SG_ 2566715134 EngChargeAirCooler1Efficiency 5285;
BA_ "SigType" SG_ 2566715134 EngChargeAirCooler1Efficiency 1;
BA_ "SPN" SG_ 2566715134 EngChrgeAirCooler1AmbientAirTemp 5284;
BA_ "SigType" SG_ 2566715134 EngChrgeAirCooler1AmbientAirTemp 1;
BA_ "SPN" SG_ 2566715134 EngChargeAirCooler1IntakeTemp 5283;
BA_ "SigType" SG_ 2566715134 EngChargeAirCooler1IntakeTemp 1;
BA_ "SPN" SG_ 2365400830 Joystick9Button9PressedStatus 4697;
BA_ "SigType" SG_ 2365400830 Joystick9Button9PressedStatus 4;
BA_ "SPN" SG_ 2365400830 Joystick9Button10PressedStatus 4696;
BA_ "SigType" SG_ 2365400830 Joystick9Button10PressedStatus 4;
BA_ "SPN" SG_ 2365400830 Joystick9Button11PressedStatus 4695;
BA_ "SigType" SG_ 2365400830 Joystick9Button11PressedStatus 4;
BA_ "SPN" SG_ 2365400830 Joystick9Button12PressedStatus 4694;
BA_ "SigType" SG_ 2365400830 Joystick9Button12PressedStatus 4;
BA_ "SPN" SG_ 2365400830 Joystick9Button5PressedStatus 4693;
BA_ "SigType" SG_ 2365400830 Joystick9Button5PressedStatus 4;
BA_ "SPN" SG_ 2365400830 Joystick9Button6PressedStatus 4692;
BA_ "SigType" SG_ 2365400830 Joystick9Button6PressedStatus 4;
BA_ "SPN" SG_ 2365400830 Joystick9Button7PressedStatus 4691;
BA_ "SigType" SG_ 2365400830 Joystick9Button7PressedStatus 4;
BA_ "SPN" SG_ 2365400830 Joystick9Button8PressedStatus 4690;
BA_ "SigType" SG_ 2365400830 Joystick9Button8PressedStatus 4;
BA_ "SPN" SG_ 2365400830 Joystick9Button1PressedStatus 4689;
BA_ "SigType" SG_ 2365400830 Joystick9Button1PressedStatus 4;
BA_ "SPN" SG_ 2365400830 Joystick9Button2PressedStatus 4688;
BA_ "SigType" SG_ 2365400830 Joystick9Button2PressedStatus 4;
BA_ "SPN" SG_ 2365400830 Joystick9Button3PressedStatus 4687;
BA_ "SigType" SG_ 2365400830 Joystick9Button3PressedStatus 4;
BA_ "SPN" SG_ 2365400830 Joystick9Button4PressedStatus 4686;
BA_ "SigType" SG_ 2365400830 Joystick9Button4PressedStatus 4;
BA_ "SPN" SG_ 2365400830 Joystick9XAxisDetentPosStatus 4685;
BA_ "SigType" SG_ 2365400830 Joystick9XAxisDetentPosStatus 4;
BA_ "SPN" SG_ 2365400830 Joystick9YAxisDetentPosStatus 4684;
BA_ "SigType" SG_ 2365400830 Joystick9YAxisDetentPosStatus 4;
BA_ "SPN" SG_ 2365400830 Joystick9YAxisPos 4683;
BA_ "SPN" SG_ 2365400830 Jystck9YAxsLvrFrwrdPstvPosStatus 4682;
BA_ "SigType" SG_ 2365400830 Jystck9YAxsLvrFrwrdPstvPosStatus 4;
BA_ "SPN" SG_ 2365400830 Jystck9YAxsLvrBckNgtivePosStatus 4681;
BA_ "SigType" SG_ 2365400830 Jystck9YAxsLvrBckNgtivePosStatus 4;
BA_ "SPN" SG_ 2365400830 Joystick9YAxisNeutralPosStatus 4680;
BA_ "SigType" SG_ 2365400830 Joystick9YAxisNeutralPosStatus 4;
BA_ "SPN" SG_ 2365400830 Joystick9XAxisPos 4679;
BA_ "SPN" SG_ 2365400830 Jystck9XAxsLvrRghtPstvePosStatus 4678;
BA_ "SigType" SG_ 2365400830 Jystck9XAxsLvrRghtPstvePosStatus 4;
BA_ "SPN" SG_ 2365400830 Jystck9XAxsLvrLftNgtivePosStatus 4677;
BA_ "SigType" SG_ 2365400830 Jystck9XAxsLvrLftNgtivePosStatus 4;
BA_ "SPN" SG_ 2365400830 Joystick9XAxisNeutralPosStatus 4676;
BA_ "SigType" SG_ 2365400830 Joystick9XAxisNeutralPosStatus 4;
BA_ "SPN" SG_ 2365401342 Joystick8Button9PressedStatus 4660;
BA_ "SigType" SG_ 2365401342 Joystick8Button9PressedStatus 4;
BA_ "SPN" SG_ 2365401342 Joystick8Button10PressedStatus 4659;
BA_ "SigType" SG_ 2365401342 Joystick8Button10PressedStatus 4;
BA_ "SPN" SG_ 2365401342 Joystick8Button11PressedStatus 4658;
BA_ "SigType" SG_ 2365401342 Joystick8Button11PressedStatus 4;
BA_ "SPN" SG_ 2365401342 Joystick8Button12PressedStatus 4657;
BA_ "SigType" SG_ 2365401342 Joystick8Button12PressedStatus 4;
BA_ "SPN" SG_ 2365401342 Joystick8Button5PressedStatus 4656;
BA_ "SigType" SG_ 2365401342 Joystick8Button5PressedStatus 4;
BA_ "SPN" SG_ 2365401342 Joystick8Button6PressedStatus 4655;
BA_ "SigType" SG_ 2365401342 Joystick8Button6PressedStatus 4;
BA_ "SPN" SG_ 2365401342 Joystick8Button7PressedStatus 4654;
BA_ "SigType" SG_ 2365401342 Joystick8Button7PressedStatus 4;
BA_ "SPN" SG_ 2365401342 Joystick8Button8PressedStatus 4653;
BA_ "SigType" SG_ 2365401342 Joystick8Button8PressedStatus 4;
BA_ "SPN" SG_ 2365401342 Joystick8Button1PressedStatus 4652;
BA_ "SigType" SG_ 2365401342 Joystick8Button1PressedStatus 4;
BA_ "SPN" SG_ 2365401342 Joystick8Button2PressedStatus 4651;
BA_ "SigType" SG_ 2365401342 Joystick8Button2PressedStatus 4;
BA_ "SPN" SG_ 2365401342 Joystick8Button3PressedStatus 4650;
BA_ "SigType" SG_ 2365401342 Joystick8Button3PressedStatus 4;
BA_ "SPN" SG_ 2365401342 Joystick8Button4PressedStatus 4649;
BA_ "SigType" SG_ 2365401342 Joystick8Button4PressedStatus 4;
BA_ "SPN" SG_ 2365401342 Joystick8XAxisDetentPosStatus 4648;
BA_ "SigType" SG_ 2365401342 Joystick8XAxisDetentPosStatus 4;
BA_ "SPN" SG_ 2365401342 Joystick8YAxisDetentPosStatus 4647;
BA_ "SigType" SG_ 2365401342 Joystick8YAxisDetentPosStatus 4;
BA_ "SPN" SG_ 2365401342 Joystick8YAxisPos 4646;
BA_ "SPN" SG_ 2365401342 Jystck8YAxsLvrFrwrdPstvPosStatus 4645;
BA_ "SigType" SG_ 2365401342 Jystck8YAxsLvrFrwrdPstvPosStatus 4;
BA_ "SPN" SG_ 2365401342 Jystck8YAxsLvrBckNgtivePosStatus 4644;
BA_ "SigType" SG_ 2365401342 Jystck8YAxsLvrBckNgtivePosStatus 4;
BA_ "SPN" SG_ 2365401342 Joystick8YAxisNeutralPosStatus 4643;
BA_ "SigType" SG_ 2365401342 Joystick8YAxisNeutralPosStatus 4;
BA_ "SPN" SG_ 2365401342 Joystick8XAxisPos 4642;
BA_ "SPN" SG_ 2365401342 Jystck8XAxsLvrRghtPstvePosStatus 4641;
BA_ "SigType" SG_ 2365401342 Jystck8XAxsLvrRghtPstvePosStatus 4;
BA_ "SPN" SG_ 2365401342 Jystck8XAxsLvrLftNgtivePosStatus 4640;
BA_ "SigType" SG_ 2365401342 Jystck8XAxsLvrLftNgtivePosStatus 4;
BA_ "SPN" SG_ 2365401342 Joystick8XAxisNeutralPosStatus 4639;
BA_ "SigType" SG_ 2365401342 Joystick8XAxisNeutralPosStatus 4;
BA_ "SPN" SG_ 2365401854 Joystick7Button9PressedStatus 4623;
BA_ "SigType" SG_ 2365401854 Joystick7Button9PressedStatus 4;
BA_ "SPN" SG_ 2365401854 Joystick7Button10PressedStatus 4622;
BA_ "SigType" SG_ 2365401854 Joystick7Button10PressedStatus 4;
BA_ "SPN" SG_ 2365401854 Joystick7Button11PressedStatus 4621;
BA_ "SigType" SG_ 2365401854 Joystick7Button11PressedStatus 4;
BA_ "SPN" SG_ 2365401854 Joystick7Button12PressedStatus 4620;
BA_ "SigType" SG_ 2365401854 Joystick7Button12PressedStatus 4;
BA_ "SPN" SG_ 2365401854 Joystick7Button5PressedStatus 4619;
BA_ "SigType" SG_ 2365401854 Joystick7Button5PressedStatus 4;
BA_ "SPN" SG_ 2365401854 Joystick7Button6PressedStatus 4618;
BA_ "SigType" SG_ 2365401854 Joystick7Button6PressedStatus 4;
BA_ "SPN" SG_ 2365401854 Joystick7Button7PressedStatus 4617;
BA_ "SigType" SG_ 2365401854 Joystick7Button7PressedStatus 4;
BA_ "SPN" SG_ 2365401854 Joystick7Button8PressedStatus 4616;
BA_ "SigType" SG_ 2365401854 Joystick7Button8PressedStatus 4;
BA_ "SPN" SG_ 2365401854 Joystick7Button1PressedStatus 4615;
BA_ "SigType" SG_ 2365401854 Joystick7Button1PressedStatus 4;
BA_ "SPN" SG_ 2365401854 Joystick7Button2PressedStatus 4614;
BA_ "SigType" SG_ 2365401854 Joystick7Button2PressedStatus 4;
BA_ "SPN" SG_ 2365401854 Joystick7Button3PressedStatus 4613;
BA_ "SigType" SG_ 2365401854 Joystick7Button3PressedStatus 4;
BA_ "SPN" SG_ 2365401854 Joystick7Button4PressedStatus 4612;
BA_ "SigType" SG_ 2365401854 Joystick7Button4PressedStatus 4;
BA_ "SPN" SG_ 2365401854 Joystick7XAxisDetentPosStatus 4611;
BA_ "SigType" SG_ 2365401854 Joystick7XAxisDetentPosStatus 4;
BA_ "SPN" SG_ 2365401854 Joystick7YAxisDetentPosStatus 4610;
BA_ "SigType" SG_ 2365401854 Joystick7YAxisDetentPosStatus 4;
BA_ "SPN" SG_ 2365401854 Joystick7YAxisPos 4609;
BA_ "SPN" SG_ 2365401854 Jystck7YAxsLvrFrwrdPstvPosStatus 4608;
BA_ "SigType" SG_ 2365401854 Jystck7YAxsLvrFrwrdPstvPosStatus 4;
BA_ "SPN" SG_ 2365401854 Jystck7YAxsLvrBckNgtivePosStatus 4607;
BA_ "SigType" SG_ 2365401854 Jystck7YAxsLvrBckNgtivePosStatus 4;
BA_ "SPN" SG_ 2365401854 Joystick7YAxisNeutralPosStatus 4606;
BA_ "SigType" SG_ 2365401854 Joystick7YAxisNeutralPosStatus 4;
BA_ "SPN" SG_ 2365401854 Joystick7XAxisPos 4605;
BA_ "SPN" SG_ 2365401854 Jystck7XAxsLvrRghtPstvePosStatus 4604;
BA_ "SigType" SG_ 2365401854 Jystck7XAxsLvrRghtPstvePosStatus 4;
BA_ "SPN" SG_ 2365401854 Jystck7XAxsLvrLftNgtivePosStatus 4603;
BA_ "SigType" SG_ 2365401854 Jystck7XAxsLvrLftNgtivePosStatus 4;
BA_ "SPN" SG_ 2365401854 Joystick7XAxisNeutralPosStatus 4602;
BA_ "SigType" SG_ 2365401854 Joystick7XAxisNeutralPosStatus 4;
BA_ "SPN" SG_ 2365402366 Joystick6Button9PressedStatus 4586;
BA_ "SigType" SG_ 2365402366 Joystick6Button9PressedStatus 4;
BA_ "SPN" SG_ 2365402366 Joystick6Button10PressedStatus 4585;
BA_ "SigType" SG_ 2365402366 Joystick6Button10PressedStatus 4;
BA_ "SPN" SG_ 2365402366 Joystick6Button11PressedStatus 4584;
BA_ "SigType" SG_ 2365402366 Joystick6Button11PressedStatus 4;
BA_ "SPN" SG_ 2365402366 Joystick6Button12PressedStatus 4583;
BA_ "SigType" SG_ 2365402366 Joystick6Button12PressedStatus 4;
BA_ "SPN" SG_ 2365402366 Joystick6Button5PressedStatus 4582;
BA_ "SigType" SG_ 2365402366 Joystick6Button5PressedStatus 4;
BA_ "SPN" SG_ 2365402366 Joystick6Button6PressedStatus 4581;
BA_ "SigType" SG_ 2365402366 Joystick6Button6PressedStatus 4;
BA_ "SPN" SG_ 2365402366 Joystick6Button7PressedStatus 4580;
BA_ "SigType" SG_ 2365402366 Joystick6Button7PressedStatus 4;
BA_ "SPN" SG_ 2365402366 Joystick6Button8PressedStatus 4579;
BA_ "SigType" SG_ 2365402366 Joystick6Button8PressedStatus 4;
BA_ "SPN" SG_ 2365402366 Joystick6Button1PressedStatus 4578;
BA_ "SigType" SG_ 2365402366 Joystick6Button1PressedStatus 4;
BA_ "SPN" SG_ 2365402366 Joystick6Button2PressedStatus 4577;
BA_ "SigType" SG_ 2365402366 Joystick6Button2PressedStatus 4;
BA_ "SPN" SG_ 2365402366 Joystick6Button3PressedStatus 4576;
BA_ "SigType" SG_ 2365402366 Joystick6Button3PressedStatus 4;
BA_ "SPN" SG_ 2365402366 Joystick6Button4PressedStatus 4575;
BA_ "SigType" SG_ 2365402366 Joystick6Button4PressedStatus 4;
BA_ "SPN" SG_ 2365402366 Joystick6XAxisDetentPosStatus 4574;
BA_ "SigType" SG_ 2365402366 Joystick6XAxisDetentPosStatus 4;
BA_ "SPN" SG_ 2365402366 Joystick6YAxisDetentPosStatus 4573;
BA_ "SigType" SG_ 2365402366 Joystick6YAxisDetentPosStatus 4;
BA_ "SPN" SG_ 2365402366 Joystick6YAxisPos 4572;
BA_ "SPN" SG_ 2365402366 Jystck6YAxsLvrFrwrdPstvPosStatus 4571;
BA_ "SigType" SG_ 2365402366 Jystck6YAxsLvrFrwrdPstvPosStatus 4;
BA_ "SPN" SG_ 2365402366 Jystck6YAxsLvrBckNgtivePosStatus 4570;
BA_ "SigType" SG_ 2365402366 Jystck6YAxsLvrBckNgtivePosStatus 4;
BA_ "SPN" SG_ 2365402366 Joystick6YAxisNeutralPosStatus 4569;
BA_ "SigType" SG_ 2365402366 Joystick6YAxisNeutralPosStatus 4;
BA_ "SPN" SG_ 2365402366 Joystick6XAxisPos 4568;
BA_ "SPN" SG_ 2365402366 Jystck6XAxsLvrRghtPstvePosStatus 4567;
BA_ "SigType" SG_ 2365402366 Jystck6XAxsLvrRghtPstvePosStatus 4;
BA_ "SPN" SG_ 2365402366 Jystck6XAxsLvrLftNgtivePosStatus 4566;
BA_ "SigType" SG_ 2365402366 Jystck6XAxsLvrLftNgtivePosStatus 4;
BA_ "SPN" SG_ 2365402366 Joystick6XAxisNeutralPosStatus 4565;
BA_ "SigType" SG_ 2365402366 Joystick6XAxisNeutralPosStatus 4;
BA_ "SPN" SG_ 2365402878 Joystick5Button9PressedStatus 4549;
BA_ "SigType" SG_ 2365402878 Joystick5Button9PressedStatus 4;
BA_ "SPN" SG_ 2365402878 Joystick5Button10PressedStatus 4548;
BA_ "SigType" SG_ 2365402878 Joystick5Button10PressedStatus 4;
BA_ "SPN" SG_ 2365402878 Joystick5Button11PressedStatus 4547;
BA_ "SigType" SG_ 2365402878 Joystick5Button11PressedStatus 4;
BA_ "SPN" SG_ 2365402878 Joystick5Button12PressedStatus 4546;
BA_ "SigType" SG_ 2365402878 Joystick5Button12PressedStatus 4;
BA_ "SPN" SG_ 2365402878 Joystick5Button5PressedStatus 4545;
BA_ "SigType" SG_ 2365402878 Joystick5Button5PressedStatus 4;
BA_ "SPN" SG_ 2365402878 Joystick5Button6PressedStatus 4544;
BA_ "SigType" SG_ 2365402878 Joystick5Button6PressedStatus 4;
BA_ "SPN" SG_ 2365402878 Joystick5Button7PressedStatus 4543;
BA_ "SigType" SG_ 2365402878 Joystick5Button7PressedStatus 4;
BA_ "SPN" SG_ 2365402878 Joystick5Button8PressedStatus 4542;
BA_ "SigType" SG_ 2365402878 Joystick5Button8PressedStatus 4;
BA_ "SPN" SG_ 2365402878 Joystick5Button1PressedStatus 4541;
BA_ "SigType" SG_ 2365402878 Joystick5Button1PressedStatus 4;
BA_ "SPN" SG_ 2365402878 Joystick5Button2PressedStatus 4540;
BA_ "SigType" SG_ 2365402878 Joystick5Button2PressedStatus 4;
BA_ "SPN" SG_ 2365402878 Joystick5Button3PressedStatus 4539;
BA_ "SigType" SG_ 2365402878 Joystick5Button3PressedStatus 4;
BA_ "SPN" SG_ 2365402878 Joystick5Button4PressedStatus 4538;
BA_ "SigType" SG_ 2365402878 Joystick5Button4PressedStatus 4;
BA_ "SPN" SG_ 2365402878 Joystick5XAxisDetentPosStatus 4537;
BA_ "SigType" SG_ 2365402878 Joystick5XAxisDetentPosStatus 4;
BA_ "SPN" SG_ 2365402878 Joystick5YAxisDetentPosStatus 4536;
BA_ "SigType" SG_ 2365402878 Joystick5YAxisDetentPosStatus 4;
BA_ "SPN" SG_ 2365402878 Joystick5YAxisPos 4535;
BA_ "SPN" SG_ 2365402878 Jystck5YAxsLvrFrwrdPstvPosStatus 4534;
BA_ "SigType" SG_ 2365402878 Jystck5YAxsLvrFrwrdPstvPosStatus 4;
BA_ "SPN" SG_ 2365402878 Jystck5YAxsLvrBckNgtivePosStatus 4533;
BA_ "SigType" SG_ 2365402878 Jystck5YAxsLvrBckNgtivePosStatus 4;
BA_ "SPN" SG_ 2365402878 Joystick5YAxisNeutralPosStatus 4532;
BA_ "SigType" SG_ 2365402878 Joystick5YAxisNeutralPosStatus 4;
BA_ "SPN" SG_ 2365402878 Joystick5XAxisPos 4531;
BA_ "SPN" SG_ 2365402878 Jystck5XAxsLvrRghtPstvePosStatus 4530;
BA_ "SigType" SG_ 2365402878 Jystck5XAxsLvrRghtPstvePosStatus 4;
BA_ "SPN" SG_ 2365402878 Jystck5XAxsLvrLftNgtivePosStatus 4529;
BA_ "SigType" SG_ 2365402878 Jystck5XAxsLvrLftNgtivePosStatus 4;
BA_ "SPN" SG_ 2365402878 Joystick5XAxisNeutralPosStatus 4528;
BA_ "SigType" SG_ 2365402878 Joystick5XAxisNeutralPosStatus 4;
BA_ "SPN" SG_ 2365403390 Joystick4Button9PressedStatus 4512;
BA_ "SigType" SG_ 2365403390 Joystick4Button9PressedStatus 4;
BA_ "SPN" SG_ 2365403390 Joystick4Button10PressedStatus 4511;
BA_ "SigType" SG_ 2365403390 Joystick4Button10PressedStatus 4;
BA_ "SPN" SG_ 2365403390 Joystick4Button11PressedStatus 4510;
BA_ "SigType" SG_ 2365403390 Joystick4Button11PressedStatus 4;
BA_ "SPN" SG_ 2365403390 Joystick4Button12PressedStatus 4509;
BA_ "SigType" SG_ 2365403390 Joystick4Button12PressedStatus 4;
BA_ "SPN" SG_ 2365403390 Joystick4Button5PressedStatus 4508;
BA_ "SigType" SG_ 2365403390 Joystick4Button5PressedStatus 4;
BA_ "SPN" SG_ 2365403390 Joystick4Button6PressedStatus 4507;
BA_ "SigType" SG_ 2365403390 Joystick4Button6PressedStatus 4;
BA_ "SPN" SG_ 2365403390 Joystick4Button7PressedStatus 4506;
BA_ "SigType" SG_ 2365403390 Joystick4Button7PressedStatus 4;
BA_ "SPN" SG_ 2365403390 Joystick4Button8PressedStatus 4505;
BA_ "SigType" SG_ 2365403390 Joystick4Button8PressedStatus 4;
BA_ "SPN" SG_ 2365403390 Joystick4Button1PressedStatus 4504;
BA_ "SigType" SG_ 2365403390 Joystick4Button1PressedStatus 4;
BA_ "SPN" SG_ 2365403390 Joystick4Button2PressedStatus 4503;
BA_ "SigType" SG_ 2365403390 Joystick4Button2PressedStatus 4;
BA_ "SPN" SG_ 2365403390 Joystick4Button3PressedStatus 4502;
BA_ "SigType" SG_ 2365403390 Joystick4Button3PressedStatus 4;
BA_ "SPN" SG_ 2365403390 Joystick4Button4PressedStatus 4501;
BA_ "SigType" SG_ 2365403390 Joystick4Button4PressedStatus 4;
BA_ "SPN" SG_ 2365403390 Joystick4XAxisDetentPosStatus 4500;
BA_ "SigType" SG_ 2365403390 Joystick4XAxisDetentPosStatus 4;
BA_ "SPN" SG_ 2365403390 Joystick4YAxisDetentPosStatus 4499;
BA_ "SigType" SG_ 2365403390 Joystick4YAxisDetentPosStatus 4;
BA_ "SPN" SG_ 2365403390 Joystick4YAxisPos 4498;
BA_ "SPN" SG_ 2365403390 Jystck4YAxsLvrFrwrdPstvPosStatus 4497;
BA_ "SigType" SG_ 2365403390 Jystck4YAxsLvrFrwrdPstvPosStatus 4;
BA_ "SPN" SG_ 2365403390 Jystck4YAxsLvrBckNgtivePosStatus 4496;
BA_ "SigType" SG_ 2365403390 Jystck4YAxsLvrBckNgtivePosStatus 4;
BA_ "SPN" SG_ 2365403390 Joystick4YAxisNeutralPosStatus 4495;
BA_ "SigType" SG_ 2365403390 Joystick4YAxisNeutralPosStatus 4;
BA_ "SPN" SG_ 2365403390 Joystick4XAxisPos 4494;
BA_ "SPN" SG_ 2365403390 Jystck4XAxsLvrRghtPstvePosStatus 4493;
BA_ "SigType" SG_ 2365403390 Jystck4XAxsLvrRghtPstvePosStatus 4;
BA_ "SPN" SG_ 2365403390 Jystck4XAxsLvrLftNgtivePosStatus 4492;
BA_ "SigType" SG_ 2365403390 Jystck4XAxsLvrLftNgtivePosStatus 4;
BA_ "SPN" SG_ 2365403390 Joystick4XAxisNeutralPosStatus 4491;
BA_ "SigType" SG_ 2365403390 Joystick4XAxisNeutralPosStatus 4;
BA_ "SPN" SG_ 2365400318 Joystick10Button9PressedStatus 4734;
BA_ "SigType" SG_ 2365400318 Joystick10Button9PressedStatus 4;
BA_ "SPN" SG_ 2365400318 Joystick10Button10PressedStatus 4733;
BA_ "SigType" SG_ 2365400318 Joystick10Button10PressedStatus 4;
BA_ "SPN" SG_ 2365400318 Joystick10Button11PressedStatus 4732;
BA_ "SigType" SG_ 2365400318 Joystick10Button11PressedStatus 4;
BA_ "SPN" SG_ 2365400318 Joystick10Button12PressedStatus 4731;
BA_ "SigType" SG_ 2365400318 Joystick10Button12PressedStatus 4;
BA_ "SPN" SG_ 2365400318 Joystick10Button5PressedStatus 4730;
BA_ "SigType" SG_ 2365400318 Joystick10Button5PressedStatus 4;
BA_ "SPN" SG_ 2365400318 Joystick10Button6PressedStatus 4729;
BA_ "SigType" SG_ 2365400318 Joystick10Button6PressedStatus 4;
BA_ "SPN" SG_ 2365400318 Joystick10Button7PressedStatus 4728;
BA_ "SigType" SG_ 2365400318 Joystick10Button7PressedStatus 4;
BA_ "SPN" SG_ 2365400318 Joystick10Button8PressedStatus 4727;
BA_ "SigType" SG_ 2365400318 Joystick10Button8PressedStatus 4;
BA_ "SPN" SG_ 2365400318 Joystick10Button1PressedStatus 4726;
BA_ "SigType" SG_ 2365400318 Joystick10Button1PressedStatus 4;
BA_ "SPN" SG_ 2365400318 Joystick10Button2PressedStatus 4725;
BA_ "SigType" SG_ 2365400318 Joystick10Button2PressedStatus 4;
BA_ "SPN" SG_ 2365400318 Joystick10Button3PressedStatus 4724;
BA_ "SigType" SG_ 2365400318 Joystick10Button3PressedStatus 4;
BA_ "SPN" SG_ 2365400318 Joystick10Button4PressedStatus 4723;
BA_ "SigType" SG_ 2365400318 Joystick10Button4PressedStatus 4;
BA_ "SPN" SG_ 2365400318 Joystick10XAxisDetentPosStatus 4722;
BA_ "SigType" SG_ 2365400318 Joystick10XAxisDetentPosStatus 4;
BA_ "SPN" SG_ 2365400318 Joystick10YAxisDetentPosStatus 4721;
BA_ "SigType" SG_ 2365400318 Joystick10YAxisDetentPosStatus 4;
BA_ "SPN" SG_ 2365400318 Joystick10YAxisPos 4720;
BA_ "SPN" SG_ 2365400318 Jystck10YAxsLvrFrwrdPstvPsStatus 4719;
BA_ "SigType" SG_ 2365400318 Jystck10YAxsLvrFrwrdPstvPsStatus 4;
BA_ "SPN" SG_ 2365400318 Jystck10YAxsLvrBckNgtvePosStatus 4718;
BA_ "SigType" SG_ 2365400318 Jystck10YAxsLvrBckNgtvePosStatus 4;
BA_ "SPN" SG_ 2365400318 Joystick10YAxisNeutralPosStatus 4717;
BA_ "SigType" SG_ 2365400318 Joystick10YAxisNeutralPosStatus 4;
BA_ "SPN" SG_ 2365400318 Joystick10XAxisPos 4716;
BA_ "SPN" SG_ 2365400318 Jystck10XAxsLvrRghtPstvPosStatus 4715;
BA_ "SigType" SG_ 2365400318 Jystck10XAxsLvrRghtPstvPosStatus 4;
BA_ "SPN" SG_ 2365400318 Jystck10XAxsLvrLftNgtvePosStatus 4714;
BA_ "SigType" SG_ 2365400318 Jystck10XAxsLvrLftNgtvePosStatus 4;
BA_ "SPN" SG_ 2365400318 Joystick10XAxisNeutralPosStatus 4713;
BA_ "SigType" SG_ 2365400318 Joystick10XAxisNeutralPosStatus 4;
BA_ "SPN" SG_ 2499614718 PssngrArbgDctivationSwitchStatus 4962;
BA_ "SigType" SG_ 2499614718 PssngrArbgDctivationSwitchStatus 5;
BA_ "SPN" SG_ 2499614718 Beltlock10Status 4961;
BA_ "SigType" SG_ 2499614718 Beltlock10Status 5;
BA_ "SPN" SG_ 2499614718 Beltlock9Status 4960;
BA_ "SigType" SG_ 2499614718 Beltlock9Status 5;
BA_ "SPN" SG_ 2499614718 Beltlock8Status 4959;
BA_ "SigType" SG_ 2499614718 Beltlock8Status 5;
BA_ "SPN" SG_ 2499614718 Beltlock7Status 4958;
BA_ "SigType" SG_ 2499614718 Beltlock7Status 5;
BA_ "SPN" SG_ 2499614718 Beltlock6Status 4957;
BA_ "SigType" SG_ 2499614718 Beltlock6Status 5;
BA_ "SPN" SG_ 2499614718 Beltlock5Status 4956;
BA_ "SigType" SG_ 2499614718 Beltlock5Status 5;
BA_ "SPN" SG_ 2499614718 Beltlock4Status 4955;
BA_ "SigType" SG_ 2499614718 Beltlock4Status 5;
BA_ "SPN" SG_ 2499614718 Beltlock3Status 4954;
BA_ "SigType" SG_ 2499614718 Beltlock3Status 5;
BA_ "SPN" SG_ 2499614718 PassengerBeltlockStatus 4953;
BA_ "SigType" SG_ 2499614718 PassengerBeltlockStatus 5;
BA_ "SPN" SG_ 2499614718 DriverBeltlockStatus 4952;
BA_ "SigType" SG_ 2499614718 DriverBeltlockStatus 5;
BA_ "SPN" SG_ 2566722814 BatteryCharger2OutputCurrent 4997;
BA_ "SigType" SG_ 2566722814 BatteryCharger2OutputCurrent 1;
BA_ "SPN" SG_ 2566722814 BatteryCharger2OutputVoltage 4996;
BA_ "SigType" SG_ 2566722814 BatteryCharger2OutputVoltage 1;
BA_ "SPN" SG_ 2566722814 BatteryCharger2PowerLineState 4995;
BA_ "SigType" SG_ 2566722814 BatteryCharger2PowerLineState 4;
BA_ "SPN" SG_ 2566722814 BatteryCharger2State 4994;
BA_ "SPN" SG_ 2566723070 BatteryCharger1OutputCurrent 4993;
BA_ "SigType" SG_ 2566723070 BatteryCharger1OutputCurrent 1;
BA_ "SPN" SG_ 2566723070 BatteryCharger1OutputVoltage 4992;
BA_ "SigType" SG_ 2566723070 BatteryCharger1OutputVoltage 1;
BA_ "SPN" SG_ 2566723070 BatteryCharger1PowerLineState 4991;
BA_ "SigType" SG_ 2566723070 BatteryCharger1PowerLineState 4;
BA_ "SPN" SG_ 2566723070 BatteryCharger1State 4990;
BA_ "SPN" SG_ 2566725118 TwoTWCDiffTemp 4780;
BA_ "SigType" SG_ 2566725118 TwoTWCDiffTemp 1;
BA_ "SPN" SG_ 2566725118 OneTWCDiffTemp 4779;
BA_ "SigType" SG_ 2566725118 OneTWCDiffTemp 1;
BA_ "SPN" SG_ 2566725374 TwoGOCDiffTemp 4778;
BA_ "SigType" SG_ 2566725374 TwoGOCDiffTemp 1;
BA_ "SPN" SG_ 2566725374 OneGOCDiffTemp 4777;
BA_ "SigType" SG_ 2566725374 OneGOCDiffTemp 1;
BA_ "SPN" SG_ 2566712830 OutTemp 5316;
BA_ "SigType" SG_ 2566712830 OutTemp 1;
BA_ "SPN" SG_ 2566712830 InTemp 5315;
BA_ "SigType" SG_ 2566712830 InTemp 1;
BA_ "SPN" SG_ 2566735358 DiffPressPreliminaryFMI 4300;
BA_ "SPN" SG_ 2566735358 OutTempPreliminaryFMI 4299;
BA_ "SPN" SG_ 2566735358 InTempPreliminaryFMI 4298;
BA_ "SPN" SG_ 2566735358 DiffPress 4297;
BA_ "SigType" SG_ 2566735358 DiffPress 1;
BA_ "SPN" SG_ 2566735358 OutTemp 4296;
BA_ "SigType" SG_ 2566735358 OutTemp 1;
BA_ "SPN" SG_ 2566735358 InTemp 4295;
BA_ "SigType" SG_ 2566735358 InTemp 1;
VAL_ 2566768382 EngCldStrtFlIgniterRelayFeedback 0 "Off" 1 "On" 2 "Error" 3 "Not available";
VAL_ 2566768382 EngColdStartFuelIgniterRelay 0 "Off" 1 "On" 2 "Reserved" 3 "Don't care/take no action";
VAL_ 2566768382 EngStartEnableDevice2Config 0 "no start enable device 2 installed" 1 "glow plugs installed" 2 "fuelled start installed" 3 "ether injection installed" 4 "electric intake air heater installed" 15 "not available";
VAL_ 2566768382 EngStartEnableDevice1Config 0 "no start enable device 1 installed" 1 "glow plugs installed" 2 "fuelled start installed" 3 "ether injection installed" 4 "electric intake air heater installed" 15 "not available";
VAL_ 2566768382 EngStartEnableDevice2 0 "start enable OFF" 1 "start enable ON" 2 "reserved" 3 "not available";
VAL_ 2566768382 EngStartEnableDevice1 0 "start enable OFF" 1 "start enable ON" 2 "reserved" 3 "not available";
VAL_ 2566771966 VehTrailerStatus 0 "Trailer is not detected" 1 "Trailer is detected" 2 "Error" 3 "Not available";
VAL_ 2566771966 TransOilLevelRq 0 "No transmission oil level reading desired" 1 "Transmission oil level reading desired" 2 "Reserved" 3 "Don't care / take no action";
VAL_ 2566771966 FifthWheelReleaseCtrl 0 "Coupler Locked" 1 "Coupler Unlocked" 2 "Error" 3 "Not Available";
VAL_ 2566771966 FfthWhlRleaseCtrlSecurityLockout 0 "Fifth wheel release Disabled" 1 "Fifth wheel release Enabled" 2 "Error   " 3 "Not Available";
VAL_ 2566771966 TransferCaseSelectorSwitch 0 "2 wheel high Normal or On Highway Range" 1 "4 wheel high Normal or On Highway Range" 2 "Neutral" 3 "2 wheel low or Off Highway Range" 4 "4 wheel low or Off Highway Range" 5 "Reserved for SAE assignment" 6 "Error indicator" 7 "Not available";
VAL_ 2564882174 ReqCabZoneHeating_1686 0 "Do not heat cab engine zone" 1 "Heat cab zone" 2 "Reserved" 3 "Don't care/take no action";
VAL_ 2564882174 ReqEngZoneHeating_1685 0 "Do not heat engine zone" 1 "Heat engine zone" 2 "Reserved" 3 "Don't care/take no action";
VAL_ 2564882174 AuxHeaterModeReq_1683 0 "De-activate auxiliary heater" 1 "Off due to ADR per European Regulations for Transport of hazardous materials" 2 "Economy mode" 3 "Normal mode" 4 "Heater pump up-keep" 14 "Reserved" 15 "Don't care/take no action";
VAL_ 2564882174 EngAutomaticStartEnableSw_1656 0 "Switch in the off state" 1 "Switch in the on state" 2 "Error" 3 "Not available";
VAL_ 2564882174 AtuomaticGearShiftingEnSw_1666 0 "Automated Gear Shifting is disabled" 1 "Automated Gear Shifting is enabled" 2 "Error" 3 "Not available";
VAL_ 2564882174 AFTRegenForceSw_3696 0 "not active " 1 "active " 2 "error " 3 "not available ";
VAL_ 2564882174 AFTRegenInhSw_3695 0 "not active " 1 "active " 2 "error " 3 "not available ";
VAL_ 2564882174 VehLmtngSpdGovrEnSw_1653 0 "Switch disabled" 1 "Switched enabled" 2 "Error" 3 "Not available";
VAL_ 2564882174 VehLmtngSpdGvrnrIncrementSw_1654 0 "Switch in the off state" 1 "Switch in the on state" 2 "Error" 3 "Not available";
VAL_ 2564882174 VehLmtngSpdGvrnrDecrementSw_1655 0 "Switch in the off state" 1 "Switch in the on state" 2 "Error" 3 "Not available";
VAL_ 2564882174 ParkBrakeCmd_5630 0 "Park Brake apply not requested" 1 "Park Brake apply requested" 2 "SAE Reserved  " 3 "Don't care/Take no action";
VAL_ 2564882174 SeatBeltSwitch_1856 0 "NOT Buckled" 1 "OK" 2 "Error" 3 "Not Available";
VAL_ 2564882174 OperatorSeatDirSw_1714 0 "Operator seat not facing forward" 1 "Operator seat is facing forward" 2 "Error" 3 "Not Available";
VAL_ 2564882174 BatteryMainSwitchHoldRq_1682 0 "Release Battery Main Switch" 1 "Hold Battery Main Switch" 2 "undefined" 3 "Don't care/take no action";
VAL_ 2564882174 AuxHeaterCoolantPumpRq_1684 0 "Deactivate water pump" 1 "Activate water pump" 2 "Reserved" 3 "Don't care/take no action";
VAL_ 2566844926 EngShutdownOverrideSwitch 0 "Off" 1 "On" 2 "Error" 3 "Not available";
VAL_ 2566844926 EngTestModeSwitch 0 "Off" 1 "On" 2 "Error" 3 "Not available";
VAL_ 2566844926 EngIdleDecrementSwitch 0 "Off" 1 "On" 2 "Error" 3 "Not available";
VAL_ 2566844926 EngIdleIncrementSwitch 0 "Off" 1 "On" 2 "Error" 3 "Not available";
VAL_ 2566844926 CruiseCtrlStates 0 "Off/Disabled" 1 "Hold" 2 "Accelerate" 3 "Decelerate" 4 "Resume" 5 "Set" 6 "Accelerator Override" 7 "Not available";
VAL_ 2566844926 PTOGovernorState 0 "Off/Disabled" 1 "Hold" 2 "Remote Hold" 3 "Standby" 4 "Remote Standby" 5 "Set" 6 "Decelerate/Coast" 7 "Resume" 8 "Accelerate" 9 "Accelerator Override" 10 "Preprogrammed set speed 1" 11 "Preprogrammed set speed 2" 12 "Preprogrammed set speed 3" 13 "Preprogrammed set speed 4" 14 "Preprogrammed set speed 5" 15 "Preprogrammed set speed 6" 16 "Preprogrammed set speed 7" 17 "Preprogrammed set speed 8" 18 "PTO set speed memory 1" 19 "PTO set speed memory 2" 31 "Not available";
VAL_ 2566844926 CruiseCtrlAccelerateSwitch 0 "Cruise control activator not in the position “accelerate”" 1 "Cruise control activator in position “accelerate”" 2 "Error" 3 "Not available";
VAL_ 2566844926 CruiseCtrlResumeSwitch 0 "Cruise control activator not in the position “resume”" 1 "Cruise control activator in position “resume”" 2 "Error" 3 "Not available";
VAL_ 2566844926 CruiseCtrlCoastSwitch 0 "Cruise control activator not in the position “coast”" 1 "Cruise control activator in position “coast”" 2 "Error" 3 "Not available";
VAL_ 2566844926 CruiseCtrlSetSwitch 0 "Cruise control activator not in the position “set”" 1 "Cruise control activator in position “set”" 2 "Error" 3 "Not available";
VAL_ 2566844926 ClutchSwitch 0 "Clutch pedal released" 1 "Clutch pedal depressed" 2 "Error" 3 "Not available";
VAL_ 2566844926 BrakeSwitch 0 "Brake pedal released" 1 "Brake pedal depressed" 2 "Error" 3 "Not Available";
VAL_ 2566844926 CruiseCtrlEnableSwitch 0 "Cruise control disabled" 1 "Cruise control enabled" 2 "Error" 3 "Not available";
VAL_ 2566844926 CruiseCtrlActive 0 "Cruise control switched off" 1 "Cruise control switched on" 2 "Error" 3 "Not available";
VAL_ 2566844926 ParkBrakeReleaseInhibitRq 0 "Park Brake Release Inhibit not requested" 1 "Park Brake Release Inhibit requested" 2 "SAE reserved" 3 "Unavailable";
VAL_ 2566844926 CruiseCtrlPauseSwitch 0 "- Off" 1 "- On" 2 "- Error Indicator" 3 "-Take No Action";
VAL_ 2566844926 ParkingBrakeSwitch 0 "Parking brake not set" 1 "Parking brake set" 2 "Error" 3 "Not available";
VAL_ 2566844926 TwoSpeedAxleSwitch 0 "Low speed range" 1 "High speed range" 2 "Error" 3 "Not available";
VAL_ 2566719486 VhclAccelerationRateLimitLampCmd 0 "Lamp Off" 1 "Lamp On" 2 "Reserved" 3 "Not available";
VAL_ 2566719486 EngSpeedVeryHighLampCmd 0 "Lamp Off" 1 "Lamp On" 2 "Reserved" 3 "Not available";
VAL_ 2566719486 EngSpeedHighLampCmd 0 "Lamp Off" 1 "Lamp On" 2 "Reserved" 3 "Not available";
VAL_ 2566719486 EngCtrlModule3ReadyForUseLampCmd 0 "Lamp Off" 1 "Lamp On" 2 "Reserved" 3 "Not available";
VAL_ 2566719486 EngCtrlModule2ReadyForUseLampCmd 0 "Lamp Off" 1 "Lamp On" 2 "Reserved" 3 "Not available";
VAL_ 2566719486 EngCtrlModule1ReadyForUseLampCmd 0 "Lamp Off" 1 "Lamp On" 2 "Reserved" 3 "Not available";
VAL_ 2566719486 EngFuelFilterRestrictedLampCmd 0 "Lamp Off" 1 "Lamp On" 2 "Reserved" 3 "Not available";
VAL_ 2566719486 EngAirFilterRestrictionLampCmd 0 "Lamp Off" 1 "Lamp On" 2 "Reserved" 3 "Not available";
VAL_ 2566719486 EngIdleManagementActiveLampCmd 0 "Lamp Off" 1 "Lamp On" 2 "Reserved" 3 "Not available";
VAL_ 2566719486 EngCoolantLevelLowLampCmd 0 "Lamp Off" 1 "Lamp On" 2 "Reserved" 3 "Not available";
VAL_ 2566719486 EngCoolantTempHighLampCmd 0 "Lamp Off" 1 "Lamp On" 2 "Reserved" 3 "Not available";
VAL_ 2566719486 EngOilPressLowLampCmd 0 "Lamp Off" 1 "Lamp On" 2 "Reserved" 3 "Not available";
VAL_ 2566719486 CmprssnBrkEnblSwtchIndctrLampCmd 0 "Lamp OFF" 1 "Lamp ON" 2 "Reserved" 3 "Not available";
VAL_ 2566719486 EngBrakeActiveLampCmd 0 "Lamp Off" 1 "Lamp On" 2 "Reserved" 3 "Not available";
VAL_ 2566719486 OBDMalfunctionIndicatorLampCmd 0 "Lamp Off" 1 "Lamp On" 2 "Reserved" 3 "Not available";
VAL_ 2566719486 EngRedStopLampCmd 0 "Lamp Off" 1 "Lamp On" 2 "Reserved" 3 "Not available";
VAL_ 2566719486 EngAmberWarningLampCmd 0 "Lamp Off" 1 "Lamp On" 2 "Reserved" 3 "Not available";
VAL_ 2566719486 EngProtectLampCmd 0 "Lamp Off" 1 "Lamp On" 2 "Reserved" 3 "Not available";
VAL_ 2633832702 RolloverSensorType 0 "acceleration sensor" 1 "pressure sensor" 2 "rollrate sensor" 3 "sonic sensor" 4 "fiber-optic sensor" 5 "radar sensor" 6 "lidar sensor" 7 "optical sensor" 14 "Error" 15 "not available";
VAL_ 2633832702 RearCollisionSensor4Type 0 "acceleration sensor" 1 "pressure sensor" 2 "rollrate sensor" 3 "sonic sensor" 4 "fiber-optic sensor" 5 "radar sensor" 6 "lidar sensor" 7 "optical sensor" 14 "Error" 15 "not available";
VAL_ 2633832702 RearCollisionSensor3Type 0 "acceleration sensor" 1 "pressure sensor" 2 "rollrate sensor" 3 "sonic sensor" 4 "fiber-optic sensor" 5 "radar sensor" 6 "lidar sensor" 7 "optical sensor" 14 "Error" 15 "not available";
VAL_ 2633832702 RearCollisionSensor2Type 0 "acceleration sensor" 1 "pressure sensor" 2 "rollrate sensor" 3 "sonic sensor" 4 "fiber-optic sensor" 5 "radar sensor" 6 "lidar sensor" 7 "optical sensor" 14 "Error" 15 "not available";
VAL_ 2633832702 RearCollisionSensor1Type 0 "acceleration sensor" 1 "pressure sensor" 2 "rollrate sensor" 3 "sonic sensor" 4 "fiber-optic sensor" 5 "radar sensor" 6 "lidar sensor" 7 "optical sensor" 14 "Error" 15 "not available";
VAL_ 2633832702 SideCollisionSensorRearRightType 0 "acceleration sensor" 1 "pressure sensor" 2 "rollrate sensor" 3 "sonic sensor" 4 "fiber-optic sensor" 5 "radar sensor" 6 "lidar sensor" 7 "optical sensor" 14 "Error" 15 "not available";
VAL_ 2633832702 SdCllisionSensorMidRearRightType 0 "acceleration sensor" 1 "pressure sensor" 2 "rollrate sensor" 3 "sonic sensor" 4 "fiber-optic sensor" 5 "radar sensor" 6 "lidar sensor" 7 "optical sensor" 14 "Error" 15 "not available";
VAL_ 2633832702 SdCllsionSensorMidFrontRightType 0 "acceleration sensor" 1 "pressure sensor" 2 "rollrate sensor" 3 "sonic sensor" 4 "fiber-optic sensor" 5 "radar sensor" 6 "lidar sensor" 7 "optical sensor" 14 "Error" 15 "not available";
VAL_ 2633832702 SdeCollisionSensorFrontRightType 0 "acceleration sensor" 1 "pressure sensor" 2 "rollrate sensor" 3 "sonic sensor" 4 "fiber-optic sensor" 5 "radar sensor" 6 "lidar sensor" 7 "optical sensor" 14 "Error" 15 "not available";
VAL_ 2633832702 SideCollisionSensorRearLeftType 0 "acceleration sensor" 1 "pressure sensor" 2 "rollrate sensor" 3 "sonic sensor" 4 "fiber-optic sensor" 5 "radar sensor" 6 "lidar sensor" 7 "optical sensor" 14 "Error" 15 "not available";
VAL_ 2633832702 SdCollisionSensorMidRearLeftType 0 "acceleration sensor" 1 "pressure sensor" 2 "rollrate sensor" 3 "sonic sensor" 4 "fiber-optic sensor" 5 "radar sensor" 6 "lidar sensor" 7 "optical sensor" 14 "Error" 15 "not available";
VAL_ 2633832702 SdCllisionSensorMidFrontLeftType 0 "acceleration sensor" 1 "pressure sensor" 2 "rollrate sensor" 3 "sonic sensor" 4 "fiber-optic sensor" 5 "radar sensor" 6 "lidar sensor" 7 "optical sensor" 14 "Error" 15 "not available";
VAL_ 2633832702 SideCollisionSensorFrontLeftType 0 "acceleration sensor" 1 "pressure sensor" 2 "rollrate sensor" 3 "sonic sensor" 4 "fiber-optic sensor" 5 "radar sensor" 6 "lidar sensor" 7 "optical sensor" 14 "Error" 15 "not available";
VAL_ 2633832702 FrontalCollisionSensor4Type 0 "acceleration sensor" 1 "pressure sensor" 2 "rollrate sensor" 3 "sonic sensor" 4 "fiber-optic sensor" 5 "radar sensor" 6 "lidar sensor" 7 "optical sensor" 14 "Error" 15 "not available";
VAL_ 2633832702 FrontalCollisionSensor3Type 0 "acceleration sensor" 1 "pressure sensor" 2 "rollrate sensor" 3 "sonic sensor" 4 "fiber-optic sensor" 5 "radar sensor" 6 "lidar sensor" 7 "optical sensor" 14 "Error" 15 "not available";
VAL_ 2633832702 FrontalCollisionSensor2Type 0 "acceleration sensor" 1 "pressure sensor" 2 "rollrate sensor" 3 "sonic sensor" 4 "fiber-optic sensor" 5 "radar sensor" 6 "lidar sensor" 7 "optical sensor" 14 "Error" 15 "not available";
VAL_ 2633832702 FrontalCollisionSensor1Type 0 "acceleration sensor" 1 "pressure sensor" 2 "rollrate sensor" 3 "sonic sensor" 4 "fiber-optic sensor" 5 "radar sensor" 6 "lidar sensor" 7 "optical sensor" 14 "Error" 15 "not available";
VAL_ 2163223550 CrashType 1 "frontal crash" 2 "rear crash" 4 "side crash, left)" 8 "side crash, right)" 16 "rollover";
VAL_ 2365400830 Joystick9Button9PressedStatus 0 "Button not pressed" 1 "Button pressed" 2 "Error Indicator" 3 "Not Available";
VAL_ 2365400830 Joystick9Button10PressedStatus 0 "Button not pressed" 1 "Button pressed" 2 "Error Indicator" 3 "Not Available";
VAL_ 2365400830 Joystick9Button11PressedStatus 0 "Button not pressed" 1 "Button pressed" 2 "Error Indicator" 3 "Not Available";
VAL_ 2365400830 Joystick9Button12PressedStatus 0 "Button not pressed" 1 "Button pressed" 2 "Error Indicator" 3 "Not Available";
VAL_ 2365400830 Joystick9Button5PressedStatus 0 "Button not pressed" 1 "Button pressed" 2 "Error Indicator" 3 "Not Available";
VAL_ 2365400830 Joystick9Button6PressedStatus 0 "Button not pressed" 1 "Button pressed" 2 "Error Indicator" 3 "Not Available";
VAL_ 2365400830 Joystick9Button7PressedStatus 0 "Button not pressed" 1 "Button pressed" 2 "Error Indicator" 3 "Not Available";
VAL_ 2365400830 Joystick9Button8PressedStatus 0 "Button not pressed" 1 "Button pressed" 2 "Error Indicator" 3 "Not Available";
VAL_ 2365400830 Joystick9Button1PressedStatus 0 "Button not pressed" 1 "Button pressed" 2 "Error Indicator" 3 "Not Available";
VAL_ 2365400830 Joystick9Button2PressedStatus 0 "Button not pressed" 1 "Button pressed" 2 "Error Indicator" 3 "Not Available";
VAL_ 2365400830 Joystick9Button3PressedStatus 0 "Button not pressed" 1 "Button pressed" 2 "Error Indicator" 3 "Not Available";
VAL_ 2365400830 Joystick9Button4PressedStatus 0 "Button not pressed" 1 "Button pressed" 2 "Error Indicator" 3 "Not Available";
VAL_ 2365400830 Joystick9XAxisDetentPosStatus 0 "Not in the Detent Position" 1 "In the Detent Position" 2 "Error Indicator" 3 "Not Available";
VAL_ 2365400830 Joystick9YAxisDetentPosStatus 0 "Not in the Detent Position" 1 "In the Detent Position" 2 "Error Indicator" 3 "Not Available";
VAL_ 2365400830 Jystck9YAxsLvrFrwrdPstvPosStatus 0 "Not on Positive side of Neutral" 1 "On positive side of Neutral" 2 "Error Indicator" 3 "Not Available";
VAL_ 2365400830 Jystck9YAxsLvrBckNgtivePosStatus 0 "Not on negative side of Neutral" 1 "On negative side of Neutral" 2 "Error Indicator" 3 "Not Available";
VAL_ 2365400830 Joystick9YAxisNeutralPosStatus 0 "Not in Neutral Position" 1 "In Neutral Position" 2 "Error Indicator" 3 "Not Available";
VAL_ 2365400830 Jystck9XAxsLvrRghtPstvePosStatus 0 "Not on Positive side of Neutral" 1 "On positive side of Neutral" 2 "Error Indicator" 3 "Not Available";
VAL_ 2365400830 Jystck9XAxsLvrLftNgtivePosStatus 0 "Not on negative side of Neutral" 1 "On negative side of Neutral" 2 "Error Indicator" 3 "Not Available";
VAL_ 2365400830 Joystick9XAxisNeutralPosStatus 0 "Not in Neutral Position" 1 "In Neutral Position" 2 "Error Indicator" 3 "Not Available";
VAL_ 2365401342 Joystick8Button9PressedStatus 0 "Button not pressed" 1 "Button pressed" 2 "Error Indicator" 3 "Not Available";
VAL_ 2365401342 Joystick8Button10PressedStatus 0 "Button not pressed" 1 "Button pressed" 2 "Error Indicator" 3 "Not Available";
VAL_ 2365401342 Joystick8Button11PressedStatus 0 "Button not pressed" 1 "Button pressed" 2 "Error Indicator" 3 "Not Available";
VAL_ 2365401342 Joystick8Button12PressedStatus 0 "Button not pressed" 1 "Button pressed" 2 "Error Indicator" 3 "Not Available";
VAL_ 2365401342 Joystick8Button5PressedStatus 0 "Button not pressed" 1 "Button pressed" 2 "Error Indicator" 3 "Not Available";
VAL_ 2365401342 Joystick8Button6PressedStatus 0 "Button not pressed" 1 "Button pressed" 2 "Error Indicator" 3 "Not Available";
VAL_ 2365401342 Joystick8Button7PressedStatus 0 "Button not pressed" 1 "Button pressed" 2 "Error Indicator" 3 "Not Available";
VAL_ 2365401342 Joystick8Button8PressedStatus 0 "Button not pressed" 1 "Button pressed" 2 "Error Indicator" 3 "Not Available";
VAL_ 2365401342 Joystick8Button1PressedStatus 0 "Button not pressed" 1 "Button pressed" 2 "Error Indicator" 3 "Not Available";
VAL_ 2365401342 Joystick8Button2PressedStatus 0 "Button not pressed" 1 "Button pressed" 2 "Error Indicator" 3 "Not Available";
VAL_ 2365401342 Joystick8Button3PressedStatus 0 "Button not pressed" 1 "Button pressed" 2 "Error Indicator" 3 "Not Available";
VAL_ 2365401342 Joystick8Button4PressedStatus 0 "Button not pressed" 1 "Button pressed" 2 "Error Indicator" 3 "Not Available";
VAL_ 2365401342 Joystick8XAxisDetentPosStatus 0 "Not in the Detent Position" 1 "In the Detent Position" 2 "Error Indicator" 3 "Not Available";
VAL_ 2365401342 Joystick8YAxisDetentPosStatus 0 "Not in the Detent Position" 1 "In the Detent Position" 2 "Error Indicator" 3 "Not Available";
VAL_ 2365401342 Jystck8YAxsLvrFrwrdPstvPosStatus 0 "Not on Positive side of Neutral" 1 "On positive side of Neutral" 2 "Error Indicator" 3 "Not Available";
VAL_ 2365401342 Jystck8YAxsLvrBckNgtivePosStatus 0 "Not on negative side of Neutral" 1 "On negative side of Neutral" 2 "Error Indicator" 3 "Not Available";
VAL_ 2365401342 Joystick8YAxisNeutralPosStatus 0 "Not in Neutral Position" 1 "In Neutral Position" 2 "Error Indicator" 3 "Not Available";
VAL_ 2365401342 Jystck8XAxsLvrRghtPstvePosStatus 0 "Not on Positive side of Neutral" 1 "On positive side of Neutral" 2 "Error Indicator" 3 "Not Available";
VAL_ 2365401342 Jystck8XAxsLvrLftNgtivePosStatus 0 "Not on negative side of Neutral" 1 "On negative side of Neutral" 2 "Error Indicator" 3 "Not Available";
VAL_ 2365401342 Joystick8XAxisNeutralPosStatus 0 "Not in Neutral Position" 1 "In Neutral Position" 2 "Error Indicator" 3 "Not Available";
VAL_ 2365401854 Joystick7Button9PressedStatus 0 "Button not pressed" 1 "Button pressed" 2 "Error Indicator" 3 "Not Available";
VAL_ 2365401854 Joystick7Button10PressedStatus 0 "Button not pressed" 1 "Button pressed" 2 "Error Indicator" 3 "Not Available";
VAL_ 2365401854 Joystick7Button11PressedStatus 0 "Button not pressed" 1 "Button pressed" 2 "Error Indicator" 3 "Not Available";
VAL_ 2365401854 Joystick7Button12PressedStatus 0 "Button not pressed" 1 "Button pressed" 2 "Error Indicator" 3 "Not Available";
VAL_ 2365401854 Joystick7Button5PressedStatus 0 "Button not pressed" 1 "Button pressed" 2 "Error Indicator" 3 "Not Available";
VAL_ 2365401854 Joystick7Button6PressedStatus 0 "Button not pressed" 1 "Button pressed" 2 "Error Indicator" 3 "Not Available";
VAL_ 2365401854 Joystick7Button7PressedStatus 0 "Button not pressed" 1 "Button pressed" 2 "Error Indicator" 3 "Not Available";
VAL_ 2365401854 Joystick7Button8PressedStatus 0 "Button not pressed" 1 "Button pressed" 2 "Error Indicator" 3 "Not Available";
VAL_ 2365401854 Joystick7Button1PressedStatus 0 "Button not pressed" 1 "Button pressed" 2 "Error Indicator" 3 "Not Available";
VAL_ 2365401854 Joystick7Button2PressedStatus 0 "Button not pressed" 1 "Button pressed" 2 "Error Indicator" 3 "Not Available";
VAL_ 2365401854 Joystick7Button3PressedStatus 0 "Button not pressed" 1 "Button pressed" 2 "Error Indicator" 3 "Not Available";
VAL_ 2365401854 Joystick7Button4PressedStatus 0 "Button not pressed" 1 "Button pressed" 2 "Error Indicator" 3 "Not Available";
VAL_ 2365401854 Joystick7XAxisDetentPosStatus 0 "Not in the Detent Position" 1 "In the Detent Position" 2 "Error Indicator" 3 "Not Available";
VAL_ 2365401854 Joystick7YAxisDetentPosStatus 0 "Not in the Detent Position" 1 "In the Detent Position" 2 "Error Indicator" 3 "Not Available";
VAL_ 2365401854 Jystck7YAxsLvrFrwrdPstvPosStatus 0 "Not on Positive side of Neutral" 1 "On positive side of Neutral" 2 "Error Indicator" 3 "Not Available";
VAL_ 2365401854 Jystck7YAxsLvrBckNgtivePosStatus 0 "Not on negative side of Neutral" 1 "On negative side of Neutral" 2 "Error Indicator" 3 "Not Available";
VAL_ 2365401854 Joystick7YAxisNeutralPosStatus 0 "Not in Neutral Position" 1 "In Neutral Position" 2 "Error Indicator" 3 "Not Available";
VAL_ 2365401854 Jystck7XAxsLvrRghtPstvePosStatus 0 "Not on Positive side of Neutral" 1 "On positive side of Neutral" 2 "Error Indicator" 3 "Not Available";
VAL_ 2365401854 Jystck7XAxsLvrLftNgtivePosStatus 0 "Not on negative side of Neutral" 1 "On negative side of Neutral" 2 "Error Indicator" 3 "Not Available";
VAL_ 2365401854 Joystick7XAxisNeutralPosStatus 0 "Not in Neutral Position" 1 "In Neutral Position" 2 "Error Indicator" 3 "Not Available";
VAL_ 2365402366 Joystick6Button9PressedStatus 0 "Button not pressed" 1 "Button pressed" 2 "Error Indicator" 3 "Not Available";
VAL_ 2365402366 Joystick6Button10PressedStatus 0 "Button not pressed" 1 "Button pressed" 2 "Error Indicator" 3 "Not Available";
VAL_ 2365402366 Joystick6Button11PressedStatus 0 "Button not pressed" 1 "Button pressed" 2 "Error Indicator" 3 "Not Available";
VAL_ 2365402366 Joystick6Button12PressedStatus 0 "Button not pressed" 1 "Button pressed" 2 "Error Indicator" 3 "Not Available";
VAL_ 2365402366 Joystick6Button5PressedStatus 0 "Button not pressed" 1 "Button pressed" 2 "Error Indicator" 3 "Not Available";
VAL_ 2365402366 Joystick6Button6PressedStatus 0 "Button not pressed" 1 "Button pressed" 2 "Error Indicator" 3 "Not Available";
VAL_ 2365402366 Joystick6Button7PressedStatus 0 "Button not pressed" 1 "Button pressed" 2 "Error Indicator" 3 "Not Available";
VAL_ 2365402366 Joystick6Button8PressedStatus 0 "Button not pressed" 1 "Button pressed" 2 "Error Indicator" 3 "Not Available";
VAL_ 2365402366 Joystick6Button1PressedStatus 0 "Button not pressed" 1 "Button pressed" 2 "Error Indicator" 3 "Not Available";
VAL_ 2365402366 Joystick6Button2PressedStatus 0 "Button not pressed" 1 "Button pressed" 2 "Error Indicator" 3 "Not Available";
VAL_ 2365402366 Joystick6Button3PressedStatus 0 "Button not pressed" 1 "Button pressed" 2 "Error Indicator" 3 "Not Available";
VAL_ 2365402366 Joystick6Button4PressedStatus 0 "Button not pressed" 1 "Button pressed" 2 "Error Indicator" 3 "Not Available";
VAL_ 2365402366 Joystick6XAxisDetentPosStatus 0 "Not in the Detent Position" 1 "In the Detent Position" 2 "Error Indicator" 3 "Not Available";
VAL_ 2365402366 Joystick6YAxisDetentPosStatus 0 "Not in the Detent Position" 1 "In the Detent Position" 2 "Error Indicator" 3 "Not Available";
VAL_ 2365402366 Jystck6YAxsLvrFrwrdPstvPosStatus 0 "Not on Positive side of Neutral" 1 "On positive side of Neutral" 2 "Error Indicator" 3 "Not Available";
VAL_ 2365402366 Jystck6YAxsLvrBckNgtivePosStatus 0 "Not on negative side of Neutral" 1 "On negative side of Neutral" 2 "Error Indicator" 3 "Not Available";
VAL_ 2365402366 Joystick6YAxisNeutralPosStatus 0 "Not in Neutral Position" 1 "In Neutral Position" 2 "Error Indicator" 3 "Not Available";
VAL_ 2365402366 Jystck6XAxsLvrRghtPstvePosStatus 0 "Not on Positive side of Neutral" 1 "On positive side of Neutral" 2 "Error Indicator" 3 "Not Available";
VAL_ 2365402366 Jystck6XAxsLvrLftNgtivePosStatus 0 "Not on negative side of Neutral" 1 "On negative side of Neutral" 2 "Error Indicator" 3 "Not Available";
VAL_ 2365402366 Joystick6XAxisNeutralPosStatus 0 "Not in Neutral Position" 1 "In Neutral Position" 2 "Error Indicator" 3 "Not Available";
VAL_ 2365402878 Joystick5Button9PressedStatus 0 "Button not pressed" 1 "Button pressed" 2 "Error Indicator" 3 "Not Available";
VAL_ 2365402878 Joystick5Button10PressedStatus 0 "Button not pressed" 1 "Button pressed" 2 "Error Indicator" 3 "Not Available";
VAL_ 2365402878 Joystick5Button11PressedStatus 0 "Button not pressed" 1 "Button pressed" 2 "Error Indicator" 3 "Not Available";
VAL_ 2365402878 Joystick5Button12PressedStatus 0 "Button not pressed" 1 "Button pressed" 2 "Error Indicator" 3 "Not Available";
VAL_ 2365402878 Joystick5Button5PressedStatus 0 "Button not pressed" 1 "Button pressed" 2 "Error Indicator" 3 "Not Available";
VAL_ 2365402878 Joystick5Button6PressedStatus 0 "Button not pressed" 1 "Button pressed" 2 "Error Indicator" 3 "Not Available";
VAL_ 2365402878 Joystick5Button7PressedStatus 0 "Button not pressed" 1 "Button pressed" 2 "Error Indicator" 3 "Not Available";
VAL_ 2365402878 Joystick5Button8PressedStatus 0 "Button not pressed" 1 "Button pressed" 2 "Error Indicator" 3 "Not Available";
VAL_ 2365402878 Joystick5Button1PressedStatus 0 "Button not pressed" 1 "Button pressed" 2 "Error Indicator" 3 "Not Available";
VAL_ 2365402878 Joystick5Button2PressedStatus 0 "Button not pressed" 1 "Button pressed" 2 "Error Indicator" 3 "Not Available";
VAL_ 2365402878 Joystick5Button3PressedStatus 0 "Button not pressed" 1 "Button pressed" 2 "Error Indicator" 3 "Not Available";
VAL_ 2365402878 Joystick5Button4PressedStatus 0 "Button not pressed" 1 "Button pressed" 2 "Error Indicator" 3 "Not Available";
VAL_ 2365402878 Joystick5XAxisDetentPosStatus 0 "Not in the Detent Position" 1 "In the Detent Position" 2 "Error Indicator" 3 "Not Available";
VAL_ 2365402878 Joystick5YAxisDetentPosStatus 0 "Not in the Detent Position" 1 "In the Detent Position" 2 "Error Indicator" 3 "Not Available";
VAL_ 2365402878 Jystck5YAxsLvrFrwrdPstvPosStatus 0 "Not on Positive side of Neutral" 1 "On positive side of Neutral" 2 "Error Indicator" 3 "Not Available";
VAL_ 2365402878 Jystck5YAxsLvrBckNgtivePosStatus 0 "Not on negative side of Neutral" 1 "On negative side of Neutral" 2 "Error Indicator" 3 "Not Available";
VAL_ 2365402878 Joystick5YAxisNeutralPosStatus 0 "Not in Neutral Position" 1 "In Neutral Position" 2 "Error Indicator" 3 "Not Available";
VAL_ 2365402878 Jystck5XAxsLvrRghtPstvePosStatus 0 "Not on Positive side of Neutral" 1 "On positive side of Neutral" 2 "Error Indicator" 3 "Not Available";
VAL_ 2365402878 Jystck5XAxsLvrLftNgtivePosStatus 0 "Not on negative side of Neutral" 1 "On negative side of Neutral" 2 "Error Indicator" 3 "Not Available";
VAL_ 2365402878 Joystick5XAxisNeutralPosStatus 0 "Not in Neutral Position" 1 "In Neutral Position" 2 "Error Indicator" 3 "Not Available";
VAL_ 2365403390 Joystick4Button9PressedStatus 0 "Button not pressed" 1 "Button pressed" 2 "Error Indicator" 3 "Not Available";
VAL_ 2365403390 Joystick4Button10PressedStatus 0 "Button not pressed" 1 "Button pressed" 2 "Error Indicator" 3 "Not Available";
VAL_ 2365403390 Joystick4Button11PressedStatus 0 "Button not pressed" 1 "Button pressed" 2 "Error Indicator" 3 "Not Available";
VAL_ 2365403390 Joystick4Button12PressedStatus 0 "Button not pressed" 1 "Button pressed" 2 "Error Indicator" 3 "Not Available";
VAL_ 2365403390 Joystick4Button5PressedStatus 0 "Button not pressed" 1 "Button pressed" 2 "Error Indicator" 3 "Not Available";
VAL_ 2365403390 Joystick4Button6PressedStatus 0 "Button not pressed" 1 "Button pressed" 2 "Error Indicator" 3 "Not Available";
VAL_ 2365403390 Joystick4Button7PressedStatus 0 "Button not pressed" 1 "Button pressed" 2 "Error Indicator" 3 "Not Available";
VAL_ 2365403390 Joystick4Button8PressedStatus 0 "Button not pressed" 1 "Button pressed" 2 "Error Indicator" 3 "Not Available";
VAL_ 2365403390 Joystick4Button1PressedStatus 0 "Button not pressed" 1 "Button pressed" 2 "Error Indicator" 3 "Not Available";
VAL_ 2365403390 Joystick4Button2PressedStatus 0 "Button not pressed" 1 "Button pressed" 2 "Error Indicator" 3 "Not Available";
VAL_ 2365403390 Joystick4Button3PressedStatus 0 "Button not pressed" 1 "Button pressed" 2 "Error Indicator" 3 "Not Available";
VAL_ 2365403390 Joystick4Button4PressedStatus 0 "Button not pressed" 1 "Button pressed" 2 "Error Indicator" 3 "Not Available";
VAL_ 2365403390 Joystick4XAxisDetentPosStatus 0 "Not in the Detent Position" 1 "In the Detent Position" 2 "Error Indicator" 3 "Not Available";
VAL_ 2365403390 Joystick4YAxisDetentPosStatus 0 "Not in the Detent Position" 1 "In the Detent Position" 2 "Error Indicator" 3 "Not Available";
VAL_ 2365403390 Jystck4YAxsLvrFrwrdPstvPosStatus 0 "Not on Positive side of Neutral" 1 "On positive side of Neutral" 2 "Error Indicator" 3 "Not Available";
VAL_ 2365403390 Jystck4YAxsLvrBckNgtivePosStatus 0 "Not on negative side of Neutral" 1 "On negative side of Neutral" 2 "Error Indicator" 3 "Not Available";
VAL_ 2365403390 Joystick4YAxisNeutralPosStatus 0 "Not in Neutral Position" 1 "In Neutral Position" 2 "Error Indicator" 3 "Not Available";
VAL_ 2365403390 Jystck4XAxsLvrRghtPstvePosStatus 0 "Not on Positive side of Neutral" 1 "On positive side of Neutral" 2 "Error Indicator" 3 "Not Available";
VAL_ 2365403390 Jystck4XAxsLvrLftNgtivePosStatus 0 "Not on negative side of Neutral" 1 "On negative side of Neutral" 2 "Error Indicator" 3 "Not Available";
VAL_ 2365403390 Joystick4XAxisNeutralPosStatus 0 "Not in Neutral Position" 1 "In Neutral Position" 2 "Error Indicator" 3 "Not Available";
VAL_ 2365400318 Joystick10Button9PressedStatus 0 "Button not pressed" 1 "Button pressed" 2 "Error Indicator" 3 "Not Available";
VAL_ 2365400318 Joystick10Button10PressedStatus 0 "Button not pressed" 1 "Button pressed" 2 "Error Indicator" 3 "Not Available";
VAL_ 2365400318 Joystick10Button11PressedStatus 0 "Button not pressed" 1 "Button pressed" 2 "Error Indicator" 3 "Not Available";
VAL_ 2365400318 Joystick10Button12PressedStatus 0 "Button not pressed" 1 "Button pressed" 2 "Error Indicator" 3 "Not Available";
VAL_ 2365400318 Joystick10Button5PressedStatus 0 "Button not pressed" 1 "Button pressed" 2 "Error Indicator" 3 "Not Available";
VAL_ 2365400318 Joystick10Button6PressedStatus 0 "Button not pressed" 1 "Button pressed" 2 "Error Indicator" 3 "Not Available";
VAL_ 2365400318 Joystick10Button7PressedStatus 0 "Button not pressed" 1 "Button pressed" 2 "Error Indicator" 3 "Not Available";
VAL_ 2365400318 Joystick10Button8PressedStatus 0 "Button not pressed" 1 "Button pressed" 2 "Error Indicator" 3 "Not Available";
VAL_ 2365400318 Joystick10Button1PressedStatus 0 "Button not pressed" 1 "Button pressed" 2 "Error Indicator" 3 "Not Available";
VAL_ 2365400318 Joystick10Button2PressedStatus 0 "Button not pressed" 1 "Button pressed" 2 "Error Indicator" 3 "Not Available";
VAL_ 2365400318 Joystick10Button3PressedStatus 0 "Button not pressed" 1 "Button pressed" 2 "Error Indicator" 3 "Not Available";
VAL_ 2365400318 Joystick10Button4PressedStatus 0 "Button not pressed" 1 "Button pressed" 2 "Error Indicator" 3 "Not Available";
VAL_ 2365400318 Joystick10XAxisDetentPosStatus 0 "Not in the Detent Position" 1 "In the Detent Position" 2 "Error Indicator" 3 "Not Available";
VAL_ 2365400318 Joystick10YAxisDetentPosStatus 0 "Not in the Detent Position" 1 "In the Detent Position" 2 "Error Indicator" 3 "Not Available";
VAL_ 2365400318 Jystck10YAxsLvrFrwrdPstvPsStatus 0 "Not on Positive side of Neutral" 1 "On positive side of Neutral" 2 "Error Indicator" 3 "Not Available";
VAL_ 2365400318 Jystck10YAxsLvrBckNgtvePosStatus 0 "Not on negative side of Neutral" 1 "On negative side of Neutral" 2 "Error Indicator" 3 "Not Available";
VAL_ 2365400318 Joystick10YAxisNeutralPosStatus 0 "Not in Neutral Position" 1 "In Neutral Position" 2 "Error Indicator" 3 "Not Available";
VAL_ 2365400318 Jystck10XAxsLvrRghtPstvPosStatus 0 "Not on Positive side of Neutral" 1 "On positive side of Neutral" 2 "Error Indicator" 3 "Not Available";
VAL_ 2365400318 Jystck10XAxsLvrLftNgtvePosStatus 0 "Not on negative side of Neutral" 1 "On negative side of Neutral" 2 "Error Indicator" 3 "Not Available";
VAL_ 2365400318 Joystick10XAxisNeutralPosStatus 0 "Not in Neutral Position" 1 "In Neutral Position" 2 "Error Indicator" 3 "Not Available";
VAL_ 2499614718 PssngrArbgDctivationSwitchStatus 0 "passenger airbag activated" 1 "passenger airbag deactivated" 2 "Error" 3 "not available";
VAL_ 2499614718 Beltlock10Status 0 "unlocked" 1 "locked" 2 "Error" 3 "not available";
VAL_ 2499614718 Beltlock9Status 0 "unlocked" 1 "locked" 2 "Error" 3 "not available";
VAL_ 2499614718 Beltlock8Status 0 "unlocked" 1 "locked" 2 "Error" 3 "not available";
VAL_ 2499614718 Beltlock7Status 0 "unlocked" 1 "locked" 2 "Error" 3 "not available";
VAL_ 2499614718 Beltlock6Status 0 "unlocked" 1 "locked" 2 "Error" 3 "not available";
VAL_ 2499614718 Beltlock5Status 0 "unlocked" 1 "locked" 2 "Error" 3 "not available";
VAL_ 2499614718 Beltlock4Status 0 "unlocked" 1 "locked" 2 "Error" 3 "not available";
VAL_ 2499614718 Beltlock3Status 0 "unlocked" 1 "locked" 2 "Error" 3 "not available";
VAL_ 2499614718 PassengerBeltlockStatus 0 "unlocked" 1 "locked" 2 "Error" 3 "not available";
VAL_ 2499614718 DriverBeltlockStatus 0 "unlocked" 1 "locked" 2 "Error" 3 "not available";
VAL_ 2566722814 BatteryCharger2PowerLineState 0 "Disconnected" 1 "Connected" 2 "Error" 3 "Not available";
VAL_ 2566722814 BatteryCharger2State 0 "Idling" 1 "Charging the battery." 2 "Stand-by or maintaining the battery charge." 13 "Battery failure" 14 "Charger failure" 15 "Not available.";
VAL_ 2566723070 BatteryCharger1PowerLineState 0 "Disconnected" 1 "Connected" 2 "Error" 3 "Not available";
VAL_ 2566723070 BatteryCharger1State 0 "Idling" 1 "Charging the battery." 2 "Stand-by or maintaining the battery charge." 13 "Battery failure" 14 "Charger failure" 15 "Not available.";
